VERSION ""

NS_ :

BS_:

BU_: FBD_HL IPB_App1 FBD_HM FBD_HR FBD_Miko FBD_MM FBD_Trunk FBD_VL FBD_VM FBD_VR Diagnosetool_CAN_FD_IPB_41

BO_ 435 StatusUWBRangingFBD_VR: 32 FBD_VR
 SG_ StatusUWBRangingFBD_VR_SessionID : 0|8@1+ (1.0,0) [0|252] "" FBD_HL,FBD_HM,FBD_HR,FBD_MM,FBD_Miko,FBD_Trunk,FBD_VL,FBD_VM,IPB_App1
 SG_ StatusUWBRangingFBD_VR_TimeOfFli : 8|16@1+ (15.65,0) [0|1000000] "ps" FBD_HL,FBD_HM,FBD_HR,FBD_MM,FBD_Miko,FBD_Trunk,FBD_VL,FBD_VM,IPB_App1
 SG_ StatusUWBRangingFBD_VR_RangingBl : 24|16@1+ (1.0,0) [0|65532] "" FBD_HL,FBD_HM,FBD_HR,FBD_MM,FBD_Miko,FBD_Trunk,FBD_VL,FBD_VM,IPB_App1
 SG_ StatusUWBRangingFBD_VR_RangingRo : 40|8@1+ (1.0,0) [0|252] "" FBD_HL,FBD_HM,FBD_HR,FBD_MM,FBD_Miko,FBD_Trunk,FBD_VL,FBD_VM,IPB_App1
 SG_ StatusUWBRangingFBD_VR_OverallRe : 48|8@1+ (0.5,-127) [-127|-1] "dB" FBD_HL,FBD_HM,FBD_HR,FBD_MM,FBD_Miko,FBD_Trunk,FBD_VL,FBD_VM,IPB_App1
 SG_ StatusUWBRangingFBD_VR_FirstPath : 56|8@1+ (0.5,-127) [-127|-1] "dB" FBD_HL,FBD_HM,FBD_HR,FBD_MM,FBD_Miko,FBD_Trunk,FBD_VL,FBD_VM,IPB_App1
 SG_ StatusUWBRangingFBD_VR_AngleOfAr : 64|8@1+ (1.0,-90) [-90|90] "°" FBD_HL,FBD_HM,FBD_HR,FBD_MM,FBD_Miko,FBD_Trunk,FBD_VL,FBD_VM,IPB_App1
 SG_ StatusUWBRangingFBD_VR_PhaseDiff : 72|8@1+ (1.0,-90) [-90|90] "°" FBD_HL,FBD_HM,FBD_HR,FBD_MM,FBD_Miko,FBD_Trunk,FBD_VL,FBD_VM,IPB_App1
 SG_ StatusUWBRangingFBD_VR_Strongest : 80|8@1+ (0.5,-127) [-127|-1] "dB" FBD_HL,FBD_HM,FBD_HR,FBD_MM,FBD_Miko,FBD_Trunk,FBD_VL,FBD_VM,IPB_App1
 SG_ StatusUWBRangingFBD_VR_BLE_RSSI : 88|8@1+ (0.5,-127) [-127|-1] "dB" FBD_HL,FBD_HM,FBD_HR,FBD_MM,FBD_Miko,FBD_Trunk,FBD_VL,FBD_VM,IPB_App1
 SG_ StatusUWBRangingFBD_VR_Stronge_2 : 96|8@1+ (0.5,0) [0|125] "ns" FBD_HL,FBD_HM,FBD_HR,FBD_MM,FBD_Miko,FBD_Trunk,FBD_VL,FBD_VM,IPB_App1
 SG_ StatusUWBRangingFBD_VR_PDoA_SNR : 104|8@1+ (0.5,0) [0|126] "dB" FBD_HL,FBD_HM,FBD_HR,FBD_MM,FBD_Miko,FBD_Trunk,FBD_VL,FBD_VM,IPB_App1
 SG_ StatusUWBRangingFBD_VR_DutyCycle : 112|8@1+ (1.0,0) [0|100] "%" FBD_HL,FBD_HM,FBD_HR,FBD_MM,FBD_Miko,FBD_Trunk,FBD_VL,FBD_VM,IPB_App1
 SG_ StatusUWBRangingFBD_VR_FinalData : 120|4@1+ (1.0,0) [0|12] "" FBD_HL,FBD_HM,FBD_HR,FBD_MM,FBD_Miko,FBD_Trunk,FBD_VL,FBD_VM,IPB_App1
 SG_ StatusUWBRangingFBD_VR_Antenna : 124|4@1+ (1,0) [0|0] "" FBD_HL,FBD_HM,FBD_HR,FBD_MM,FBD_Miko,FBD_Trunk,FBD_VL,FBD_VM,IPB_App1
 SG_ StatusUWBRangingFBD_VR_Status1 : 128|8@1+ (1,0) [0|0] "" FBD_HL,FBD_HM,FBD_HR,FBD_MM,FBD_Miko,FBD_Trunk,FBD_VL,FBD_VM,IPB_App1
 SG_ StatusUWBRangingFBD_VR_Status2 : 136|8@1+ (1.0,0) [0|252] "" FBD_HL,FBD_HM,FBD_HR,FBD_MM,FBD_Miko,FBD_Trunk,FBD_VL,FBD_VM,IPB_App1
 SG_ StatusUWBRangingFBD_VR_Status3 : 144|8@1+ (1.0,0) [0|252] "" FBD_HL,FBD_HM,FBD_HR,FBD_MM,FBD_Miko,FBD_Trunk,FBD_VL,FBD_VM,IPB_App1
 SG_ StatusUWBRangingFBD_VR_Status4 : 152|8@1+ (1.0,0) [0|252] "" FBD_HL,FBD_HM,FBD_HR,FBD_MM,FBD_Miko,FBD_Trunk,FBD_VL,FBD_VM,IPB_App1
 SG_ StatusUWBRangingFBD_VR_IV00 : 160|8@1+ (1.0,0) [0|255] "" FBD_HL,FBD_HM,FBD_HR,FBD_MM,FBD_Miko,FBD_Trunk,FBD_VL,FBD_VM,IPB_App1
 SG_ StatusUWBRangingFBD_VR_IV01 : 168|8@1+ (1.0,0) [0|255] "" FBD_HL,FBD_HM,FBD_HR,FBD_MM,FBD_Miko,FBD_Trunk,FBD_VL,FBD_VM,IPB_App1
 SG_ StatusUWBRangingFBD_VR_IV02 : 176|8@1+ (1.0,0) [0|255] "" FBD_HL,FBD_HM,FBD_HR,FBD_MM,FBD_Miko,FBD_Trunk,FBD_VL,FBD_VM,IPB_App1
 SG_ StatusUWBRangingFBD_VR_IV03 : 184|8@1+ (1.0,0) [0|255] "" FBD_HL,FBD_HM,FBD_HR,FBD_MM,FBD_Miko,FBD_Trunk,FBD_VL,FBD_VM,IPB_App1
 SG_ StatusUWBRangingFBD_VR_Sign00 : 192|8@1+ (1.0,0) [0|255] "" FBD_HL,FBD_HM,FBD_HR,FBD_MM,FBD_Miko,FBD_Trunk,FBD_VL,FBD_VM,IPB_App1
 SG_ StatusUWBRangingFBD_VR_Sign01 : 200|8@1+ (1.0,0) [0|255] "" FBD_HL,FBD_HM,FBD_HR,FBD_MM,FBD_Miko,FBD_Trunk,FBD_VL,FBD_VM,IPB_App1
 SG_ StatusUWBRangingFBD_VR_Sign02 : 208|8@1+ (1.0,0) [0|255] "" FBD_HL,FBD_HM,FBD_HR,FBD_MM,FBD_Miko,FBD_Trunk,FBD_VL,FBD_VM,IPB_App1
 SG_ StatusUWBRangingFBD_VR_Sign03 : 216|8@1+ (1.0,0) [0|255] "" FBD_HL,FBD_HM,FBD_HR,FBD_MM,FBD_Miko,FBD_Trunk,FBD_VL,FBD_VM,IPB_App1
 SG_ StatusUWBRangingFBD_VR_Sign04 : 224|8@1+ (1.0,0) [0|255] "" FBD_HL,FBD_HM,FBD_HR,FBD_MM,FBD_Miko,FBD_Trunk,FBD_VL,FBD_VM,IPB_App1
 SG_ StatusUWBRangingFBD_VR_Sign05 : 232|8@1+ (1.0,0) [0|255] "" FBD_HL,FBD_HM,FBD_HR,FBD_MM,FBD_Miko,FBD_Trunk,FBD_VL,FBD_VM,IPB_App1
 SG_ StatusUWBRangingFBD_VR_Sign06 : 240|8@1+ (1.0,0) [0|255] "" FBD_HL,FBD_HM,FBD_HR,FBD_MM,FBD_Miko,FBD_Trunk,FBD_VL,FBD_VM,IPB_App1
 SG_ StatusUWBRangingFBD_VR_Sign07 : 248|8@1+ (1.0,0) [0|255] "" FBD_HL,FBD_HM,FBD_HR,FBD_MM,FBD_Miko,FBD_Trunk,FBD_VL,FBD_VM,IPB_App1

BO_ 456 StatusUWBRangingFDD1FBD_HL: 64 FBD_HL
 SG_ StatusUWBRangingFDD1FBD_HL_Sessi : 0|8@1+ (1.0,0) [0|252] "" FBD_HM,FBD_HR,FBD_MM,FBD_Miko,FBD_Trunk,FBD_VL,FBD_VM,FBD_VR,IPB_App1
 SG_ StatusUWBRangingFDD1FBD_HL_UWBSe : 8|32@1+ (1.0,0) [0|4294967292] "" FBD_HM,FBD_HR,FBD_MM,FBD_Miko,FBD_Trunk,FBD_VL,FBD_VM,FBD_VR,IPB_App1
 SG_ StatusUWBRangingFDD1FBD_HL_Rangi : 40|16@1+ (1.0,0) [0|65532] "" FBD_HM,FBD_HR,FBD_MM,FBD_Miko,FBD_Trunk,FBD_VL,FBD_VM,FBD_VR,IPB_App1
 SG_ StatusUWBRangingFDD1FBD_HL_Hoppi : 56|8@1+ (1.0,0) [0|252] "" FBD_HM,FBD_HR,FBD_MM,FBD_Miko,FBD_Trunk,FBD_VL,FBD_VM,FBD_VR,IPB_App1
 SG_ StatusUWBRangingFDD1FBD_HL_Round : 64|16@1+ (1.0,0) [0|65532] "" FBD_HM,FBD_HR,FBD_MM,FBD_Miko,FBD_Trunk,FBD_VL,FBD_VM,FBD_VR,IPB_App1
 SG_ StatusUWBRangingFDD1FBD_HL_Final : 80|32@1+ (1.0,0) [0|4294967292] "" FBD_HM,FBD_HR,FBD_MM,FBD_Miko,FBD_Trunk,FBD_VL,FBD_VM,FBD_VR,IPB_App1
 SG_ StatusUWBRangingFDD1FBD_HL_Fin_2 : 112|32@1+ (1.0,0) [0|4294967292] "" FBD_HM,FBD_HR,FBD_MM,FBD_Miko,FBD_Trunk,FBD_VL,FBD_VM,FBD_VR,IPB_App1
 SG_ StatusUWBRangingFDD1FBD_HL_Numbe : 144|8@1+ (1.0,0) [0|252] "" FBD_HM,FBD_HR,FBD_MM,FBD_Miko,FBD_Trunk,FBD_VL,FBD_VM,FBD_VR,IPB_App1
 SG_ StatusUWBRangingFDD1FBD_HL_Index : 152|8@1+ (1.0,0) [0|252] "" FBD_HM,FBD_HR,FBD_MM,FBD_Miko,FBD_Trunk,FBD_VL,FBD_VM,FBD_VR,IPB_App1
 SG_ StatusUWBRangingFDD1FBD_HL_TimeS : 160|32@1+ (1.0,0) [0|4294967292] "" FBD_HM,FBD_HR,FBD_MM,FBD_Miko,FBD_Trunk,FBD_VL,FBD_VM,FBD_VR,IPB_App1
 SG_ StatusUWBRangingFDD1FBD_HL_Tim_2 : 192|8@1+ (1.0,0) [0|252] "" FBD_HM,FBD_HR,FBD_MM,FBD_Miko,FBD_Trunk,FBD_VL,FBD_VM,FBD_VR,IPB_App1
 SG_ StatusUWBRangingFDD1FBD_HL_Statu : 200|8@1+ (1.0,0) [0|252] "" FBD_HM,FBD_HR,FBD_MM,FBD_Miko,FBD_Trunk,FBD_VL,FBD_VM,FBD_VR,IPB_App1
 SG_ StatusUWBRangingFDD1FBD_HL_Ind_2 : 208|8@1+ (1.0,0) [0|252] "" FBD_HM,FBD_HR,FBD_MM,FBD_Miko,FBD_Trunk,FBD_VL,FBD_VM,FBD_VR,IPB_App1
 SG_ StatusUWBRangingFDD1FBD_HL_Tim_3 : 216|32@1+ (1.0,0) [0|4294967292] "" FBD_HM,FBD_HR,FBD_MM,FBD_Miko,FBD_Trunk,FBD_VL,FBD_VM,FBD_VR,IPB_App1
 SG_ StatusUWBRangingFDD1FBD_HL_Tim_4 : 248|8@1+ (1.0,0) [0|252] "" FBD_HM,FBD_HR,FBD_MM,FBD_Miko,FBD_Trunk,FBD_VL,FBD_VM,FBD_VR,IPB_App1
 SG_ StatusUWBRangingFDD1FBD_HL_Sta_2 : 256|8@1+ (1.0,0) [0|252] "" FBD_HM,FBD_HR,FBD_MM,FBD_Miko,FBD_Trunk,FBD_VL,FBD_VM,FBD_VR,IPB_App1
 SG_ StatusUWBRangingFDD1FBD_HL_Ind_3 : 264|8@1+ (1.0,0) [0|252] "" FBD_HM,FBD_HR,FBD_MM,FBD_Miko,FBD_Trunk,FBD_VL,FBD_VM,FBD_VR,IPB_App1
 SG_ StatusUWBRangingFDD1FBD_HL_Tim_5 : 272|32@1+ (1.0,0) [0|4294967292] "" FBD_HM,FBD_HR,FBD_MM,FBD_Miko,FBD_Trunk,FBD_VL,FBD_VM,FBD_VR,IPB_App1
 SG_ StatusUWBRangingFDD1FBD_HL_Tim_6 : 304|8@1+ (1.0,0) [0|252] "" FBD_HM,FBD_HR,FBD_MM,FBD_Miko,FBD_Trunk,FBD_VL,FBD_VM,FBD_VR,IPB_App1
 SG_ StatusUWBRangingFDD1FBD_HL_Sta_3 : 312|8@1+ (1.0,0) [0|252] "" FBD_HM,FBD_HR,FBD_MM,FBD_Miko,FBD_Trunk,FBD_VL,FBD_VM,FBD_VR,IPB_App1
 SG_ StatusUWBRangingFDD1FBD_HL_Ind_4 : 320|8@1+ (1.0,0) [0|252] "" FBD_HM,FBD_HR,FBD_MM,FBD_Miko,FBD_Trunk,FBD_VL,FBD_VM,FBD_VR,IPB_App1
 SG_ StatusUWBRangingFDD1FBD_HL_Tim_7 : 328|32@1+ (1.0,0) [0|4294967292] "" FBD_HM,FBD_HR,FBD_MM,FBD_Miko,FBD_Trunk,FBD_VL,FBD_VM,FBD_VR,IPB_App1
 SG_ StatusUWBRangingFDD1FBD_HL_Tim_8 : 360|8@1+ (1.0,0) [0|252] "" FBD_HM,FBD_HR,FBD_MM,FBD_Miko,FBD_Trunk,FBD_VL,FBD_VM,FBD_VR,IPB_App1
 SG_ StatusUWBRangingFDD1FBD_HL_Sta_4 : 368|8@1+ (1.0,0) [0|252] "" FBD_HM,FBD_HR,FBD_MM,FBD_Miko,FBD_Trunk,FBD_VL,FBD_VM,FBD_VR,IPB_App1
 SG_ StatusUWBRangingFDD1FBD_HL_Ind_5 : 376|8@1+ (1.0,0) [0|252] "" FBD_HM,FBD_HR,FBD_MM,FBD_Miko,FBD_Trunk,FBD_VL,FBD_VM,FBD_VR,IPB_App1
 SG_ StatusUWBRangingFDD1FBD_HL_Tim_9 : 384|32@1+ (1.0,0) [0|4294967292] "" FBD_HM,FBD_HR,FBD_MM,FBD_Miko,FBD_Trunk,FBD_VL,FBD_VM,FBD_VR,IPB_App1
 SG_ StatusUWBRangingFDD1FBD_HL_Ti_10 : 416|8@1+ (1.0,0) [0|252] "" FBD_HM,FBD_HR,FBD_MM,FBD_Miko,FBD_Trunk,FBD_VL,FBD_VM,FBD_VR,IPB_App1
 SG_ StatusUWBRangingFDD1FBD_HL_Sta_5 : 424|8@1+ (1.0,0) [0|252] "" FBD_HM,FBD_HR,FBD_MM,FBD_Miko,FBD_Trunk,FBD_VL,FBD_VM,FBD_VR,IPB_App1
 SG_ StatusUWBRangingFDD1FBD_HL_Ind_6 : 432|8@1+ (1.0,0) [0|252] "" FBD_HM,FBD_HR,FBD_MM,FBD_Miko,FBD_Trunk,FBD_VL,FBD_VM,FBD_VR,IPB_App1
 SG_ StatusUWBRangingFDD1FBD_HL_Ti_11 : 440|32@1+ (1.0,0) [0|4294967292] "" FBD_HM,FBD_HR,FBD_MM,FBD_Miko,FBD_Trunk,FBD_VL,FBD_VM,FBD_VR,IPB_App1
 SG_ StatusUWBRangingFDD1FBD_HL_Ti_12 : 472|8@1+ (1.0,0) [0|252] "" FBD_HM,FBD_HR,FBD_MM,FBD_Miko,FBD_Trunk,FBD_VL,FBD_VM,FBD_VR,IPB_App1
 SG_ StatusUWBRangingFDD1FBD_HL_Sta_6 : 480|8@1+ (1.0,0) [0|252] "" FBD_HM,FBD_HR,FBD_MM,FBD_Miko,FBD_Trunk,FBD_VL,FBD_VM,FBD_VR,IPB_App1
 SG_ StatusUWBRangingFDD1FBD_HL_IV0 : 488|8@1+ (1.0,0) [0|255] "" FBD_HM,FBD_HR,FBD_MM,FBD_Miko,FBD_Trunk,FBD_VL,FBD_VM,FBD_VR,IPB_App1
 SG_ StatusUWBRangingFDD1FBD_HL_IV1 : 496|8@1+ (1.0,0) [0|255] "" FBD_HM,FBD_HR,FBD_MM,FBD_Miko,FBD_Trunk,FBD_VL,FBD_VM,FBD_VR,IPB_App1

BO_ 451 StatusUWBRangingFDD1FBD_HM: 64 FBD_HM
 SG_ StatusUWBRangingFDD1FBD_HM_Sessi : 0|8@1+ (1.0,0) [0|252] "" FBD_HL,FBD_HR,FBD_MM,FBD_Miko,FBD_Trunk,FBD_VL,FBD_VM,FBD_VR,IPB_App1
 SG_ StatusUWBRangingFDD1FBD_HM_UWBSe : 8|32@1+ (1.0,0) [0|4294967292] "" FBD_HL,FBD_HR,FBD_MM,FBD_Miko,FBD_Trunk,FBD_VL,FBD_VM,FBD_VR,IPB_App1
 SG_ StatusUWBRangingFDD1FBD_HM_Rangi : 40|16@1+ (1.0,0) [0|65532] "" FBD_HL,FBD_HR,FBD_MM,FBD_Miko,FBD_Trunk,FBD_VL,FBD_VM,FBD_VR,IPB_App1
 SG_ StatusUWBRangingFDD1FBD_HM_Hoppi : 56|8@1+ (1.0,0) [0|252] "" FBD_HL,FBD_HR,FBD_MM,FBD_Miko,FBD_Trunk,FBD_VL,FBD_VM,FBD_VR,IPB_App1
 SG_ StatusUWBRangingFDD1FBD_HM_Round : 64|16@1+ (1.0,0) [0|65532] "" FBD_HL,FBD_HR,FBD_MM,FBD_Miko,FBD_Trunk,FBD_VL,FBD_VM,FBD_VR,IPB_App1
 SG_ StatusUWBRangingFDD1FBD_HM_Final : 80|32@1+ (1.0,0) [0|4294967292] "" FBD_HL,FBD_HR,FBD_MM,FBD_Miko,FBD_Trunk,FBD_VL,FBD_VM,FBD_VR,IPB_App1
 SG_ StatusUWBRangingFDD1FBD_HM_Fin_2 : 112|32@1+ (1.0,0) [0|4294967292] "" FBD_HL,FBD_HR,FBD_MM,FBD_Miko,FBD_Trunk,FBD_VL,FBD_VM,FBD_VR,IPB_App1
 SG_ StatusUWBRangingFDD1FBD_HM_Numbe : 144|8@1+ (1.0,0) [0|252] "" FBD_HL,FBD_HR,FBD_MM,FBD_Miko,FBD_Trunk,FBD_VL,FBD_VM,FBD_VR,IPB_App1
 SG_ StatusUWBRangingFDD1FBD_HM_Index : 152|8@1+ (1.0,0) [0|252] "" FBD_HL,FBD_HR,FBD_MM,FBD_Miko,FBD_Trunk,FBD_VL,FBD_VM,FBD_VR,IPB_App1
 SG_ StatusUWBRangingFDD1FBD_HM_TimeS : 160|32@1+ (1.0,0) [0|4294967292] "" FBD_HL,FBD_HR,FBD_MM,FBD_Miko,FBD_Trunk,FBD_VL,FBD_VM,FBD_VR,IPB_App1
 SG_ StatusUWBRangingFDD1FBD_HM_Tim_2 : 192|8@1+ (1.0,0) [0|252] "" FBD_HL,FBD_HR,FBD_MM,FBD_Miko,FBD_Trunk,FBD_VL,FBD_VM,FBD_VR,IPB_App1
 SG_ StatusUWBRangingFDD1FBD_HM_Statu : 200|8@1+ (1.0,0) [0|252] "" FBD_HL,FBD_HR,FBD_MM,FBD_Miko,FBD_Trunk,FBD_VL,FBD_VM,FBD_VR,IPB_App1
 SG_ StatusUWBRangingFDD1FBD_HM_Ind_2 : 208|8@1+ (1.0,0) [0|252] "" FBD_HL,FBD_HR,FBD_MM,FBD_Miko,FBD_Trunk,FBD_VL,FBD_VM,FBD_VR,IPB_App1
 SG_ StatusUWBRangingFDD1FBD_HM_Tim_3 : 216|32@1+ (1.0,0) [0|4294967292] "" FBD_HL,FBD_HR,FBD_MM,FBD_Miko,FBD_Trunk,FBD_VL,FBD_VM,FBD_VR,IPB_App1
 SG_ StatusUWBRangingFDD1FBD_HM_Tim_4 : 248|8@1+ (1.0,0) [0|252] "" FBD_HL,FBD_HR,FBD_MM,FBD_Miko,FBD_Trunk,FBD_VL,FBD_VM,FBD_VR,IPB_App1
 SG_ StatusUWBRangingFDD1FBD_HM_Sta_2 : 256|8@1+ (1.0,0) [0|252] "" FBD_HL,FBD_HR,FBD_MM,FBD_Miko,FBD_Trunk,FBD_VL,FBD_VM,FBD_VR,IPB_App1
 SG_ StatusUWBRangingFDD1FBD_HM_Ind_3 : 264|8@1+ (1.0,0) [0|252] "" FBD_HL,FBD_HR,FBD_MM,FBD_Miko,FBD_Trunk,FBD_VL,FBD_VM,FBD_VR,IPB_App1
 SG_ StatusUWBRangingFDD1FBD_HM_Tim_5 : 272|32@1+ (1.0,0) [0|4294967292] "" FBD_HL,FBD_HR,FBD_MM,FBD_Miko,FBD_Trunk,FBD_VL,FBD_VM,FBD_VR,IPB_App1
 SG_ StatusUWBRangingFDD1FBD_HM_Tim_6 : 304|8@1+ (1.0,0) [0|252] "" FBD_HL,FBD_HR,FBD_MM,FBD_Miko,FBD_Trunk,FBD_VL,FBD_VM,FBD_VR,IPB_App1
 SG_ StatusUWBRangingFDD1FBD_HM_Sta_3 : 312|8@1+ (1.0,0) [0|252] "" FBD_HL,FBD_HR,FBD_MM,FBD_Miko,FBD_Trunk,FBD_VL,FBD_VM,FBD_VR,IPB_App1
 SG_ StatusUWBRangingFDD1FBD_HM_Ind_4 : 320|8@1+ (1.0,0) [0|252] "" FBD_HL,FBD_HR,FBD_MM,FBD_Miko,FBD_Trunk,FBD_VL,FBD_VM,FBD_VR,IPB_App1
 SG_ StatusUWBRangingFDD1FBD_HM_Tim_7 : 328|32@1+ (1.0,0) [0|4294967292] "" FBD_HL,FBD_HR,FBD_MM,FBD_Miko,FBD_Trunk,FBD_VL,FBD_VM,FBD_VR,IPB_App1
 SG_ StatusUWBRangingFDD1FBD_HM_Tim_8 : 360|8@1+ (1.0,0) [0|252] "" FBD_HL,FBD_HR,FBD_MM,FBD_Miko,FBD_Trunk,FBD_VL,FBD_VM,FBD_VR,IPB_App1
 SG_ StatusUWBRangingFDD1FBD_HM_Sta_4 : 368|8@1+ (1.0,0) [0|252] "" FBD_HL,FBD_HR,FBD_MM,FBD_Miko,FBD_Trunk,FBD_VL,FBD_VM,FBD_VR,IPB_App1
 SG_ StatusUWBRangingFDD1FBD_HM_Ind_5 : 376|8@1+ (1.0,0) [0|252] "" FBD_HL,FBD_HR,FBD_MM,FBD_Miko,FBD_Trunk,FBD_VL,FBD_VM,FBD_VR,IPB_App1
 SG_ StatusUWBRangingFDD1FBD_HM_Tim_9 : 384|32@1+ (1.0,0) [0|4294967292] "" FBD_HL,FBD_HR,FBD_MM,FBD_Miko,FBD_Trunk,FBD_VL,FBD_VM,FBD_VR,IPB_App1
 SG_ StatusUWBRangingFDD1FBD_HM_Ti_10 : 416|8@1+ (1.0,0) [0|252] "" FBD_HL,FBD_HR,FBD_MM,FBD_Miko,FBD_Trunk,FBD_VL,FBD_VM,FBD_VR,IPB_App1
 SG_ StatusUWBRangingFDD1FBD_HM_Sta_5 : 424|8@1+ (1.0,0) [0|252] "" FBD_HL,FBD_HR,FBD_MM,FBD_Miko,FBD_Trunk,FBD_VL,FBD_VM,FBD_VR,IPB_App1
 SG_ StatusUWBRangingFDD1FBD_HM_Ind_6 : 432|8@1+ (1.0,0) [0|252] "" FBD_HL,FBD_HR,FBD_MM,FBD_Miko,FBD_Trunk,FBD_VL,FBD_VM,FBD_VR,IPB_App1
 SG_ StatusUWBRangingFDD1FBD_HM_Ti_11 : 440|32@1+ (1.0,0) [0|4294967292] "" FBD_HL,FBD_HR,FBD_MM,FBD_Miko,FBD_Trunk,FBD_VL,FBD_VM,FBD_VR,IPB_App1
 SG_ StatusUWBRangingFDD1FBD_HM_Ti_12 : 472|8@1+ (1.0,0) [0|252] "" FBD_HL,FBD_HR,FBD_MM,FBD_Miko,FBD_Trunk,FBD_VL,FBD_VM,FBD_VR,IPB_App1
 SG_ StatusUWBRangingFDD1FBD_HM_Sta_6 : 480|8@1+ (1.0,0) [0|252] "" FBD_HL,FBD_HR,FBD_MM,FBD_Miko,FBD_Trunk,FBD_VL,FBD_VM,FBD_VR,IPB_App1
 SG_ StatusUWBRangingFDD1FBD_HM_IV0 : 488|8@1+ (1.0,0) [0|255] "" FBD_HL,FBD_HR,FBD_MM,FBD_Miko,FBD_Trunk,FBD_VL,FBD_VM,FBD_VR,IPB_App1
 SG_ StatusUWBRangingFDD1FBD_HM_IV1 : 496|8@1+ (1.0,0) [0|255] "" FBD_HL,FBD_HR,FBD_MM,FBD_Miko,FBD_Trunk,FBD_VL,FBD_VM,FBD_VR,IPB_App1

BO_ 457 StatusUWBRangingFDD1FBD_HR: 64 FBD_HR
 SG_ StatusUWBRangingFDD1FBD_HR_Sessi : 0|8@1+ (1.0,0) [0|252] "" FBD_HL,FBD_HM,FBD_MM,FBD_Miko,FBD_Trunk,FBD_VL,FBD_VM,FBD_VR,IPB_App1
 SG_ StatusUWBRangingFDD1FBD_HR_UWBSe : 8|32@1+ (1.0,0) [0|4294967292] "" FBD_HL,FBD_HM,FBD_MM,FBD_Miko,FBD_Trunk,FBD_VL,FBD_VM,FBD_VR,IPB_App1
 SG_ StatusUWBRangingFDD1FBD_HR_Rangi : 40|16@1+ (1.0,0) [0|65532] "" FBD_HL,FBD_HM,FBD_MM,FBD_Miko,FBD_Trunk,FBD_VL,FBD_VM,FBD_VR,IPB_App1
 SG_ StatusUWBRangingFDD1FBD_HR_Hoppi : 56|8@1+ (1.0,0) [0|252] "" FBD_HL,FBD_HM,FBD_MM,FBD_Miko,FBD_Trunk,FBD_VL,FBD_VM,FBD_VR,IPB_App1
 SG_ StatusUWBRangingFDD1FBD_HR_Round : 64|16@1+ (1.0,0) [0|65532] "" FBD_HL,FBD_HM,FBD_MM,FBD_Miko,FBD_Trunk,FBD_VL,FBD_VM,FBD_VR,IPB_App1
 SG_ StatusUWBRangingFDD1FBD_HR_Final : 80|32@1+ (1.0,0) [0|4294967292] "" FBD_HL,FBD_HM,FBD_MM,FBD_Miko,FBD_Trunk,FBD_VL,FBD_VM,FBD_VR,IPB_App1
 SG_ StatusUWBRangingFDD1FBD_HR_Fin_2 : 112|32@1+ (1.0,0) [0|4294967292] "" FBD_HL,FBD_HM,FBD_MM,FBD_Miko,FBD_Trunk,FBD_VL,FBD_VM,FBD_VR,IPB_App1
 SG_ StatusUWBRangingFDD1FBD_HR_Numbe : 144|8@1+ (1.0,0) [0|252] "" FBD_HL,FBD_HM,FBD_MM,FBD_Miko,FBD_Trunk,FBD_VL,FBD_VM,FBD_VR,IPB_App1
 SG_ StatusUWBRangingFDD1FBD_HR_Index : 152|8@1+ (1.0,0) [0|252] "" FBD_HL,FBD_HM,FBD_MM,FBD_Miko,FBD_Trunk,FBD_VL,FBD_VM,FBD_VR,IPB_App1
 SG_ StatusUWBRangingFDD1FBD_HR_TimeS : 160|32@1+ (1.0,0) [0|4294967292] "" FBD_HL,FBD_HM,FBD_MM,FBD_Miko,FBD_Trunk,FBD_VL,FBD_VM,FBD_VR,IPB_App1
 SG_ StatusUWBRangingFDD1FBD_HR_Tim_2 : 192|8@1+ (1.0,0) [0|252] "" FBD_HL,FBD_HM,FBD_MM,FBD_Miko,FBD_Trunk,FBD_VL,FBD_VM,FBD_VR,IPB_App1
 SG_ StatusUWBRangingFDD1FBD_HR_Statu : 200|8@1+ (1.0,0) [0|252] "" FBD_HL,FBD_HM,FBD_MM,FBD_Miko,FBD_Trunk,FBD_VL,FBD_VM,FBD_VR,IPB_App1
 SG_ StatusUWBRangingFDD1FBD_HR_Ind_2 : 208|8@1+ (1.0,0) [0|252] "" FBD_HL,FBD_HM,FBD_MM,FBD_Miko,FBD_Trunk,FBD_VL,FBD_VM,FBD_VR,IPB_App1
 SG_ StatusUWBRangingFDD1FBD_HR_Tim_3 : 216|32@1+ (1.0,0) [0|4294967292] "" FBD_HL,FBD_HM,FBD_MM,FBD_Miko,FBD_Trunk,FBD_VL,FBD_VM,FBD_VR,IPB_App1
 SG_ StatusUWBRangingFDD1FBD_HR_Tim_4 : 248|8@1+ (1.0,0) [0|252] "" FBD_HL,FBD_HM,FBD_MM,FBD_Miko,FBD_Trunk,FBD_VL,FBD_VM,FBD_VR,IPB_App1
 SG_ StatusUWBRangingFDD1FBD_HR_Sta_2 : 256|8@1+ (1.0,0) [0|252] "" FBD_HL,FBD_HM,FBD_MM,FBD_Miko,FBD_Trunk,FBD_VL,FBD_VM,FBD_VR,IPB_App1
 SG_ StatusUWBRangingFDD1FBD_HR_Ind_3 : 264|8@1+ (1.0,0) [0|252] "" FBD_HL,FBD_HM,FBD_MM,FBD_Miko,FBD_Trunk,FBD_VL,FBD_VM,FBD_VR,IPB_App1
 SG_ StatusUWBRangingFDD1FBD_HR_Tim_5 : 272|32@1+ (1.0,0) [0|4294967292] "" FBD_HL,FBD_HM,FBD_MM,FBD_Miko,FBD_Trunk,FBD_VL,FBD_VM,FBD_VR,IPB_App1
 SG_ StatusUWBRangingFDD1FBD_HR_Tim_6 : 304|8@1+ (1.0,0) [0|252] "" FBD_HL,FBD_HM,FBD_MM,FBD_Miko,FBD_Trunk,FBD_VL,FBD_VM,FBD_VR,IPB_App1
 SG_ StatusUWBRangingFDD1FBD_HR_Sta_3 : 312|8@1+ (1.0,0) [0|252] "" FBD_HL,FBD_HM,FBD_MM,FBD_Miko,FBD_Trunk,FBD_VL,FBD_VM,FBD_VR,IPB_App1
 SG_ StatusUWBRangingFDD1FBD_HR_Ind_4 : 320|8@1+ (1.0,0) [0|252] "" FBD_HL,FBD_HM,FBD_MM,FBD_Miko,FBD_Trunk,FBD_VL,FBD_VM,FBD_VR,IPB_App1
 SG_ StatusUWBRangingFDD1FBD_HR_Tim_7 : 328|32@1+ (1.0,0) [0|4294967292] "" FBD_HL,FBD_HM,FBD_MM,FBD_Miko,FBD_Trunk,FBD_VL,FBD_VM,FBD_VR,IPB_App1
 SG_ StatusUWBRangingFDD1FBD_HR_Tim_8 : 360|8@1+ (1.0,0) [0|252] "" FBD_HL,FBD_HM,FBD_MM,FBD_Miko,FBD_Trunk,FBD_VL,FBD_VM,FBD_VR,IPB_App1
 SG_ StatusUWBRangingFDD1FBD_HR_Sta_4 : 368|8@1+ (1.0,0) [0|252] "" FBD_HL,FBD_HM,FBD_MM,FBD_Miko,FBD_Trunk,FBD_VL,FBD_VM,FBD_VR,IPB_App1
 SG_ StatusUWBRangingFDD1FBD_HR_Ind_5 : 376|8@1+ (1.0,0) [0|252] "" FBD_HL,FBD_HM,FBD_MM,FBD_Miko,FBD_Trunk,FBD_VL,FBD_VM,FBD_VR,IPB_App1
 SG_ StatusUWBRangingFDD1FBD_HR_Tim_9 : 384|32@1+ (1.0,0) [0|4294967292] "" FBD_HL,FBD_HM,FBD_MM,FBD_Miko,FBD_Trunk,FBD_VL,FBD_VM,FBD_VR,IPB_App1
 SG_ StatusUWBRangingFDD1FBD_HR_Ti_10 : 416|8@1+ (1.0,0) [0|252] "" FBD_HL,FBD_HM,FBD_MM,FBD_Miko,FBD_Trunk,FBD_VL,FBD_VM,FBD_VR,IPB_App1
 SG_ StatusUWBRangingFDD1FBD_HR_Sta_5 : 424|8@1+ (1.0,0) [0|252] "" FBD_HL,FBD_HM,FBD_MM,FBD_Miko,FBD_Trunk,FBD_VL,FBD_VM,FBD_VR,IPB_App1
 SG_ StatusUWBRangingFDD1FBD_HR_Ind_6 : 432|8@1+ (1.0,0) [0|252] "" FBD_HL,FBD_HM,FBD_MM,FBD_Miko,FBD_Trunk,FBD_VL,FBD_VM,FBD_VR,IPB_App1
 SG_ StatusUWBRangingFDD1FBD_HR_Ti_11 : 440|32@1+ (1.0,0) [0|4294967292] "" FBD_HL,FBD_HM,FBD_MM,FBD_Miko,FBD_Trunk,FBD_VL,FBD_VM,FBD_VR,IPB_App1
 SG_ StatusUWBRangingFDD1FBD_HR_Ti_12 : 472|8@1+ (1.0,0) [0|252] "" FBD_HL,FBD_HM,FBD_MM,FBD_Miko,FBD_Trunk,FBD_VL,FBD_VM,FBD_VR,IPB_App1
 SG_ StatusUWBRangingFDD1FBD_HR_Sta_6 : 480|8@1+ (1.0,0) [0|252] "" FBD_HL,FBD_HM,FBD_MM,FBD_Miko,FBD_Trunk,FBD_VL,FBD_VM,FBD_VR,IPB_App1
 SG_ StatusUWBRangingFDD1FBD_HR_IV0 : 488|8@1+ (1.0,0) [0|255] "" FBD_HL,FBD_HM,FBD_MM,FBD_Miko,FBD_Trunk,FBD_VL,FBD_VM,FBD_VR,IPB_App1
 SG_ StatusUWBRangingFDD1FBD_HR_IV1 : 496|8@1+ (1.0,0) [0|255] "" FBD_HL,FBD_HM,FBD_MM,FBD_Miko,FBD_Trunk,FBD_VL,FBD_VM,FBD_VR,IPB_App1

BO_ 452 StatusUWBRangingFDD1FBD_Miko: 64 FBD_Miko
 SG_ StatusUWBRangingFDD1FBD_Miko_Ses : 0|8@1+ (1.0,0) [0|252] "" FBD_HL,FBD_HM,FBD_HR,FBD_MM,FBD_Trunk,FBD_VL,FBD_VM,FBD_VR,IPB_App1
 SG_ StatusUWBRangingFDD1FBD_Miko_UWB : 8|32@1+ (1.0,0) [0|4294967292] "" FBD_HL,FBD_HM,FBD_HR,FBD_MM,FBD_Trunk,FBD_VL,FBD_VM,FBD_VR,IPB_App1
 SG_ StatusUWBRangingFDD1FBD_Miko_Ran : 40|16@1+ (1.0,0) [0|65532] "" FBD_HL,FBD_HM,FBD_HR,FBD_MM,FBD_Trunk,FBD_VL,FBD_VM,FBD_VR,IPB_App1
 SG_ StatusUWBRangingFDD1FBD_Miko_Hop : 56|8@1+ (1.0,0) [0|252] "" FBD_HL,FBD_HM,FBD_HR,FBD_MM,FBD_Trunk,FBD_VL,FBD_VM,FBD_VR,IPB_App1
 SG_ StatusUWBRangingFDD1FBD_Miko_Rou : 64|16@1+ (1.0,0) [0|65532] "" FBD_HL,FBD_HM,FBD_HR,FBD_MM,FBD_Trunk,FBD_VL,FBD_VM,FBD_VR,IPB_App1
 SG_ StatusUWBRangingFDD1FBD_Miko_Fin : 80|32@1+ (1.0,0) [0|4294967292] "" FBD_HL,FBD_HM,FBD_HR,FBD_MM,FBD_Trunk,FBD_VL,FBD_VM,FBD_VR,IPB_App1
 SG_ StatusUWBRangingFDD1FBD_Miko_F_2 : 112|32@1+ (1.0,0) [0|4294967292] "" FBD_HL,FBD_HM,FBD_HR,FBD_MM,FBD_Trunk,FBD_VL,FBD_VM,FBD_VR,IPB_App1
 SG_ StatusUWBRangingFDD1FBD_Miko_Num : 144|8@1+ (1.0,0) [0|252] "" FBD_HL,FBD_HM,FBD_HR,FBD_MM,FBD_Trunk,FBD_VL,FBD_VM,FBD_VR,IPB_App1
 SG_ StatusUWBRangingFDD1FBD_Miko_Ind : 152|8@1+ (1.0,0) [0|252] "" FBD_HL,FBD_HM,FBD_HR,FBD_MM,FBD_Trunk,FBD_VL,FBD_VM,FBD_VR,IPB_App1
 SG_ StatusUWBRangingFDD1FBD_Miko_Tim : 160|32@1+ (1.0,0) [0|4294967292] "" FBD_HL,FBD_HM,FBD_HR,FBD_MM,FBD_Trunk,FBD_VL,FBD_VM,FBD_VR,IPB_App1
 SG_ StatusUWBRangingFDD1FBD_Miko_T_2 : 192|8@1+ (1.0,0) [0|252] "" FBD_HL,FBD_HM,FBD_HR,FBD_MM,FBD_Trunk,FBD_VL,FBD_VM,FBD_VR,IPB_App1
 SG_ StatusUWBRangingFDD1FBD_Miko_Sta : 200|8@1+ (1.0,0) [0|252] "" FBD_HL,FBD_HM,FBD_HR,FBD_MM,FBD_Trunk,FBD_VL,FBD_VM,FBD_VR,IPB_App1
 SG_ StatusUWBRangingFDD1FBD_Miko_I_2 : 208|8@1+ (1.0,0) [0|252] "" FBD_HL,FBD_HM,FBD_HR,FBD_MM,FBD_Trunk,FBD_VL,FBD_VM,FBD_VR,IPB_App1
 SG_ StatusUWBRangingFDD1FBD_Miko_T_3 : 216|32@1+ (1.0,0) [0|4294967292] "" FBD_HL,FBD_HM,FBD_HR,FBD_MM,FBD_Trunk,FBD_VL,FBD_VM,FBD_VR,IPB_App1
 SG_ StatusUWBRangingFDD1FBD_Miko_T_4 : 248|8@1+ (1.0,0) [0|252] "" FBD_HL,FBD_HM,FBD_HR,FBD_MM,FBD_Trunk,FBD_VL,FBD_VM,FBD_VR,IPB_App1
 SG_ StatusUWBRangingFDD1FBD_Miko_S_2 : 256|8@1+ (1.0,0) [0|252] "" FBD_HL,FBD_HM,FBD_HR,FBD_MM,FBD_Trunk,FBD_VL,FBD_VM,FBD_VR,IPB_App1
 SG_ StatusUWBRangingFDD1FBD_Miko_I_3 : 264|8@1+ (1.0,0) [0|252] "" FBD_HL,FBD_HM,FBD_HR,FBD_MM,FBD_Trunk,FBD_VL,FBD_VM,FBD_VR,IPB_App1
 SG_ StatusUWBRangingFDD1FBD_Miko_T_5 : 272|32@1+ (1.0,0) [0|4294967292] "" FBD_HL,FBD_HM,FBD_HR,FBD_MM,FBD_Trunk,FBD_VL,FBD_VM,FBD_VR,IPB_App1
 SG_ StatusUWBRangingFDD1FBD_Miko_T_6 : 304|8@1+ (1.0,0) [0|252] "" FBD_HL,FBD_HM,FBD_HR,FBD_MM,FBD_Trunk,FBD_VL,FBD_VM,FBD_VR,IPB_App1
 SG_ StatusUWBRangingFDD1FBD_Miko_S_3 : 312|8@1+ (1.0,0) [0|252] "" FBD_HL,FBD_HM,FBD_HR,FBD_MM,FBD_Trunk,FBD_VL,FBD_VM,FBD_VR,IPB_App1
 SG_ StatusUWBRangingFDD1FBD_Miko_I_4 : 320|8@1+ (1.0,0) [0|252] "" FBD_HL,FBD_HM,FBD_HR,FBD_MM,FBD_Trunk,FBD_VL,FBD_VM,FBD_VR,IPB_App1
 SG_ StatusUWBRangingFDD1FBD_Miko_T_7 : 328|32@1+ (1.0,0) [0|4294967292] "" FBD_HL,FBD_HM,FBD_HR,FBD_MM,FBD_Trunk,FBD_VL,FBD_VM,FBD_VR,IPB_App1
 SG_ StatusUWBRangingFDD1FBD_Miko_T_8 : 360|8@1+ (1.0,0) [0|252] "" FBD_HL,FBD_HM,FBD_HR,FBD_MM,FBD_Trunk,FBD_VL,FBD_VM,FBD_VR,IPB_App1
 SG_ StatusUWBRangingFDD1FBD_Miko_S_4 : 368|8@1+ (1.0,0) [0|252] "" FBD_HL,FBD_HM,FBD_HR,FBD_MM,FBD_Trunk,FBD_VL,FBD_VM,FBD_VR,IPB_App1
 SG_ StatusUWBRangingFDD1FBD_Miko_I_5 : 376|8@1+ (1.0,0) [0|252] "" FBD_HL,FBD_HM,FBD_HR,FBD_MM,FBD_Trunk,FBD_VL,FBD_VM,FBD_VR,IPB_App1
 SG_ StatusUWBRangingFDD1FBD_Miko_T_9 : 384|32@1+ (1.0,0) [0|4294967292] "" FBD_HL,FBD_HM,FBD_HR,FBD_MM,FBD_Trunk,FBD_VL,FBD_VM,FBD_VR,IPB_App1
 SG_ StatusUWBRangingFDD1FBD_Miko__10 : 416|8@1+ (1.0,0) [0|252] "" FBD_HL,FBD_HM,FBD_HR,FBD_MM,FBD_Trunk,FBD_VL,FBD_VM,FBD_VR,IPB_App1
 SG_ StatusUWBRangingFDD1FBD_Miko_S_5 : 424|8@1+ (1.0,0) [0|252] "" FBD_HL,FBD_HM,FBD_HR,FBD_MM,FBD_Trunk,FBD_VL,FBD_VM,FBD_VR,IPB_App1
 SG_ StatusUWBRangingFDD1FBD_Miko_I_6 : 432|8@1+ (1.0,0) [0|252] "" FBD_HL,FBD_HM,FBD_HR,FBD_MM,FBD_Trunk,FBD_VL,FBD_VM,FBD_VR,IPB_App1
 SG_ StatusUWBRangingFDD1FBD_Miko__11 : 440|32@1+ (1.0,0) [0|4294967292] "" FBD_HL,FBD_HM,FBD_HR,FBD_MM,FBD_Trunk,FBD_VL,FBD_VM,FBD_VR,IPB_App1
 SG_ StatusUWBRangingFDD1FBD_Miko__12 : 472|8@1+ (1.0,0) [0|252] "" FBD_HL,FBD_HM,FBD_HR,FBD_MM,FBD_Trunk,FBD_VL,FBD_VM,FBD_VR,IPB_App1
 SG_ StatusUWBRangingFDD1FBD_Miko_S_6 : 480|8@1+ (1.0,0) [0|252] "" FBD_HL,FBD_HM,FBD_HR,FBD_MM,FBD_Trunk,FBD_VL,FBD_VM,FBD_VR,IPB_App1
 SG_ StatusUWBRangingFDD1FBD_Miko_IV0 : 488|8@1+ (1.0,0) [0|255] "" FBD_HL,FBD_HM,FBD_HR,FBD_MM,FBD_Trunk,FBD_VL,FBD_VM,FBD_VR,IPB_App1
 SG_ StatusUWBRangingFDD1FBD_Miko_IV1 : 496|8@1+ (1.0,0) [0|255] "" FBD_HL,FBD_HM,FBD_HR,FBD_MM,FBD_Trunk,FBD_VL,FBD_VM,FBD_VR,IPB_App1

BO_ 444 StatusUWBRangingFDD1FBD_MM: 64 FBD_MM
 SG_ StatusUWBRangingFDD1FBD_MM_Sessi : 0|8@1+ (1.0,0) [0|252] "" FBD_HL,FBD_HM,FBD_HR,FBD_Miko,FBD_Trunk,FBD_VL,FBD_VM,FBD_VR,IPB_App1
 SG_ StatusUWBRangingFDD1FBD_MM_UWBSe : 8|32@1+ (1.0,0) [0|4294967292] "" FBD_HL,FBD_HM,FBD_HR,FBD_Miko,FBD_Trunk,FBD_VL,FBD_VM,FBD_VR,IPB_App1
 SG_ StatusUWBRangingFDD1FBD_MM_Rangi : 40|16@1+ (1.0,0) [0|65532] "" FBD_HL,FBD_HM,FBD_HR,FBD_Miko,FBD_Trunk,FBD_VL,FBD_VM,FBD_VR,IPB_App1
 SG_ StatusUWBRangingFDD1FBD_MM_Hoppi : 56|8@1+ (1.0,0) [0|252] "" FBD_HL,FBD_HM,FBD_HR,FBD_Miko,FBD_Trunk,FBD_VL,FBD_VM,FBD_VR,IPB_App1
 SG_ StatusUWBRangingFDD1FBD_MM_Round : 64|16@1+ (1.0,0) [0|65532] "" FBD_HL,FBD_HM,FBD_HR,FBD_Miko,FBD_Trunk,FBD_VL,FBD_VM,FBD_VR,IPB_App1
 SG_ StatusUWBRangingFDD1FBD_MM_Final : 80|32@1+ (1.0,0) [0|4294967292] "" FBD_HL,FBD_HM,FBD_HR,FBD_Miko,FBD_Trunk,FBD_VL,FBD_VM,FBD_VR,IPB_App1
 SG_ StatusUWBRangingFDD1FBD_MM_Fin_2 : 112|32@1+ (1.0,0) [0|4294967292] "" FBD_HL,FBD_HM,FBD_HR,FBD_Miko,FBD_Trunk,FBD_VL,FBD_VM,FBD_VR,IPB_App1
 SG_ StatusUWBRangingFDD1FBD_MM_Numbe : 144|8@1+ (1.0,0) [0|252] "" FBD_HL,FBD_HM,FBD_HR,FBD_Miko,FBD_Trunk,FBD_VL,FBD_VM,FBD_VR,IPB_App1
 SG_ StatusUWBRangingFDD1FBD_MM_Index : 152|8@1+ (1.0,0) [0|252] "" FBD_HL,FBD_HM,FBD_HR,FBD_Miko,FBD_Trunk,FBD_VL,FBD_VM,FBD_VR,IPB_App1
 SG_ StatusUWBRangingFDD1FBD_MM_TimeS : 160|32@1+ (1.0,0) [0|4294967292] "" FBD_HL,FBD_HM,FBD_HR,FBD_Miko,FBD_Trunk,FBD_VL,FBD_VM,FBD_VR,IPB_App1
 SG_ StatusUWBRangingFDD1FBD_MM_Tim_2 : 192|8@1+ (1.0,0) [0|252] "" FBD_HL,FBD_HM,FBD_HR,FBD_Miko,FBD_Trunk,FBD_VL,FBD_VM,FBD_VR,IPB_App1
 SG_ StatusUWBRangingFDD1FBD_MM_Statu : 200|8@1+ (1.0,0) [0|252] "" FBD_HL,FBD_HM,FBD_HR,FBD_Miko,FBD_Trunk,FBD_VL,FBD_VM,FBD_VR,IPB_App1
 SG_ StatusUWBRangingFDD1FBD_MM_Ind_2 : 208|8@1+ (1.0,0) [0|252] "" FBD_HL,FBD_HM,FBD_HR,FBD_Miko,FBD_Trunk,FBD_VL,FBD_VM,FBD_VR,IPB_App1
 SG_ StatusUWBRangingFDD1FBD_MM_Tim_3 : 216|32@1+ (1.0,0) [0|4294967292] "" FBD_HL,FBD_HM,FBD_HR,FBD_Miko,FBD_Trunk,FBD_VL,FBD_VM,FBD_VR,IPB_App1
 SG_ StatusUWBRangingFDD1FBD_MM_Tim_4 : 248|8@1+ (1.0,0) [0|252] "" FBD_HL,FBD_HM,FBD_HR,FBD_Miko,FBD_Trunk,FBD_VL,FBD_VM,FBD_VR,IPB_App1
 SG_ StatusUWBRangingFDD1FBD_MM_Sta_2 : 256|8@1+ (1.0,0) [0|252] "" FBD_HL,FBD_HM,FBD_HR,FBD_Miko,FBD_Trunk,FBD_VL,FBD_VM,FBD_VR,IPB_App1
 SG_ StatusUWBRangingFDD1FBD_MM_Ind_3 : 264|8@1+ (1.0,0) [0|252] "" FBD_HL,FBD_HM,FBD_HR,FBD_Miko,FBD_Trunk,FBD_VL,FBD_VM,FBD_VR,IPB_App1
 SG_ StatusUWBRangingFDD1FBD_MM_Tim_5 : 272|32@1+ (1.0,0) [0|4294967292] "" FBD_HL,FBD_HM,FBD_HR,FBD_Miko,FBD_Trunk,FBD_VL,FBD_VM,FBD_VR,IPB_App1
 SG_ StatusUWBRangingFDD1FBD_MM_Tim_6 : 304|8@1+ (1.0,0) [0|252] "" FBD_HL,FBD_HM,FBD_HR,FBD_Miko,FBD_Trunk,FBD_VL,FBD_VM,FBD_VR,IPB_App1
 SG_ StatusUWBRangingFDD1FBD_MM_Sta_3 : 312|8@1+ (1.0,0) [0|252] "" FBD_HL,FBD_HM,FBD_HR,FBD_Miko,FBD_Trunk,FBD_VL,FBD_VM,FBD_VR,IPB_App1
 SG_ StatusUWBRangingFDD1FBD_MM_Ind_4 : 320|8@1+ (1.0,0) [0|252] "" FBD_HL,FBD_HM,FBD_HR,FBD_Miko,FBD_Trunk,FBD_VL,FBD_VM,FBD_VR,IPB_App1
 SG_ StatusUWBRangingFDD1FBD_MM_Tim_7 : 328|32@1+ (1.0,0) [0|4294967292] "" FBD_HL,FBD_HM,FBD_HR,FBD_Miko,FBD_Trunk,FBD_VL,FBD_VM,FBD_VR,IPB_App1
 SG_ StatusUWBRangingFDD1FBD_MM_Tim_8 : 360|8@1+ (1.0,0) [0|252] "" FBD_HL,FBD_HM,FBD_HR,FBD_Miko,FBD_Trunk,FBD_VL,FBD_VM,FBD_VR,IPB_App1
 SG_ StatusUWBRangingFDD1FBD_MM_Sta_4 : 368|8@1+ (1.0,0) [0|252] "" FBD_HL,FBD_HM,FBD_HR,FBD_Miko,FBD_Trunk,FBD_VL,FBD_VM,FBD_VR,IPB_App1
 SG_ StatusUWBRangingFDD1FBD_MM_Ind_5 : 376|8@1+ (1.0,0) [0|252] "" FBD_HL,FBD_HM,FBD_HR,FBD_Miko,FBD_Trunk,FBD_VL,FBD_VM,FBD_VR,IPB_App1
 SG_ StatusUWBRangingFDD1FBD_MM_Tim_9 : 384|32@1+ (1.0,0) [0|4294967292] "" FBD_HL,FBD_HM,FBD_HR,FBD_Miko,FBD_Trunk,FBD_VL,FBD_VM,FBD_VR,IPB_App1
 SG_ StatusUWBRangingFDD1FBD_MM_Ti_10 : 416|8@1+ (1.0,0) [0|252] "" FBD_HL,FBD_HM,FBD_HR,FBD_Miko,FBD_Trunk,FBD_VL,FBD_VM,FBD_VR,IPB_App1
 SG_ StatusUWBRangingFDD1FBD_MM_Sta_5 : 424|8@1+ (1.0,0) [0|252] "" FBD_HL,FBD_HM,FBD_HR,FBD_Miko,FBD_Trunk,FBD_VL,FBD_VM,FBD_VR,IPB_App1
 SG_ StatusUWBRangingFDD1FBD_MM_Ind_6 : 432|8@1+ (1.0,0) [0|252] "" FBD_HL,FBD_HM,FBD_HR,FBD_Miko,FBD_Trunk,FBD_VL,FBD_VM,FBD_VR,IPB_App1
 SG_ StatusUWBRangingFDD1FBD_MM_Ti_11 : 440|32@1+ (1.0,0) [0|4294967292] "" FBD_HL,FBD_HM,FBD_HR,FBD_Miko,FBD_Trunk,FBD_VL,FBD_VM,FBD_VR,IPB_App1
 SG_ StatusUWBRangingFDD1FBD_MM_Ti_12 : 472|8@1+ (1.0,0) [0|252] "" FBD_HL,FBD_HM,FBD_HR,FBD_Miko,FBD_Trunk,FBD_VL,FBD_VM,FBD_VR,IPB_App1
 SG_ StatusUWBRangingFDD1FBD_MM_Sta_6 : 480|8@1+ (1.0,0) [0|252] "" FBD_HL,FBD_HM,FBD_HR,FBD_Miko,FBD_Trunk,FBD_VL,FBD_VM,FBD_VR,IPB_App1
 SG_ StatusUWBRangingFDD1FBD_MM_IV0 : 488|8@1+ (1.0,0) [0|255] "" FBD_HL,FBD_HM,FBD_HR,FBD_Miko,FBD_Trunk,FBD_VL,FBD_VM,FBD_VR,IPB_App1
 SG_ StatusUWBRangingFDD1FBD_MM_IV1 : 496|8@1+ (1.0,0) [0|255] "" FBD_HL,FBD_HM,FBD_HR,FBD_Miko,FBD_Trunk,FBD_VL,FBD_VM,FBD_VR,IPB_App1

BO_ 458 StatusUWBRangingFDD1FBD_SML: 64 IPB_App1
 SG_ StatusUWBRangingFDD1FBD_SML_Sess : 0|8@1+ (1.0,0) [0|252] "" FBD_HL,FBD_HM,FBD_HR,FBD_MM,FBD_Miko,FBD_Trunk,FBD_VL,FBD_VM,FBD_VR
 SG_ StatusUWBRangingFDD1FBD_SML_UWBS : 8|32@1+ (1.0,0) [0|4294967292] "" FBD_HL,FBD_HM,FBD_HR,FBD_MM,FBD_Miko,FBD_Trunk,FBD_VL,FBD_VM,FBD_VR
 SG_ StatusUWBRangingFDD1FBD_SML_Rang : 40|16@1+ (1.0,0) [0|65532] "" FBD_HL,FBD_HM,FBD_HR,FBD_MM,FBD_Miko,FBD_Trunk,FBD_VL,FBD_VM,FBD_VR
 SG_ StatusUWBRangingFDD1FBD_SML_Hopp : 56|8@1+ (1.0,0) [0|252] "" FBD_HL,FBD_HM,FBD_HR,FBD_MM,FBD_Miko,FBD_Trunk,FBD_VL,FBD_VM,FBD_VR
 SG_ StatusUWBRangingFDD1FBD_SML_Roun : 64|16@1+ (1.0,0) [0|65532] "" FBD_HL,FBD_HM,FBD_HR,FBD_MM,FBD_Miko,FBD_Trunk,FBD_VL,FBD_VM,FBD_VR
 SG_ StatusUWBRangingFDD1FBD_SML_Fina : 80|32@1+ (1.0,0) [0|4294967292] "" FBD_HL,FBD_HM,FBD_HR,FBD_MM,FBD_Miko,FBD_Trunk,FBD_VL,FBD_VM,FBD_VR
 SG_ StatusUWBRangingFDD1FBD_SML_Fi_2 : 112|32@1+ (1.0,0) [0|4294967292] "" FBD_HL,FBD_HM,FBD_HR,FBD_MM,FBD_Miko,FBD_Trunk,FBD_VL,FBD_VM,FBD_VR
 SG_ StatusUWBRangingFDD1FBD_SML_Numb : 144|8@1+ (1.0,0) [0|252] "" FBD_HL,FBD_HM,FBD_HR,FBD_MM,FBD_Miko,FBD_Trunk,FBD_VL,FBD_VM,FBD_VR
 SG_ StatusUWBRangingFDD1FBD_SML_Inde : 152|8@1+ (1.0,0) [0|252] "" FBD_HL,FBD_HM,FBD_HR,FBD_MM,FBD_Miko,FBD_Trunk,FBD_VL,FBD_VM,FBD_VR
 SG_ StatusUWBRangingFDD1FBD_SML_Time : 160|32@1+ (1.0,0) [0|4294967292] "" FBD_HL,FBD_HM,FBD_HR,FBD_MM,FBD_Miko,FBD_Trunk,FBD_VL,FBD_VM,FBD_VR
 SG_ StatusUWBRangingFDD1FBD_SML_Ti_2 : 192|8@1+ (1.0,0) [0|252] "" FBD_HL,FBD_HM,FBD_HR,FBD_MM,FBD_Miko,FBD_Trunk,FBD_VL,FBD_VM,FBD_VR
 SG_ StatusUWBRangingFDD1FBD_SML_Stat : 200|8@1+ (1.0,0) [0|252] "" FBD_HL,FBD_HM,FBD_HR,FBD_MM,FBD_Miko,FBD_Trunk,FBD_VL,FBD_VM,FBD_VR
 SG_ StatusUWBRangingFDD1FBD_SML_In_2 : 208|8@1+ (1.0,0) [0|252] "" FBD_HL,FBD_HM,FBD_HR,FBD_MM,FBD_Miko,FBD_Trunk,FBD_VL,FBD_VM,FBD_VR
 SG_ StatusUWBRangingFDD1FBD_SML_Ti_3 : 216|32@1+ (1.0,0) [0|4294967292] "" FBD_HL,FBD_HM,FBD_HR,FBD_MM,FBD_Miko,FBD_Trunk,FBD_VL,FBD_VM,FBD_VR
 SG_ StatusUWBRangingFDD1FBD_SML_Ti_4 : 248|8@1+ (1.0,0) [0|252] "" FBD_HL,FBD_HM,FBD_HR,FBD_MM,FBD_Miko,FBD_Trunk,FBD_VL,FBD_VM,FBD_VR
 SG_ StatusUWBRangingFDD1FBD_SML_St_2 : 256|8@1+ (1.0,0) [0|252] "" FBD_HL,FBD_HM,FBD_HR,FBD_MM,FBD_Miko,FBD_Trunk,FBD_VL,FBD_VM,FBD_VR
 SG_ StatusUWBRangingFDD1FBD_SML_In_3 : 264|8@1+ (1.0,0) [0|252] "" FBD_HL,FBD_HM,FBD_HR,FBD_MM,FBD_Miko,FBD_Trunk,FBD_VL,FBD_VM,FBD_VR
 SG_ StatusUWBRangingFDD1FBD_SML_Ti_5 : 272|32@1+ (1.0,0) [0|4294967292] "" FBD_HL,FBD_HM,FBD_HR,FBD_MM,FBD_Miko,FBD_Trunk,FBD_VL,FBD_VM,FBD_VR
 SG_ StatusUWBRangingFDD1FBD_SML_Ti_6 : 304|8@1+ (1.0,0) [0|252] "" FBD_HL,FBD_HM,FBD_HR,FBD_MM,FBD_Miko,FBD_Trunk,FBD_VL,FBD_VM,FBD_VR
 SG_ StatusUWBRangingFDD1FBD_SML_St_3 : 312|8@1+ (1.0,0) [0|252] "" FBD_HL,FBD_HM,FBD_HR,FBD_MM,FBD_Miko,FBD_Trunk,FBD_VL,FBD_VM,FBD_VR
 SG_ StatusUWBRangingFDD1FBD_SML_In_4 : 320|8@1+ (1.0,0) [0|252] "" FBD_HL,FBD_HM,FBD_HR,FBD_MM,FBD_Miko,FBD_Trunk,FBD_VL,FBD_VM,FBD_VR
 SG_ StatusUWBRangingFDD1FBD_SML_Ti_7 : 328|32@1+ (1.0,0) [0|4294967292] "" FBD_HL,FBD_HM,FBD_HR,FBD_MM,FBD_Miko,FBD_Trunk,FBD_VL,FBD_VM,FBD_VR
 SG_ StatusUWBRangingFDD1FBD_SML_Ti_8 : 360|8@1+ (1.0,0) [0|252] "" FBD_HL,FBD_HM,FBD_HR,FBD_MM,FBD_Miko,FBD_Trunk,FBD_VL,FBD_VM,FBD_VR
 SG_ StatusUWBRangingFDD1FBD_SML_St_4 : 368|8@1+ (1.0,0) [0|252] "" FBD_HL,FBD_HM,FBD_HR,FBD_MM,FBD_Miko,FBD_Trunk,FBD_VL,FBD_VM,FBD_VR
 SG_ StatusUWBRangingFDD1FBD_SML_In_5 : 376|8@1+ (1.0,0) [0|252] "" FBD_HL,FBD_HM,FBD_HR,FBD_MM,FBD_Miko,FBD_Trunk,FBD_VL,FBD_VM,FBD_VR
 SG_ StatusUWBRangingFDD1FBD_SML_Ti_9 : 384|32@1+ (1.0,0) [0|4294967292] "" FBD_HL,FBD_HM,FBD_HR,FBD_MM,FBD_Miko,FBD_Trunk,FBD_VL,FBD_VM,FBD_VR
 SG_ StatusUWBRangingFDD1FBD_SML_T_10 : 416|8@1+ (1.0,0) [0|252] "" FBD_HL,FBD_HM,FBD_HR,FBD_MM,FBD_Miko,FBD_Trunk,FBD_VL,FBD_VM,FBD_VR
 SG_ StatusUWBRangingFDD1FBD_SML_St_5 : 424|8@1+ (1.0,0) [0|252] "" FBD_HL,FBD_HM,FBD_HR,FBD_MM,FBD_Miko,FBD_Trunk,FBD_VL,FBD_VM,FBD_VR
 SG_ StatusUWBRangingFDD1FBD_SML_In_6 : 432|8@1+ (1.0,0) [0|252] "" FBD_HL,FBD_HM,FBD_HR,FBD_MM,FBD_Miko,FBD_Trunk,FBD_VL,FBD_VM,FBD_VR
 SG_ StatusUWBRangingFDD1FBD_SML_T_11 : 440|32@1+ (1.0,0) [0|4294967292] "" FBD_HL,FBD_HM,FBD_HR,FBD_MM,FBD_Miko,FBD_Trunk,FBD_VL,FBD_VM,FBD_VR
 SG_ StatusUWBRangingFDD1FBD_SML_T_12 : 472|8@1+ (1.0,0) [0|252] "" FBD_HL,FBD_HM,FBD_HR,FBD_MM,FBD_Miko,FBD_Trunk,FBD_VL,FBD_VM,FBD_VR
 SG_ StatusUWBRangingFDD1FBD_SML_St_6 : 480|8@1+ (1.0,0) [0|252] "" FBD_HL,FBD_HM,FBD_HR,FBD_MM,FBD_Miko,FBD_Trunk,FBD_VL,FBD_VM,FBD_VR
 SG_ StatusUWBRangingFDD1FBD_SML_IV0 : 488|8@1+ (1.0,0) [0|255] "" FBD_HL,FBD_HM,FBD_HR,FBD_MM,FBD_Miko,FBD_Trunk,FBD_VL,FBD_VM,FBD_VR
 SG_ StatusUWBRangingFDD1FBD_SML_IV1 : 496|8@1+ (1.0,0) [0|255] "" FBD_HL,FBD_HM,FBD_HR,FBD_MM,FBD_Miko,FBD_Trunk,FBD_VL,FBD_VM,FBD_VR

BO_ 459 StatusUWBRangingFDD1FBD_SMR: 64 IPB_App1
 SG_ StatusUWBRangingFDD1FBD_SMR_Sess : 0|8@1+ (1.0,0) [0|252] "" FBD_HL,FBD_HM,FBD_HR,FBD_MM,FBD_Miko,FBD_Trunk,FBD_VL,FBD_VM,FBD_VR
 SG_ StatusUWBRangingFDD1FBD_SMR_UWBS : 8|32@1+ (1.0,0) [0|4294967292] "" FBD_HL,FBD_HM,FBD_HR,FBD_MM,FBD_Miko,FBD_Trunk,FBD_VL,FBD_VM,FBD_VR
 SG_ StatusUWBRangingFDD1FBD_SMR_Rang : 40|16@1+ (1.0,0) [0|65532] "" FBD_HL,FBD_HM,FBD_HR,FBD_MM,FBD_Miko,FBD_Trunk,FBD_VL,FBD_VM,FBD_VR
 SG_ StatusUWBRangingFDD1FBD_SMR_Hopp : 56|8@1+ (1.0,0) [0|252] "" FBD_HL,FBD_HM,FBD_HR,FBD_MM,FBD_Miko,FBD_Trunk,FBD_VL,FBD_VM,FBD_VR
 SG_ StatusUWBRangingFDD1FBD_SMR_Roun : 64|16@1+ (1.0,0) [0|65532] "" FBD_HL,FBD_HM,FBD_HR,FBD_MM,FBD_Miko,FBD_Trunk,FBD_VL,FBD_VM,FBD_VR
 SG_ StatusUWBRangingFDD1FBD_SMR_Fina : 80|32@1+ (1.0,0) [0|4294967292] "" FBD_HL,FBD_HM,FBD_HR,FBD_MM,FBD_Miko,FBD_Trunk,FBD_VL,FBD_VM,FBD_VR
 SG_ StatusUWBRangingFDD1FBD_SMR_Fi_2 : 112|32@1+ (1.0,0) [0|4294967292] "" FBD_HL,FBD_HM,FBD_HR,FBD_MM,FBD_Miko,FBD_Trunk,FBD_VL,FBD_VM,FBD_VR
 SG_ StatusUWBRangingFDD1FBD_SMR_Numb : 144|8@1+ (1.0,0) [0|252] "" FBD_HL,FBD_HM,FBD_HR,FBD_MM,FBD_Miko,FBD_Trunk,FBD_VL,FBD_VM,FBD_VR
 SG_ StatusUWBRangingFDD1FBD_SMR_Inde : 152|8@1+ (1.0,0) [0|252] "" FBD_HL,FBD_HM,FBD_HR,FBD_MM,FBD_Miko,FBD_Trunk,FBD_VL,FBD_VM,FBD_VR
 SG_ StatusUWBRangingFDD1FBD_SMR_Time : 160|32@1+ (1.0,0) [0|4294967292] "" FBD_HL,FBD_HM,FBD_HR,FBD_MM,FBD_Miko,FBD_Trunk,FBD_VL,FBD_VM,FBD_VR
 SG_ StatusUWBRangingFDD1FBD_SMR_Ti_2 : 192|8@1+ (1.0,0) [0|252] "" FBD_HL,FBD_HM,FBD_HR,FBD_MM,FBD_Miko,FBD_Trunk,FBD_VL,FBD_VM,FBD_VR
 SG_ StatusUWBRangingFDD1FBD_SMR_Stat : 200|8@1+ (1.0,0) [0|252] "" FBD_HL,FBD_HM,FBD_HR,FBD_MM,FBD_Miko,FBD_Trunk,FBD_VL,FBD_VM,FBD_VR
 SG_ StatusUWBRangingFDD1FBD_SMR_In_2 : 208|8@1+ (1.0,0) [0|252] "" FBD_HL,FBD_HM,FBD_HR,FBD_MM,FBD_Miko,FBD_Trunk,FBD_VL,FBD_VM,FBD_VR
 SG_ StatusUWBRangingFDD1FBD_SMR_Ti_3 : 216|32@1+ (1.0,0) [0|4294967292] "" FBD_HL,FBD_HM,FBD_HR,FBD_MM,FBD_Miko,FBD_Trunk,FBD_VL,FBD_VM,FBD_VR
 SG_ StatusUWBRangingFDD1FBD_SMR_Ti_4 : 248|8@1+ (1.0,0) [0|252] "" FBD_HL,FBD_HM,FBD_HR,FBD_MM,FBD_Miko,FBD_Trunk,FBD_VL,FBD_VM,FBD_VR
 SG_ StatusUWBRangingFDD1FBD_SMR_St_2 : 256|8@1+ (1.0,0) [0|252] "" FBD_HL,FBD_HM,FBD_HR,FBD_MM,FBD_Miko,FBD_Trunk,FBD_VL,FBD_VM,FBD_VR
 SG_ StatusUWBRangingFDD1FBD_SMR_In_3 : 264|8@1+ (1.0,0) [0|252] "" FBD_HL,FBD_HM,FBD_HR,FBD_MM,FBD_Miko,FBD_Trunk,FBD_VL,FBD_VM,FBD_VR
 SG_ StatusUWBRangingFDD1FBD_SMR_Ti_5 : 272|32@1+ (1.0,0) [0|4294967292] "" FBD_HL,FBD_HM,FBD_HR,FBD_MM,FBD_Miko,FBD_Trunk,FBD_VL,FBD_VM,FBD_VR
 SG_ StatusUWBRangingFDD1FBD_SMR_Ti_6 : 304|8@1+ (1.0,0) [0|252] "" FBD_HL,FBD_HM,FBD_HR,FBD_MM,FBD_Miko,FBD_Trunk,FBD_VL,FBD_VM,FBD_VR
 SG_ StatusUWBRangingFDD1FBD_SMR_St_3 : 312|8@1+ (1.0,0) [0|252] "" FBD_HL,FBD_HM,FBD_HR,FBD_MM,FBD_Miko,FBD_Trunk,FBD_VL,FBD_VM,FBD_VR
 SG_ StatusUWBRangingFDD1FBD_SMR_In_4 : 320|8@1+ (1.0,0) [0|252] "" FBD_HL,FBD_HM,FBD_HR,FBD_MM,FBD_Miko,FBD_Trunk,FBD_VL,FBD_VM,FBD_VR
 SG_ StatusUWBRangingFDD1FBD_SMR_Ti_7 : 328|32@1+ (1.0,0) [0|4294967292] "" FBD_HL,FBD_HM,FBD_HR,FBD_MM,FBD_Miko,FBD_Trunk,FBD_VL,FBD_VM,FBD_VR
 SG_ StatusUWBRangingFDD1FBD_SMR_Ti_8 : 360|8@1+ (1.0,0) [0|252] "" FBD_HL,FBD_HM,FBD_HR,FBD_MM,FBD_Miko,FBD_Trunk,FBD_VL,FBD_VM,FBD_VR
 SG_ StatusUWBRangingFDD1FBD_SMR_St_4 : 368|8@1+ (1.0,0) [0|252] "" FBD_HL,FBD_HM,FBD_HR,FBD_MM,FBD_Miko,FBD_Trunk,FBD_VL,FBD_VM,FBD_VR
 SG_ StatusUWBRangingFDD1FBD_SMR_In_5 : 376|8@1+ (1.0,0) [0|252] "" FBD_HL,FBD_HM,FBD_HR,FBD_MM,FBD_Miko,FBD_Trunk,FBD_VL,FBD_VM,FBD_VR
 SG_ StatusUWBRangingFDD1FBD_SMR_Ti_9 : 384|32@1+ (1.0,0) [0|4294967292] "" FBD_HL,FBD_HM,FBD_HR,FBD_MM,FBD_Miko,FBD_Trunk,FBD_VL,FBD_VM,FBD_VR
 SG_ StatusUWBRangingFDD1FBD_SMR_T_10 : 416|8@1+ (1.0,0) [0|252] "" FBD_HL,FBD_HM,FBD_HR,FBD_MM,FBD_Miko,FBD_Trunk,FBD_VL,FBD_VM,FBD_VR
 SG_ StatusUWBRangingFDD1FBD_SMR_St_5 : 424|8@1+ (1.0,0) [0|252] "" FBD_HL,FBD_HM,FBD_HR,FBD_MM,FBD_Miko,FBD_Trunk,FBD_VL,FBD_VM,FBD_VR
 SG_ StatusUWBRangingFDD1FBD_SMR_In_6 : 432|8@1+ (1.0,0) [0|252] "" FBD_HL,FBD_HM,FBD_HR,FBD_MM,FBD_Miko,FBD_Trunk,FBD_VL,FBD_VM,FBD_VR
 SG_ StatusUWBRangingFDD1FBD_SMR_T_11 : 440|32@1+ (1.0,0) [0|4294967292] "" FBD_HL,FBD_HM,FBD_HR,FBD_MM,FBD_Miko,FBD_Trunk,FBD_VL,FBD_VM,FBD_VR
 SG_ StatusUWBRangingFDD1FBD_SMR_T_12 : 472|8@1+ (1.0,0) [0|252] "" FBD_HL,FBD_HM,FBD_HR,FBD_MM,FBD_Miko,FBD_Trunk,FBD_VL,FBD_VM,FBD_VR
 SG_ StatusUWBRangingFDD1FBD_SMR_St_6 : 480|8@1+ (1.0,0) [0|252] "" FBD_HL,FBD_HM,FBD_HR,FBD_MM,FBD_Miko,FBD_Trunk,FBD_VL,FBD_VM,FBD_VR
 SG_ StatusUWBRangingFDD1FBD_SMR_IV0 : 488|8@1+ (1.0,0) [0|255] "" FBD_HL,FBD_HM,FBD_HR,FBD_MM,FBD_Miko,FBD_Trunk,FBD_VL,FBD_VM,FBD_VR
 SG_ StatusUWBRangingFDD1FBD_SMR_IV1 : 496|8@1+ (1.0,0) [0|255] "" FBD_HL,FBD_HM,FBD_HR,FBD_MM,FBD_Miko,FBD_Trunk,FBD_VL,FBD_VM,FBD_VR

BO_ 453 StatusUWBRangingFDD1FBD_Trunk: 64 FBD_Trunk
 SG_ StatusUWBRangingFDD1FBD_Trunk_Se : 0|8@1+ (1.0,0) [0|252] "" FBD_HL,FBD_HM,FBD_HR,FBD_MM,FBD_Miko,FBD_VL,FBD_VM,FBD_VR,IPB_App1
 SG_ StatusUWBRangingFDD1FBD_Trunk_UW : 8|32@1+ (1.0,0) [0|4294967292] "" FBD_HL,FBD_HM,FBD_HR,FBD_MM,FBD_Miko,FBD_VL,FBD_VM,FBD_VR,IPB_App1
 SG_ StatusUWBRangingFDD1FBD_Trunk_Ra : 40|16@1+ (1.0,0) [0|65532] "" FBD_HL,FBD_HM,FBD_HR,FBD_MM,FBD_Miko,FBD_VL,FBD_VM,FBD_VR,IPB_App1
 SG_ StatusUWBRangingFDD1FBD_Trunk_Ho : 56|8@1+ (1.0,0) [0|252] "" FBD_HL,FBD_HM,FBD_HR,FBD_MM,FBD_Miko,FBD_VL,FBD_VM,FBD_VR,IPB_App1
 SG_ StatusUWBRangingFDD1FBD_Trunk_Ro : 64|16@1+ (1.0,0) [0|65532] "" FBD_HL,FBD_HM,FBD_HR,FBD_MM,FBD_Miko,FBD_VL,FBD_VM,FBD_VR,IPB_App1
 SG_ StatusUWBRangingFDD1FBD_Trunk_Fi : 80|32@1+ (1.0,0) [0|4294967292] "" FBD_HL,FBD_HM,FBD_HR,FBD_MM,FBD_Miko,FBD_VL,FBD_VM,FBD_VR,IPB_App1
 SG_ StatusUWBRangingFDD1FBD_Trunk__2 : 112|32@1+ (1.0,0) [0|4294967292] "" FBD_HL,FBD_HM,FBD_HR,FBD_MM,FBD_Miko,FBD_VL,FBD_VM,FBD_VR,IPB_App1
 SG_ StatusUWBRangingFDD1FBD_Trunk_Nu : 144|8@1+ (1.0,0) [0|252] "" FBD_HL,FBD_HM,FBD_HR,FBD_MM,FBD_Miko,FBD_VL,FBD_VM,FBD_VR,IPB_App1
 SG_ StatusUWBRangingFDD1FBD_Trunk_In : 152|8@1+ (1.0,0) [0|252] "" FBD_HL,FBD_HM,FBD_HR,FBD_MM,FBD_Miko,FBD_VL,FBD_VM,FBD_VR,IPB_App1
 SG_ StatusUWBRangingFDD1FBD_Trunk_Ti : 160|32@1+ (1.0,0) [0|4294967292] "" FBD_HL,FBD_HM,FBD_HR,FBD_MM,FBD_Miko,FBD_VL,FBD_VM,FBD_VR,IPB_App1
 SG_ StatusUWBRangingFDD1FBD_Trunk__3 : 192|8@1+ (1.0,0) [0|252] "" FBD_HL,FBD_HM,FBD_HR,FBD_MM,FBD_Miko,FBD_VL,FBD_VM,FBD_VR,IPB_App1
 SG_ StatusUWBRangingFDD1FBD_Trunk_St : 200|8@1+ (1.0,0) [0|252] "" FBD_HL,FBD_HM,FBD_HR,FBD_MM,FBD_Miko,FBD_VL,FBD_VM,FBD_VR,IPB_App1
 SG_ StatusUWBRangingFDD1FBD_Trunk__4 : 208|8@1+ (1.0,0) [0|252] "" FBD_HL,FBD_HM,FBD_HR,FBD_MM,FBD_Miko,FBD_VL,FBD_VM,FBD_VR,IPB_App1
 SG_ StatusUWBRangingFDD1FBD_Trunk__5 : 216|32@1+ (1.0,0) [0|4294967292] "" FBD_HL,FBD_HM,FBD_HR,FBD_MM,FBD_Miko,FBD_VL,FBD_VM,FBD_VR,IPB_App1
 SG_ StatusUWBRangingFDD1FBD_Trunk__6 : 248|8@1+ (1.0,0) [0|252] "" FBD_HL,FBD_HM,FBD_HR,FBD_MM,FBD_Miko,FBD_VL,FBD_VM,FBD_VR,IPB_App1
 SG_ StatusUWBRangingFDD1FBD_Trunk__7 : 256|8@1+ (1.0,0) [0|252] "" FBD_HL,FBD_HM,FBD_HR,FBD_MM,FBD_Miko,FBD_VL,FBD_VM,FBD_VR,IPB_App1
 SG_ StatusUWBRangingFDD1FBD_Trunk__8 : 264|8@1+ (1.0,0) [0|252] "" FBD_HL,FBD_HM,FBD_HR,FBD_MM,FBD_Miko,FBD_VL,FBD_VM,FBD_VR,IPB_App1
 SG_ StatusUWBRangingFDD1FBD_Trunk__9 : 272|32@1+ (1.0,0) [0|4294967292] "" FBD_HL,FBD_HM,FBD_HR,FBD_MM,FBD_Miko,FBD_VL,FBD_VM,FBD_VR,IPB_App1
 SG_ StatusUWBRangingFDD1FBD_Trunk_10 : 304|8@1+ (1.0,0) [0|252] "" FBD_HL,FBD_HM,FBD_HR,FBD_MM,FBD_Miko,FBD_VL,FBD_VM,FBD_VR,IPB_App1
 SG_ StatusUWBRangingFDD1FBD_Trunk_11 : 312|8@1+ (1.0,0) [0|252] "" FBD_HL,FBD_HM,FBD_HR,FBD_MM,FBD_Miko,FBD_VL,FBD_VM,FBD_VR,IPB_App1
 SG_ StatusUWBRangingFDD1FBD_Trunk_12 : 320|8@1+ (1.0,0) [0|252] "" FBD_HL,FBD_HM,FBD_HR,FBD_MM,FBD_Miko,FBD_VL,FBD_VM,FBD_VR,IPB_App1
 SG_ StatusUWBRangingFDD1FBD_Trunk_13 : 328|32@1+ (1.0,0) [0|4294967292] "" FBD_HL,FBD_HM,FBD_HR,FBD_MM,FBD_Miko,FBD_VL,FBD_VM,FBD_VR,IPB_App1
 SG_ StatusUWBRangingFDD1FBD_Trunk_14 : 360|8@1+ (1.0,0) [0|252] "" FBD_HL,FBD_HM,FBD_HR,FBD_MM,FBD_Miko,FBD_VL,FBD_VM,FBD_VR,IPB_App1
 SG_ StatusUWBRangingFDD1FBD_Trunk_15 : 368|8@1+ (1.0,0) [0|252] "" FBD_HL,FBD_HM,FBD_HR,FBD_MM,FBD_Miko,FBD_VL,FBD_VM,FBD_VR,IPB_App1
 SG_ StatusUWBRangingFDD1FBD_Trunk_16 : 376|8@1+ (1.0,0) [0|252] "" FBD_HL,FBD_HM,FBD_HR,FBD_MM,FBD_Miko,FBD_VL,FBD_VM,FBD_VR,IPB_App1
 SG_ StatusUWBRangingFDD1FBD_Trunk_17 : 384|32@1+ (1.0,0) [0|4294967292] "" FBD_HL,FBD_HM,FBD_HR,FBD_MM,FBD_Miko,FBD_VL,FBD_VM,FBD_VR,IPB_App1
 SG_ StatusUWBRangingFDD1FBD_Trunk_18 : 416|8@1+ (1.0,0) [0|252] "" FBD_HL,FBD_HM,FBD_HR,FBD_MM,FBD_Miko,FBD_VL,FBD_VM,FBD_VR,IPB_App1
 SG_ StatusUWBRangingFDD1FBD_Trunk_19 : 424|8@1+ (1.0,0) [0|252] "" FBD_HL,FBD_HM,FBD_HR,FBD_MM,FBD_Miko,FBD_VL,FBD_VM,FBD_VR,IPB_App1
 SG_ StatusUWBRangingFDD1FBD_Trunk_20 : 432|8@1+ (1.0,0) [0|252] "" FBD_HL,FBD_HM,FBD_HR,FBD_MM,FBD_Miko,FBD_VL,FBD_VM,FBD_VR,IPB_App1
 SG_ StatusUWBRangingFDD1FBD_Trunk_21 : 440|32@1+ (1.0,0) [0|4294967292] "" FBD_HL,FBD_HM,FBD_HR,FBD_MM,FBD_Miko,FBD_VL,FBD_VM,FBD_VR,IPB_App1
 SG_ StatusUWBRangingFDD1FBD_Trunk_22 : 472|8@1+ (1.0,0) [0|252] "" FBD_HL,FBD_HM,FBD_HR,FBD_MM,FBD_Miko,FBD_VL,FBD_VM,FBD_VR,IPB_App1
 SG_ StatusUWBRangingFDD1FBD_Trunk_23 : 480|8@1+ (1.0,0) [0|252] "" FBD_HL,FBD_HM,FBD_HR,FBD_MM,FBD_Miko,FBD_VL,FBD_VM,FBD_VR,IPB_App1
 SG_ StatusUWBRangingFDD1FBD_Trunk_IV : 488|8@1+ (1.0,0) [0|255] "" FBD_HL,FBD_HM,FBD_HR,FBD_MM,FBD_Miko,FBD_VL,FBD_VM,FBD_VR,IPB_App1
 SG_ StatusUWBRangingFDD1FBD_Trunk_24 : 496|8@1+ (1.0,0) [0|255] "" FBD_HL,FBD_HM,FBD_HR,FBD_MM,FBD_Miko,FBD_VL,FBD_VM,FBD_VR,IPB_App1

BO_ 454 StatusUWBRangingFDD1FBD_VL: 64 FBD_VL
 SG_ StatusUWBRangingFDD1FBD_VL_Sessi : 0|8@1+ (1.0,0) [0|252] "" FBD_HL,FBD_HM,FBD_HR,FBD_MM,FBD_Miko,FBD_Trunk,FBD_VM,FBD_VR,IPB_App1
 SG_ StatusUWBRangingFDD1FBD_VL_UWBSe : 8|32@1+ (1.0,0) [0|4294967292] "" FBD_HL,FBD_HM,FBD_HR,FBD_MM,FBD_Miko,FBD_Trunk,FBD_VM,FBD_VR,IPB_App1
 SG_ StatusUWBRangingFDD1FBD_VL_Rangi : 40|16@1+ (1.0,0) [0|65532] "" FBD_HL,FBD_HM,FBD_HR,FBD_MM,FBD_Miko,FBD_Trunk,FBD_VM,FBD_VR,IPB_App1
 SG_ StatusUWBRangingFDD1FBD_VL_Hoppi : 56|8@1+ (1.0,0) [0|252] "" FBD_HL,FBD_HM,FBD_HR,FBD_MM,FBD_Miko,FBD_Trunk,FBD_VM,FBD_VR,IPB_App1
 SG_ StatusUWBRangingFDD1FBD_VL_Round : 64|16@1+ (1.0,0) [0|65532] "" FBD_HL,FBD_HM,FBD_HR,FBD_MM,FBD_Miko,FBD_Trunk,FBD_VM,FBD_VR,IPB_App1
 SG_ StatusUWBRangingFDD1FBD_VL_Final : 80|32@1+ (1.0,0) [0|4294967292] "" FBD_HL,FBD_HM,FBD_HR,FBD_MM,FBD_Miko,FBD_Trunk,FBD_VM,FBD_VR,IPB_App1
 SG_ StatusUWBRangingFDD1FBD_VL_Fin_2 : 112|32@1+ (1.0,0) [0|4294967292] "" FBD_HL,FBD_HM,FBD_HR,FBD_MM,FBD_Miko,FBD_Trunk,FBD_VM,FBD_VR,IPB_App1
 SG_ StatusUWBRangingFDD1FBD_VL_Numbe : 144|8@1+ (1.0,0) [0|252] "" FBD_HL,FBD_HM,FBD_HR,FBD_MM,FBD_Miko,FBD_Trunk,FBD_VM,FBD_VR,IPB_App1
 SG_ StatusUWBRangingFDD1FBD_VL_Index : 152|8@1+ (1.0,0) [0|252] "" FBD_HL,FBD_HM,FBD_HR,FBD_MM,FBD_Miko,FBD_Trunk,FBD_VM,FBD_VR,IPB_App1
 SG_ StatusUWBRangingFDD1FBD_VL_TimeS : 160|32@1+ (1.0,0) [0|4294967292] "" FBD_HL,FBD_HM,FBD_HR,FBD_MM,FBD_Miko,FBD_Trunk,FBD_VM,FBD_VR,IPB_App1
 SG_ StatusUWBRangingFDD1FBD_VL_Tim_2 : 192|8@1+ (1.0,0) [0|252] "" FBD_HL,FBD_HM,FBD_HR,FBD_MM,FBD_Miko,FBD_Trunk,FBD_VM,FBD_VR,IPB_App1
 SG_ StatusUWBRangingFDD1FBD_VL_Statu : 200|8@1+ (1.0,0) [0|252] "" FBD_HL,FBD_HM,FBD_HR,FBD_MM,FBD_Miko,FBD_Trunk,FBD_VM,FBD_VR,IPB_App1
 SG_ StatusUWBRangingFDD1FBD_VL_Ind_2 : 208|8@1+ (1.0,0) [0|252] "" FBD_HL,FBD_HM,FBD_HR,FBD_MM,FBD_Miko,FBD_Trunk,FBD_VM,FBD_VR,IPB_App1
 SG_ StatusUWBRangingFDD1FBD_VL_Tim_3 : 216|32@1+ (1.0,0) [0|4294967292] "" FBD_HL,FBD_HM,FBD_HR,FBD_MM,FBD_Miko,FBD_Trunk,FBD_VM,FBD_VR,IPB_App1
 SG_ StatusUWBRangingFDD1FBD_VL_Tim_4 : 248|8@1+ (1.0,0) [0|252] "" FBD_HL,FBD_HM,FBD_HR,FBD_MM,FBD_Miko,FBD_Trunk,FBD_VM,FBD_VR,IPB_App1
 SG_ StatusUWBRangingFDD1FBD_VL_Sta_2 : 256|8@1+ (1.0,0) [0|252] "" FBD_HL,FBD_HM,FBD_HR,FBD_MM,FBD_Miko,FBD_Trunk,FBD_VM,FBD_VR,IPB_App1
 SG_ StatusUWBRangingFDD1FBD_VL_Ind_3 : 264|8@1+ (1.0,0) [0|252] "" FBD_HL,FBD_HM,FBD_HR,FBD_MM,FBD_Miko,FBD_Trunk,FBD_VM,FBD_VR,IPB_App1
 SG_ StatusUWBRangingFDD1FBD_VL_Tim_5 : 272|32@1+ (1.0,0) [0|4294967292] "" FBD_HL,FBD_HM,FBD_HR,FBD_MM,FBD_Miko,FBD_Trunk,FBD_VM,FBD_VR,IPB_App1
 SG_ StatusUWBRangingFDD1FBD_VL_Tim_6 : 304|8@1+ (1.0,0) [0|252] "" FBD_HL,FBD_HM,FBD_HR,FBD_MM,FBD_Miko,FBD_Trunk,FBD_VM,FBD_VR,IPB_App1
 SG_ StatusUWBRangingFDD1FBD_VL_Sta_3 : 312|8@1+ (1.0,0) [0|252] "" FBD_HL,FBD_HM,FBD_HR,FBD_MM,FBD_Miko,FBD_Trunk,FBD_VM,FBD_VR,IPB_App1
 SG_ StatusUWBRangingFDD1FBD_VL_Ind_4 : 320|8@1+ (1.0,0) [0|252] "" FBD_HL,FBD_HM,FBD_HR,FBD_MM,FBD_Miko,FBD_Trunk,FBD_VM,FBD_VR,IPB_App1
 SG_ StatusUWBRangingFDD1FBD_VL_Tim_7 : 328|32@1+ (1.0,0) [0|4294967292] "" FBD_HL,FBD_HM,FBD_HR,FBD_MM,FBD_Miko,FBD_Trunk,FBD_VM,FBD_VR,IPB_App1
 SG_ StatusUWBRangingFDD1FBD_VL_Tim_8 : 360|8@1+ (1.0,0) [0|252] "" FBD_HL,FBD_HM,FBD_HR,FBD_MM,FBD_Miko,FBD_Trunk,FBD_VM,FBD_VR,IPB_App1
 SG_ StatusUWBRangingFDD1FBD_VL_Sta_4 : 368|8@1+ (1.0,0) [0|252] "" FBD_HL,FBD_HM,FBD_HR,FBD_MM,FBD_Miko,FBD_Trunk,FBD_VM,FBD_VR,IPB_App1
 SG_ StatusUWBRangingFDD1FBD_VL_Ind_5 : 376|8@1+ (1.0,0) [0|252] "" FBD_HL,FBD_HM,FBD_HR,FBD_MM,FBD_Miko,FBD_Trunk,FBD_VM,FBD_VR,IPB_App1
 SG_ StatusUWBRangingFDD1FBD_VL_Tim_9 : 384|32@1+ (1.0,0) [0|4294967292] "" FBD_HL,FBD_HM,FBD_HR,FBD_MM,FBD_Miko,FBD_Trunk,FBD_VM,FBD_VR,IPB_App1
 SG_ StatusUWBRangingFDD1FBD_VL_Ti_10 : 416|8@1+ (1.0,0) [0|252] "" FBD_HL,FBD_HM,FBD_HR,FBD_MM,FBD_Miko,FBD_Trunk,FBD_VM,FBD_VR,IPB_App1
 SG_ StatusUWBRangingFDD1FBD_VL_Sta_5 : 424|8@1+ (1.0,0) [0|252] "" FBD_HL,FBD_HM,FBD_HR,FBD_MM,FBD_Miko,FBD_Trunk,FBD_VM,FBD_VR,IPB_App1
 SG_ StatusUWBRangingFDD1FBD_VL_Ind_6 : 432|8@1+ (1.0,0) [0|252] "" FBD_HL,FBD_HM,FBD_HR,FBD_MM,FBD_Miko,FBD_Trunk,FBD_VM,FBD_VR,IPB_App1
 SG_ StatusUWBRangingFDD1FBD_VL_Ti_11 : 440|32@1+ (1.0,0) [0|4294967292] "" FBD_HL,FBD_HM,FBD_HR,FBD_MM,FBD_Miko,FBD_Trunk,FBD_VM,FBD_VR,IPB_App1
 SG_ StatusUWBRangingFDD1FBD_VL_Ti_12 : 472|8@1+ (1.0,0) [0|252] "" FBD_HL,FBD_HM,FBD_HR,FBD_MM,FBD_Miko,FBD_Trunk,FBD_VM,FBD_VR,IPB_App1
 SG_ StatusUWBRangingFDD1FBD_VL_Sta_6 : 480|8@1+ (1.0,0) [0|252] "" FBD_HL,FBD_HM,FBD_HR,FBD_MM,FBD_Miko,FBD_Trunk,FBD_VM,FBD_VR,IPB_App1
 SG_ StatusUWBRangingFDD1FBD_VL_IV0 : 488|8@1+ (1.0,0) [0|255] "" FBD_HL,FBD_HM,FBD_HR,FBD_MM,FBD_Miko,FBD_Trunk,FBD_VM,FBD_VR,IPB_App1
 SG_ StatusUWBRangingFDD1FBD_VL_IV1 : 496|8@1+ (1.0,0) [0|255] "" FBD_HL,FBD_HM,FBD_HR,FBD_MM,FBD_Miko,FBD_Trunk,FBD_VM,FBD_VR,IPB_App1

BO_ 450 StatusUWBRangingFDD1FBD_VM: 64 FBD_VM
 SG_ StatusUWBRangingFDD1FBD_VM_Sessi : 0|8@1+ (1.0,0) [0|252] "" FBD_HL,FBD_HM,FBD_HR,FBD_MM,FBD_Miko,FBD_Trunk,FBD_VL,FBD_VR,IPB_App1
 SG_ StatusUWBRangingFDD1FBD_VM_UWBSe : 8|32@1+ (1.0,0) [0|4294967292] "" FBD_HL,FBD_HM,FBD_HR,FBD_MM,FBD_Miko,FBD_Trunk,FBD_VL,FBD_VR,IPB_App1
 SG_ StatusUWBRangingFDD1FBD_VM_Rangi : 40|16@1+ (1.0,0) [0|65532] "" FBD_HL,FBD_HM,FBD_HR,FBD_MM,FBD_Miko,FBD_Trunk,FBD_VL,FBD_VR,IPB_App1
 SG_ StatusUWBRangingFDD1FBD_VM_Hoppi : 56|8@1+ (1.0,0) [0|252] "" FBD_HL,FBD_HM,FBD_HR,FBD_MM,FBD_Miko,FBD_Trunk,FBD_VL,FBD_VR,IPB_App1
 SG_ StatusUWBRangingFDD1FBD_VM_Round : 64|16@1+ (1.0,0) [0|65532] "" FBD_HL,FBD_HM,FBD_HR,FBD_MM,FBD_Miko,FBD_Trunk,FBD_VL,FBD_VR,IPB_App1
 SG_ StatusUWBRangingFDD1FBD_VM_Final : 80|32@1+ (1.0,0) [0|4294967292] "" FBD_HL,FBD_HM,FBD_HR,FBD_MM,FBD_Miko,FBD_Trunk,FBD_VL,FBD_VR,IPB_App1
 SG_ StatusUWBRangingFDD1FBD_VM_Fin_2 : 112|32@1+ (1.0,0) [0|4294967292] "" FBD_HL,FBD_HM,FBD_HR,FBD_MM,FBD_Miko,FBD_Trunk,FBD_VL,FBD_VR,IPB_App1
 SG_ StatusUWBRangingFDD1FBD_VM_Numbe : 144|8@1+ (1.0,0) [0|252] "" FBD_HL,FBD_HM,FBD_HR,FBD_MM,FBD_Miko,FBD_Trunk,FBD_VL,FBD_VR,IPB_App1
 SG_ StatusUWBRangingFDD1FBD_VM_Index : 152|8@1+ (1.0,0) [0|252] "" FBD_HL,FBD_HM,FBD_HR,FBD_MM,FBD_Miko,FBD_Trunk,FBD_VL,FBD_VR,IPB_App1
 SG_ StatusUWBRangingFDD1FBD_VM_TimeS : 160|32@1+ (1.0,0) [0|4294967292] "" FBD_HL,FBD_HM,FBD_HR,FBD_MM,FBD_Miko,FBD_Trunk,FBD_VL,FBD_VR,IPB_App1
 SG_ StatusUWBRangingFDD1FBD_VM_Tim_2 : 192|8@1+ (1.0,0) [0|252] "" FBD_HL,FBD_HM,FBD_HR,FBD_MM,FBD_Miko,FBD_Trunk,FBD_VL,FBD_VR,IPB_App1
 SG_ StatusUWBRangingFDD1FBD_VM_Statu : 200|8@1+ (1.0,0) [0|252] "" FBD_HL,FBD_HM,FBD_HR,FBD_MM,FBD_Miko,FBD_Trunk,FBD_VL,FBD_VR,IPB_App1
 SG_ StatusUWBRangingFDD1FBD_VM_Ind_2 : 208|8@1+ (1.0,0) [0|252] "" FBD_HL,FBD_HM,FBD_HR,FBD_MM,FBD_Miko,FBD_Trunk,FBD_VL,FBD_VR,IPB_App1
 SG_ StatusUWBRangingFDD1FBD_VM_Tim_3 : 216|32@1+ (1.0,0) [0|4294967292] "" FBD_HL,FBD_HM,FBD_HR,FBD_MM,FBD_Miko,FBD_Trunk,FBD_VL,FBD_VR,IPB_App1
 SG_ StatusUWBRangingFDD1FBD_VM_Tim_4 : 248|8@1+ (1.0,0) [0|252] "" FBD_HL,FBD_HM,FBD_HR,FBD_MM,FBD_Miko,FBD_Trunk,FBD_VL,FBD_VR,IPB_App1
 SG_ StatusUWBRangingFDD1FBD_VM_Sta_2 : 256|8@1+ (1.0,0) [0|252] "" FBD_HL,FBD_HM,FBD_HR,FBD_MM,FBD_Miko,FBD_Trunk,FBD_VL,FBD_VR,IPB_App1
 SG_ StatusUWBRangingFDD1FBD_VM_Ind_3 : 264|8@1+ (1.0,0) [0|252] "" FBD_HL,FBD_HM,FBD_HR,FBD_MM,FBD_Miko,FBD_Trunk,FBD_VL,FBD_VR,IPB_App1
 SG_ StatusUWBRangingFDD1FBD_VM_Tim_5 : 272|32@1+ (1.0,0) [0|4294967292] "" FBD_HL,FBD_HM,FBD_HR,FBD_MM,FBD_Miko,FBD_Trunk,FBD_VL,FBD_VR,IPB_App1
 SG_ StatusUWBRangingFDD1FBD_VM_Tim_6 : 304|8@1+ (1.0,0) [0|252] "" FBD_HL,FBD_HM,FBD_HR,FBD_MM,FBD_Miko,FBD_Trunk,FBD_VL,FBD_VR,IPB_App1
 SG_ StatusUWBRangingFDD1FBD_VM_Sta_3 : 312|8@1+ (1.0,0) [0|252] "" FBD_HL,FBD_HM,FBD_HR,FBD_MM,FBD_Miko,FBD_Trunk,FBD_VL,FBD_VR,IPB_App1
 SG_ StatusUWBRangingFDD1FBD_VM_Ind_4 : 320|8@1+ (1.0,0) [0|252] "" FBD_HL,FBD_HM,FBD_HR,FBD_MM,FBD_Miko,FBD_Trunk,FBD_VL,FBD_VR,IPB_App1
 SG_ StatusUWBRangingFDD1FBD_VM_Tim_7 : 328|32@1+ (1.0,0) [0|4294967292] "" FBD_HL,FBD_HM,FBD_HR,FBD_MM,FBD_Miko,FBD_Trunk,FBD_VL,FBD_VR,IPB_App1
 SG_ StatusUWBRangingFDD1FBD_VM_Tim_8 : 360|8@1+ (1.0,0) [0|252] "" FBD_HL,FBD_HM,FBD_HR,FBD_MM,FBD_Miko,FBD_Trunk,FBD_VL,FBD_VR,IPB_App1
 SG_ StatusUWBRangingFDD1FBD_VM_Sta_4 : 368|8@1+ (1.0,0) [0|252] "" FBD_HL,FBD_HM,FBD_HR,FBD_MM,FBD_Miko,FBD_Trunk,FBD_VL,FBD_VR,IPB_App1
 SG_ StatusUWBRangingFDD1FBD_VM_Ind_5 : 376|8@1+ (1.0,0) [0|252] "" FBD_HL,FBD_HM,FBD_HR,FBD_MM,FBD_Miko,FBD_Trunk,FBD_VL,FBD_VR,IPB_App1
 SG_ StatusUWBRangingFDD1FBD_VM_Tim_9 : 384|32@1+ (1.0,0) [0|4294967292] "" FBD_HL,FBD_HM,FBD_HR,FBD_MM,FBD_Miko,FBD_Trunk,FBD_VL,FBD_VR,IPB_App1
 SG_ StatusUWBRangingFDD1FBD_VM_Ti_10 : 416|8@1+ (1.0,0) [0|252] "" FBD_HL,FBD_HM,FBD_HR,FBD_MM,FBD_Miko,FBD_Trunk,FBD_VL,FBD_VR,IPB_App1
 SG_ StatusUWBRangingFDD1FBD_VM_Sta_5 : 424|8@1+ (1.0,0) [0|252] "" FBD_HL,FBD_HM,FBD_HR,FBD_MM,FBD_Miko,FBD_Trunk,FBD_VL,FBD_VR,IPB_App1
 SG_ StatusUWBRangingFDD1FBD_VM_Ind_6 : 432|8@1+ (1.0,0) [0|252] "" FBD_HL,FBD_HM,FBD_HR,FBD_MM,FBD_Miko,FBD_Trunk,FBD_VL,FBD_VR,IPB_App1
 SG_ StatusUWBRangingFDD1FBD_VM_Ti_11 : 440|32@1+ (1.0,0) [0|4294967292] "" FBD_HL,FBD_HM,FBD_HR,FBD_MM,FBD_Miko,FBD_Trunk,FBD_VL,FBD_VR,IPB_App1
 SG_ StatusUWBRangingFDD1FBD_VM_Ti_12 : 472|8@1+ (1.0,0) [0|252] "" FBD_HL,FBD_HM,FBD_HR,FBD_MM,FBD_Miko,FBD_Trunk,FBD_VL,FBD_VR,IPB_App1
 SG_ StatusUWBRangingFDD1FBD_VM_Sta_6 : 480|8@1+ (1.0,0) [0|252] "" FBD_HL,FBD_HM,FBD_HR,FBD_MM,FBD_Miko,FBD_Trunk,FBD_VL,FBD_VR,IPB_App1
 SG_ StatusUWBRangingFDD1FBD_VM_IV0 : 488|8@1+ (1.0,0) [0|255] "" FBD_HL,FBD_HM,FBD_HR,FBD_MM,FBD_Miko,FBD_Trunk,FBD_VL,FBD_VR,IPB_App1
 SG_ StatusUWBRangingFDD1FBD_VM_IV1 : 496|8@1+ (1.0,0) [0|255] "" FBD_HL,FBD_HM,FBD_HR,FBD_MM,FBD_Miko,FBD_Trunk,FBD_VL,FBD_VR,IPB_App1

BO_ 455 StatusUWBRangingFDD1FBD_VR: 64 FBD_VR
 SG_ StatusUWBRangingFDD1FBD_VR_Sessi : 0|8@1+ (1.0,0) [0|252] "" FBD_HL,FBD_HM,FBD_HR,FBD_MM,FBD_Miko,FBD_Trunk,FBD_VL,FBD_VM,IPB_App1
 SG_ StatusUWBRangingFDD1FBD_VR_UWBSe : 8|32@1+ (1.0,0) [0|4294967292] "" FBD_HL,FBD_HM,FBD_HR,FBD_MM,FBD_Miko,FBD_Trunk,FBD_VL,FBD_VM,IPB_App1
 SG_ StatusUWBRangingFDD1FBD_VR_Rangi : 40|16@1+ (1.0,0) [0|65532] "" FBD_HL,FBD_HM,FBD_HR,FBD_MM,FBD_Miko,FBD_Trunk,FBD_VL,FBD_VM,IPB_App1
 SG_ StatusUWBRangingFDD1FBD_VR_Hoppi : 56|8@1+ (1.0,0) [0|252] "" FBD_HL,FBD_HM,FBD_HR,FBD_MM,FBD_Miko,FBD_Trunk,FBD_VL,FBD_VM,IPB_App1
 SG_ StatusUWBRangingFDD1FBD_VR_Round : 64|16@1+ (1.0,0) [0|65532] "" FBD_HL,FBD_HM,FBD_HR,FBD_MM,FBD_Miko,FBD_Trunk,FBD_VL,FBD_VM,IPB_App1
 SG_ StatusUWBRangingFDD1FBD_VR_Final : 80|32@1+ (1.0,0) [0|4294967292] "" FBD_HL,FBD_HM,FBD_HR,FBD_MM,FBD_Miko,FBD_Trunk,FBD_VL,FBD_VM,IPB_App1
 SG_ StatusUWBRangingFDD1FBD_VR_Fin_2 : 112|32@1+ (1.0,0) [0|4294967292] "" FBD_HL,FBD_HM,FBD_HR,FBD_MM,FBD_Miko,FBD_Trunk,FBD_VL,FBD_VM,IPB_App1
 SG_ StatusUWBRangingFDD1FBD_VR_Numbe : 144|8@1+ (1.0,0) [0|252] "" FBD_HL,FBD_HM,FBD_HR,FBD_MM,FBD_Miko,FBD_Trunk,FBD_VL,FBD_VM,IPB_App1
 SG_ StatusUWBRangingFDD1FBD_VR_Index : 152|8@1+ (1.0,0) [0|252] "" FBD_HL,FBD_HM,FBD_HR,FBD_MM,FBD_Miko,FBD_Trunk,FBD_VL,FBD_VM,IPB_App1
 SG_ StatusUWBRangingFDD1FBD_VR_TimeS : 160|32@1+ (1.0,0) [0|4294967292] "" FBD_HL,FBD_HM,FBD_HR,FBD_MM,FBD_Miko,FBD_Trunk,FBD_VL,FBD_VM,IPB_App1
 SG_ StatusUWBRangingFDD1FBD_VR_Tim_2 : 192|8@1+ (1.0,0) [0|252] "" FBD_HL,FBD_HM,FBD_HR,FBD_MM,FBD_Miko,FBD_Trunk,FBD_VL,FBD_VM,IPB_App1
 SG_ StatusUWBRangingFDD1FBD_VR_Statu : 200|8@1+ (1.0,0) [0|252] "" FBD_HL,FBD_HM,FBD_HR,FBD_MM,FBD_Miko,FBD_Trunk,FBD_VL,FBD_VM,IPB_App1
 SG_ StatusUWBRangingFDD1FBD_VR_Ind_2 : 208|8@1+ (1.0,0) [0|252] "" FBD_HL,FBD_HM,FBD_HR,FBD_MM,FBD_Miko,FBD_Trunk,FBD_VL,FBD_VM,IPB_App1
 SG_ StatusUWBRangingFDD1FBD_VR_Tim_3 : 216|32@1+ (1.0,0) [0|4294967292] "" FBD_HL,FBD_HM,FBD_HR,FBD_MM,FBD_Miko,FBD_Trunk,FBD_VL,FBD_VM,IPB_App1
 SG_ StatusUWBRangingFDD1FBD_VR_Tim_4 : 248|8@1+ (1.0,0) [0|252] "" FBD_HL,FBD_HM,FBD_HR,FBD_MM,FBD_Miko,FBD_Trunk,FBD_VL,FBD_VM,IPB_App1
 SG_ StatusUWBRangingFDD1FBD_VR_Sta_2 : 256|8@1+ (1.0,0) [0|252] "" FBD_HL,FBD_HM,FBD_HR,FBD_MM,FBD_Miko,FBD_Trunk,FBD_VL,FBD_VM,IPB_App1
 SG_ StatusUWBRangingFDD1FBD_VR_Ind_3 : 264|8@1+ (1.0,0) [0|252] "" FBD_HL,FBD_HM,FBD_HR,FBD_MM,FBD_Miko,FBD_Trunk,FBD_VL,FBD_VM,IPB_App1
 SG_ StatusUWBRangingFDD1FBD_VR_Tim_5 : 272|32@1+ (1.0,0) [0|4294967292] "" FBD_HL,FBD_HM,FBD_HR,FBD_MM,FBD_Miko,FBD_Trunk,FBD_VL,FBD_VM,IPB_App1
 SG_ StatusUWBRangingFDD1FBD_VR_Tim_6 : 304|8@1+ (1.0,0) [0|252] "" FBD_HL,FBD_HM,FBD_HR,FBD_MM,FBD_Miko,FBD_Trunk,FBD_VL,FBD_VM,IPB_App1
 SG_ StatusUWBRangingFDD1FBD_VR_Sta_3 : 312|8@1+ (1.0,0) [0|252] "" FBD_HL,FBD_HM,FBD_HR,FBD_MM,FBD_Miko,FBD_Trunk,FBD_VL,FBD_VM,IPB_App1
 SG_ StatusUWBRangingFDD1FBD_VR_Ind_4 : 320|8@1+ (1.0,0) [0|252] "" FBD_HL,FBD_HM,FBD_HR,FBD_MM,FBD_Miko,FBD_Trunk,FBD_VL,FBD_VM,IPB_App1
 SG_ StatusUWBRangingFDD1FBD_VR_Tim_7 : 328|32@1+ (1.0,0) [0|4294967292] "" FBD_HL,FBD_HM,FBD_HR,FBD_MM,FBD_Miko,FBD_Trunk,FBD_VL,FBD_VM,IPB_App1
 SG_ StatusUWBRangingFDD1FBD_VR_Tim_8 : 360|8@1+ (1.0,0) [0|252] "" FBD_HL,FBD_HM,FBD_HR,FBD_MM,FBD_Miko,FBD_Trunk,FBD_VL,FBD_VM,IPB_App1
 SG_ StatusUWBRangingFDD1FBD_VR_Sta_4 : 368|8@1+ (1.0,0) [0|252] "" FBD_HL,FBD_HM,FBD_HR,FBD_MM,FBD_Miko,FBD_Trunk,FBD_VL,FBD_VM,IPB_App1
 SG_ StatusUWBRangingFDD1FBD_VR_Ind_5 : 376|8@1+ (1.0,0) [0|252] "" FBD_HL,FBD_HM,FBD_HR,FBD_MM,FBD_Miko,FBD_Trunk,FBD_VL,FBD_VM,IPB_App1
 SG_ StatusUWBRangingFDD1FBD_VR_Tim_9 : 384|32@1+ (1.0,0) [0|4294967292] "" FBD_HL,FBD_HM,FBD_HR,FBD_MM,FBD_Miko,FBD_Trunk,FBD_VL,FBD_VM,IPB_App1
 SG_ StatusUWBRangingFDD1FBD_VR_Ti_10 : 416|8@1+ (1.0,0) [0|252] "" FBD_HL,FBD_HM,FBD_HR,FBD_MM,FBD_Miko,FBD_Trunk,FBD_VL,FBD_VM,IPB_App1
 SG_ StatusUWBRangingFDD1FBD_VR_Sta_5 : 424|8@1+ (1.0,0) [0|252] "" FBD_HL,FBD_HM,FBD_HR,FBD_MM,FBD_Miko,FBD_Trunk,FBD_VL,FBD_VM,IPB_App1
 SG_ StatusUWBRangingFDD1FBD_VR_Ind_6 : 432|8@1+ (1.0,0) [0|252] "" FBD_HL,FBD_HM,FBD_HR,FBD_MM,FBD_Miko,FBD_Trunk,FBD_VL,FBD_VM,IPB_App1
 SG_ StatusUWBRangingFDD1FBD_VR_Ti_11 : 440|32@1+ (1.0,0) [0|4294967292] "" FBD_HL,FBD_HM,FBD_HR,FBD_MM,FBD_Miko,FBD_Trunk,FBD_VL,FBD_VM,IPB_App1
 SG_ StatusUWBRangingFDD1FBD_VR_Ti_12 : 472|8@1+ (1.0,0) [0|252] "" FBD_HL,FBD_HM,FBD_HR,FBD_MM,FBD_Miko,FBD_Trunk,FBD_VL,FBD_VM,IPB_App1
 SG_ StatusUWBRangingFDD1FBD_VR_Sta_6 : 480|8@1+ (1.0,0) [0|252] "" FBD_HL,FBD_HM,FBD_HR,FBD_MM,FBD_Miko,FBD_Trunk,FBD_VL,FBD_VM,IPB_App1
 SG_ StatusUWBRangingFDD1FBD_VR_IV0 : 488|8@1+ (1.0,0) [0|255] "" FBD_HL,FBD_HM,FBD_HR,FBD_MM,FBD_Miko,FBD_Trunk,FBD_VL,FBD_VM,IPB_App1
 SG_ StatusUWBRangingFDD1FBD_VR_IV1 : 496|8@1+ (1.0,0) [0|255] "" FBD_HL,FBD_HM,FBD_HR,FBD_MM,FBD_Miko,FBD_Trunk,FBD_VL,FBD_VM,IPB_App1

BO_ 466 StatusUWBRangingFDD2FBD_HL: 48 FBD_HL
 SG_ StatusUWBRangingFDD2FBD_HL_Sessi : 0|8@1+ (1.0,0) [0|252] "" FBD_HM,FBD_HR,FBD_MM,FBD_Miko,FBD_Trunk,FBD_VL,FBD_VM,FBD_VR,IPB_App1
 SG_ StatusUWBRangingFDD2FBD_HL_Index : 8|8@1+ (1.0,0) [0|252] "" FBD_HM,FBD_HR,FBD_MM,FBD_Miko,FBD_Trunk,FBD_VL,FBD_VM,FBD_VR,IPB_App1
 SG_ StatusUWBRangingFDD2FBD_HL_TimeS : 16|32@1+ (1.0,0) [0|4294967292] "" FBD_HM,FBD_HR,FBD_MM,FBD_Miko,FBD_Trunk,FBD_VL,FBD_VM,FBD_VR,IPB_App1
 SG_ StatusUWBRangingFDD2FBD_HL_Tim_2 : 48|8@1+ (1.0,0) [0|252] "" FBD_HM,FBD_HR,FBD_MM,FBD_Miko,FBD_Trunk,FBD_VL,FBD_VM,FBD_VR,IPB_App1
 SG_ StatusUWBRangingFDD2FBD_HL_Statu : 56|8@1+ (1.0,0) [0|252] "" FBD_HM,FBD_HR,FBD_MM,FBD_Miko,FBD_Trunk,FBD_VL,FBD_VM,FBD_VR,IPB_App1
 SG_ StatusUWBRangingFDD2FBD_HL_Ind_2 : 64|8@1+ (1.0,0) [0|252] "" FBD_HM,FBD_HR,FBD_MM,FBD_Miko,FBD_Trunk,FBD_VL,FBD_VM,FBD_VR,IPB_App1
 SG_ StatusUWBRangingFDD2FBD_HL_Tim_3 : 72|32@1+ (1.0,0) [0|4294967292] "" FBD_HM,FBD_HR,FBD_MM,FBD_Miko,FBD_Trunk,FBD_VL,FBD_VM,FBD_VR,IPB_App1
 SG_ StatusUWBRangingFDD2FBD_HL_Tim_4 : 104|8@1+ (1.0,0) [0|252] "" FBD_HM,FBD_HR,FBD_MM,FBD_Miko,FBD_Trunk,FBD_VL,FBD_VM,FBD_VR,IPB_App1
 SG_ StatusUWBRangingFDD2FBD_HL_Sta_2 : 112|8@1+ (1.0,0) [0|252] "" FBD_HM,FBD_HR,FBD_MM,FBD_Miko,FBD_Trunk,FBD_VL,FBD_VM,FBD_VR,IPB_App1
 SG_ StatusUWBRangingFDD2FBD_HL_Ind_3 : 120|8@1+ (1.0,0) [0|252] "" FBD_HM,FBD_HR,FBD_MM,FBD_Miko,FBD_Trunk,FBD_VL,FBD_VM,FBD_VR,IPB_App1
 SG_ StatusUWBRangingFDD2FBD_HL_Tim_5 : 128|32@1+ (1.0,0) [0|4294967292] "" FBD_HM,FBD_HR,FBD_MM,FBD_Miko,FBD_Trunk,FBD_VL,FBD_VM,FBD_VR,IPB_App1
 SG_ StatusUWBRangingFDD2FBD_HL_Tim_6 : 160|8@1+ (1.0,0) [0|252] "" FBD_HM,FBD_HR,FBD_MM,FBD_Miko,FBD_Trunk,FBD_VL,FBD_VM,FBD_VR,IPB_App1
 SG_ StatusUWBRangingFDD2FBD_HL_Sta_3 : 168|8@1+ (1.0,0) [0|252] "" FBD_HM,FBD_HR,FBD_MM,FBD_Miko,FBD_Trunk,FBD_VL,FBD_VM,FBD_VR,IPB_App1
 SG_ StatusUWBRangingFDD2FBD_HL_Ind_4 : 176|8@1+ (1.0,0) [0|252] "" FBD_HM,FBD_HR,FBD_MM,FBD_Miko,FBD_Trunk,FBD_VL,FBD_VM,FBD_VR,IPB_App1
 SG_ StatusUWBRangingFDD2FBD_HL_Tim_7 : 184|32@1+ (1.0,0) [0|4294967292] "" FBD_HM,FBD_HR,FBD_MM,FBD_Miko,FBD_Trunk,FBD_VL,FBD_VM,FBD_VR,IPB_App1
 SG_ StatusUWBRangingFDD2FBD_HL_Tim_8 : 216|8@1+ (1.0,0) [0|252] "" FBD_HM,FBD_HR,FBD_MM,FBD_Miko,FBD_Trunk,FBD_VL,FBD_VM,FBD_VR,IPB_App1
 SG_ StatusUWBRangingFDD2FBD_HL_Sta_4 : 224|8@1+ (1.0,0) [0|252] "" FBD_HM,FBD_HR,FBD_MM,FBD_Miko,FBD_Trunk,FBD_VL,FBD_VM,FBD_VR,IPB_App1
 SG_ StatusUWBRangingFDD2FBD_HL_Tim_9 : 232|64@1+ (1.0,0) [0|18446744073709551612] "" FBD_HM,FBD_HR,FBD_MM,FBD_Miko,FBD_Trunk,FBD_VL,FBD_VM,FBD_VR,IPB_App1
 SG_ StatusUWBRangingFDD2FBD_HL_Signa : 296|64@1+ (1.0,0) [0|18446744073709551614] "" FBD_HM,FBD_HR,FBD_MM,FBD_Miko,FBD_Trunk,FBD_VL,FBD_VM,FBD_VR,IPB_App1
 SG_ StatusUWBRangingFDD2FBD_HL_IV2 : 360|8@1+ (1.0,0) [0|255] "" FBD_HM,FBD_HR,FBD_MM,FBD_Miko,FBD_Trunk,FBD_VL,FBD_VM,FBD_VR,IPB_App1
 SG_ StatusUWBRangingFDD2FBD_HL_IV3 : 368|8@1+ (1.0,0) [0|255] "" FBD_HM,FBD_HR,FBD_MM,FBD_Miko,FBD_Trunk,FBD_VL,FBD_VM,FBD_VR,IPB_App1

BO_ 461 StatusUWBRangingFDD2FBD_HM: 48 FBD_HM
 SG_ StatusUWBRangingFDD2FBD_HM_Sessi : 0|8@1+ (1.0,0) [0|252] "" FBD_HL,FBD_HR,FBD_MM,FBD_Miko,FBD_Trunk,FBD_VL,FBD_VM,FBD_VR,IPB_App1
 SG_ StatusUWBRangingFDD2FBD_HM_Index : 8|8@1+ (1.0,0) [0|252] "" FBD_HL,FBD_HR,FBD_MM,FBD_Miko,FBD_Trunk,FBD_VL,FBD_VM,FBD_VR,IPB_App1
 SG_ StatusUWBRangingFDD2FBD_HM_TimeS : 16|32@1+ (1.0,0) [0|4294967292] "" FBD_HL,FBD_HR,FBD_MM,FBD_Miko,FBD_Trunk,FBD_VL,FBD_VM,FBD_VR,IPB_App1
 SG_ StatusUWBRangingFDD2FBD_HM_Tim_2 : 48|8@1+ (1.0,0) [0|252] "" FBD_HL,FBD_HR,FBD_MM,FBD_Miko,FBD_Trunk,FBD_VL,FBD_VM,FBD_VR,IPB_App1
 SG_ StatusUWBRangingFDD2FBD_HM_Statu : 56|8@1+ (1.0,0) [0|252] "" FBD_HL,FBD_HR,FBD_MM,FBD_Miko,FBD_Trunk,FBD_VL,FBD_VM,FBD_VR,IPB_App1
 SG_ StatusUWBRangingFDD2FBD_HM_Ind_2 : 64|8@1+ (1.0,0) [0|252] "" FBD_HL,FBD_HR,FBD_MM,FBD_Miko,FBD_Trunk,FBD_VL,FBD_VM,FBD_VR,IPB_App1
 SG_ StatusUWBRangingFDD2FBD_HM_Tim_3 : 72|32@1+ (1.0,0) [0|4294967292] "" FBD_HL,FBD_HR,FBD_MM,FBD_Miko,FBD_Trunk,FBD_VL,FBD_VM,FBD_VR,IPB_App1
 SG_ StatusUWBRangingFDD2FBD_HM_Tim_4 : 104|8@1+ (1.0,0) [0|252] "" FBD_HL,FBD_HR,FBD_MM,FBD_Miko,FBD_Trunk,FBD_VL,FBD_VM,FBD_VR,IPB_App1
 SG_ StatusUWBRangingFDD2FBD_HM_Sta_2 : 112|8@1+ (1.0,0) [0|252] "" FBD_HL,FBD_HR,FBD_MM,FBD_Miko,FBD_Trunk,FBD_VL,FBD_VM,FBD_VR,IPB_App1
 SG_ StatusUWBRangingFDD2FBD_HM_Ind_3 : 120|8@1+ (1.0,0) [0|252] "" FBD_HL,FBD_HR,FBD_MM,FBD_Miko,FBD_Trunk,FBD_VL,FBD_VM,FBD_VR,IPB_App1
 SG_ StatusUWBRangingFDD2FBD_HM_Tim_5 : 128|32@1+ (1.0,0) [0|4294967292] "" FBD_HL,FBD_HR,FBD_MM,FBD_Miko,FBD_Trunk,FBD_VL,FBD_VM,FBD_VR,IPB_App1
 SG_ StatusUWBRangingFDD2FBD_HM_Tim_6 : 160|8@1+ (1.0,0) [0|252] "" FBD_HL,FBD_HR,FBD_MM,FBD_Miko,FBD_Trunk,FBD_VL,FBD_VM,FBD_VR,IPB_App1
 SG_ StatusUWBRangingFDD2FBD_HM_Sta_3 : 168|8@1+ (1.0,0) [0|252] "" FBD_HL,FBD_HR,FBD_MM,FBD_Miko,FBD_Trunk,FBD_VL,FBD_VM,FBD_VR,IPB_App1
 SG_ StatusUWBRangingFDD2FBD_HM_Ind_4 : 176|8@1+ (1.0,0) [0|252] "" FBD_HL,FBD_HR,FBD_MM,FBD_Miko,FBD_Trunk,FBD_VL,FBD_VM,FBD_VR,IPB_App1
 SG_ StatusUWBRangingFDD2FBD_HM_Tim_7 : 184|32@1+ (1.0,0) [0|4294967292] "" FBD_HL,FBD_HR,FBD_MM,FBD_Miko,FBD_Trunk,FBD_VL,FBD_VM,FBD_VR,IPB_App1
 SG_ StatusUWBRangingFDD2FBD_HM_Tim_8 : 216|8@1+ (1.0,0) [0|252] "" FBD_HL,FBD_HR,FBD_MM,FBD_Miko,FBD_Trunk,FBD_VL,FBD_VM,FBD_VR,IPB_App1
 SG_ StatusUWBRangingFDD2FBD_HM_Sta_4 : 224|8@1+ (1.0,0) [0|252] "" FBD_HL,FBD_HR,FBD_MM,FBD_Miko,FBD_Trunk,FBD_VL,FBD_VM,FBD_VR,IPB_App1
 SG_ StatusUWBRangingFDD2FBD_HM_Tim_9 : 232|64@1+ (1.0,0) [0|18446744073709551612] "" FBD_HL,FBD_HR,FBD_MM,FBD_Miko,FBD_Trunk,FBD_VL,FBD_VM,FBD_VR,IPB_App1
 SG_ StatusUWBRangingFDD2FBD_HM_Signa : 296|64@1+ (1.0,0) [0|18446744073709551614] "" FBD_HL,FBD_HR,FBD_MM,FBD_Miko,FBD_Trunk,FBD_VL,FBD_VM,FBD_VR,IPB_App1
 SG_ StatusUWBRangingFDD2FBD_HM_IV2 : 360|8@1+ (1.0,0) [0|255] "" FBD_HL,FBD_HR,FBD_MM,FBD_Miko,FBD_Trunk,FBD_VL,FBD_VM,FBD_VR,IPB_App1
 SG_ StatusUWBRangingFDD2FBD_HM_IV3 : 368|8@1+ (1.0,0) [0|255] "" FBD_HL,FBD_HR,FBD_MM,FBD_Miko,FBD_Trunk,FBD_VL,FBD_VM,FBD_VR,IPB_App1

BO_ 467 StatusUWBRangingFDD2FBD_HR: 48 FBD_HR
 SG_ StatusUWBRangingFDD2FBD_HR_Sessi : 0|8@1+ (1.0,0) [0|252] "" FBD_HL,FBD_HM,FBD_MM,FBD_Miko,FBD_Trunk,FBD_VL,FBD_VM,FBD_VR,IPB_App1
 SG_ StatusUWBRangingFDD2FBD_HR_Index : 8|8@1+ (1.0,0) [0|252] "" FBD_HL,FBD_HM,FBD_MM,FBD_Miko,FBD_Trunk,FBD_VL,FBD_VM,FBD_VR,IPB_App1
 SG_ StatusUWBRangingFDD2FBD_HR_TimeS : 16|32@1+ (1.0,0) [0|4294967292] "" FBD_HL,FBD_HM,FBD_MM,FBD_Miko,FBD_Trunk,FBD_VL,FBD_VM,FBD_VR,IPB_App1
 SG_ StatusUWBRangingFDD2FBD_HR_Tim_2 : 48|8@1+ (1.0,0) [0|252] "" FBD_HL,FBD_HM,FBD_MM,FBD_Miko,FBD_Trunk,FBD_VL,FBD_VM,FBD_VR,IPB_App1
 SG_ StatusUWBRangingFDD2FBD_HR_Statu : 56|8@1+ (1.0,0) [0|252] "" FBD_HL,FBD_HM,FBD_MM,FBD_Miko,FBD_Trunk,FBD_VL,FBD_VM,FBD_VR,IPB_App1
 SG_ StatusUWBRangingFDD2FBD_HR_Ind_2 : 64|8@1+ (1.0,0) [0|252] "" FBD_HL,FBD_HM,FBD_MM,FBD_Miko,FBD_Trunk,FBD_VL,FBD_VM,FBD_VR,IPB_App1
 SG_ StatusUWBRangingFDD2FBD_HR_Tim_3 : 72|32@1+ (1.0,0) [0|4294967292] "" FBD_HL,FBD_HM,FBD_MM,FBD_Miko,FBD_Trunk,FBD_VL,FBD_VM,FBD_VR,IPB_App1
 SG_ StatusUWBRangingFDD2FBD_HR_Tim_4 : 104|8@1+ (1.0,0) [0|252] "" FBD_HL,FBD_HM,FBD_MM,FBD_Miko,FBD_Trunk,FBD_VL,FBD_VM,FBD_VR,IPB_App1
 SG_ StatusUWBRangingFDD2FBD_HR_Sta_2 : 112|8@1+ (1.0,0) [0|252] "" FBD_HL,FBD_HM,FBD_MM,FBD_Miko,FBD_Trunk,FBD_VL,FBD_VM,FBD_VR,IPB_App1
 SG_ StatusUWBRangingFDD2FBD_HR_Ind_3 : 120|8@1+ (1.0,0) [0|252] "" FBD_HL,FBD_HM,FBD_MM,FBD_Miko,FBD_Trunk,FBD_VL,FBD_VM,FBD_VR,IPB_App1
 SG_ StatusUWBRangingFDD2FBD_HR_Tim_5 : 128|32@1+ (1.0,0) [0|4294967292] "" FBD_HL,FBD_HM,FBD_MM,FBD_Miko,FBD_Trunk,FBD_VL,FBD_VM,FBD_VR,IPB_App1
 SG_ StatusUWBRangingFDD2FBD_HR_Tim_6 : 160|8@1+ (1.0,0) [0|252] "" FBD_HL,FBD_HM,FBD_MM,FBD_Miko,FBD_Trunk,FBD_VL,FBD_VM,FBD_VR,IPB_App1
 SG_ StatusUWBRangingFDD2FBD_HR_Sta_3 : 168|8@1+ (1.0,0) [0|252] "" FBD_HL,FBD_HM,FBD_MM,FBD_Miko,FBD_Trunk,FBD_VL,FBD_VM,FBD_VR,IPB_App1
 SG_ StatusUWBRangingFDD2FBD_HR_Ind_4 : 176|8@1+ (1.0,0) [0|252] "" FBD_HL,FBD_HM,FBD_MM,FBD_Miko,FBD_Trunk,FBD_VL,FBD_VM,FBD_VR,IPB_App1
 SG_ StatusUWBRangingFDD2FBD_HR_Tim_7 : 184|32@1+ (1.0,0) [0|4294967292] "" FBD_HL,FBD_HM,FBD_MM,FBD_Miko,FBD_Trunk,FBD_VL,FBD_VM,FBD_VR,IPB_App1
 SG_ StatusUWBRangingFDD2FBD_HR_Tim_8 : 216|8@1+ (1.0,0) [0|252] "" FBD_HL,FBD_HM,FBD_MM,FBD_Miko,FBD_Trunk,FBD_VL,FBD_VM,FBD_VR,IPB_App1
 SG_ StatusUWBRangingFDD2FBD_HR_Sta_4 : 224|8@1+ (1.0,0) [0|252] "" FBD_HL,FBD_HM,FBD_MM,FBD_Miko,FBD_Trunk,FBD_VL,FBD_VM,FBD_VR,IPB_App1
 SG_ StatusUWBRangingFDD2FBD_HR_Tim_9 : 232|64@1+ (1.0,0) [0|18446744073709551612] "" FBD_HL,FBD_HM,FBD_MM,FBD_Miko,FBD_Trunk,FBD_VL,FBD_VM,FBD_VR,IPB_App1
 SG_ StatusUWBRangingFDD2FBD_HR_Signa : 296|64@1+ (1.0,0) [0|18446744073709551614] "" FBD_HL,FBD_HM,FBD_MM,FBD_Miko,FBD_Trunk,FBD_VL,FBD_VM,FBD_VR,IPB_App1
 SG_ StatusUWBRangingFDD2FBD_HR_IV2 : 360|8@1+ (1.0,0) [0|255] "" FBD_HL,FBD_HM,FBD_MM,FBD_Miko,FBD_Trunk,FBD_VL,FBD_VM,FBD_VR,IPB_App1
 SG_ StatusUWBRangingFDD2FBD_HR_IV3 : 368|8@1+ (1.0,0) [0|255] "" FBD_HL,FBD_HM,FBD_MM,FBD_Miko,FBD_Trunk,FBD_VL,FBD_VM,FBD_VR,IPB_App1

BO_ 462 StatusUWBRangingFDD2FBD_Miko: 48 FBD_Miko
 SG_ StatusUWBRangingFDD2FBD_Miko_Ses : 0|8@1+ (1.0,0) [0|252] "" FBD_HL,FBD_HM,FBD_HR,FBD_MM,FBD_Trunk,FBD_VL,FBD_VM,FBD_VR,IPB_App1
 SG_ StatusUWBRangingFDD2FBD_Miko_Ind : 8|8@1+ (1.0,0) [0|252] "" FBD_HL,FBD_HM,FBD_HR,FBD_MM,FBD_Trunk,FBD_VL,FBD_VM,FBD_VR,IPB_App1
 SG_ StatusUWBRangingFDD2FBD_Miko_Tim : 16|32@1+ (1.0,0) [0|4294967292] "" FBD_HL,FBD_HM,FBD_HR,FBD_MM,FBD_Trunk,FBD_VL,FBD_VM,FBD_VR,IPB_App1
 SG_ StatusUWBRangingFDD2FBD_Miko_T_2 : 48|8@1+ (1.0,0) [0|252] "" FBD_HL,FBD_HM,FBD_HR,FBD_MM,FBD_Trunk,FBD_VL,FBD_VM,FBD_VR,IPB_App1
 SG_ StatusUWBRangingFDD2FBD_Miko_Sta : 56|8@1+ (1.0,0) [0|252] "" FBD_HL,FBD_HM,FBD_HR,FBD_MM,FBD_Trunk,FBD_VL,FBD_VM,FBD_VR,IPB_App1
 SG_ StatusUWBRangingFDD2FBD_Miko_I_2 : 64|8@1+ (1.0,0) [0|252] "" FBD_HL,FBD_HM,FBD_HR,FBD_MM,FBD_Trunk,FBD_VL,FBD_VM,FBD_VR,IPB_App1
 SG_ StatusUWBRangingFDD2FBD_Miko_T_3 : 72|32@1+ (1.0,0) [0|4294967292] "" FBD_HL,FBD_HM,FBD_HR,FBD_MM,FBD_Trunk,FBD_VL,FBD_VM,FBD_VR,IPB_App1
 SG_ StatusUWBRangingFDD2FBD_Miko_T_4 : 104|8@1+ (1.0,0) [0|252] "" FBD_HL,FBD_HM,FBD_HR,FBD_MM,FBD_Trunk,FBD_VL,FBD_VM,FBD_VR,IPB_App1
 SG_ StatusUWBRangingFDD2FBD_Miko_S_2 : 112|8@1+ (1.0,0) [0|252] "" FBD_HL,FBD_HM,FBD_HR,FBD_MM,FBD_Trunk,FBD_VL,FBD_VM,FBD_VR,IPB_App1
 SG_ StatusUWBRangingFDD2FBD_Miko_I_3 : 120|8@1+ (1.0,0) [0|252] "" FBD_HL,FBD_HM,FBD_HR,FBD_MM,FBD_Trunk,FBD_VL,FBD_VM,FBD_VR,IPB_App1
 SG_ StatusUWBRangingFDD2FBD_Miko_T_5 : 128|32@1+ (1.0,0) [0|4294967292] "" FBD_HL,FBD_HM,FBD_HR,FBD_MM,FBD_Trunk,FBD_VL,FBD_VM,FBD_VR,IPB_App1
 SG_ StatusUWBRangingFDD2FBD_Miko_T_6 : 160|8@1+ (1.0,0) [0|252] "" FBD_HL,FBD_HM,FBD_HR,FBD_MM,FBD_Trunk,FBD_VL,FBD_VM,FBD_VR,IPB_App1
 SG_ StatusUWBRangingFDD2FBD_Miko_S_3 : 168|8@1+ (1.0,0) [0|252] "" FBD_HL,FBD_HM,FBD_HR,FBD_MM,FBD_Trunk,FBD_VL,FBD_VM,FBD_VR,IPB_App1
 SG_ StatusUWBRangingFDD2FBD_Miko_I_4 : 176|8@1+ (1.0,0) [0|252] "" FBD_HL,FBD_HM,FBD_HR,FBD_MM,FBD_Trunk,FBD_VL,FBD_VM,FBD_VR,IPB_App1
 SG_ StatusUWBRangingFDD2FBD_Miko_T_7 : 184|32@1+ (1.0,0) [0|4294967292] "" FBD_HL,FBD_HM,FBD_HR,FBD_MM,FBD_Trunk,FBD_VL,FBD_VM,FBD_VR,IPB_App1
 SG_ StatusUWBRangingFDD2FBD_Miko_T_8 : 216|8@1+ (1.0,0) [0|252] "" FBD_HL,FBD_HM,FBD_HR,FBD_MM,FBD_Trunk,FBD_VL,FBD_VM,FBD_VR,IPB_App1
 SG_ StatusUWBRangingFDD2FBD_Miko_S_4 : 224|8@1+ (1.0,0) [0|252] "" FBD_HL,FBD_HM,FBD_HR,FBD_MM,FBD_Trunk,FBD_VL,FBD_VM,FBD_VR,IPB_App1
 SG_ StatusUWBRangingFDD2FBD_Miko_T_9 : 232|64@1+ (1.0,0) [0|18446744073709551612] "" FBD_HL,FBD_HM,FBD_HR,FBD_MM,FBD_Trunk,FBD_VL,FBD_VM,FBD_VR,IPB_App1
 SG_ StatusUWBRangingFDD2FBD_Miko_Sig : 296|64@1+ (1.0,0) [0|18446744073709551614] "" FBD_HL,FBD_HM,FBD_HR,FBD_MM,FBD_Trunk,FBD_VL,FBD_VM,FBD_VR,IPB_App1
 SG_ StatusUWBRangingFDD2FBD_Miko_IV2 : 360|8@1+ (1.0,0) [0|255] "" FBD_HL,FBD_HM,FBD_HR,FBD_MM,FBD_Trunk,FBD_VL,FBD_VM,FBD_VR,IPB_App1
 SG_ StatusUWBRangingFDD2FBD_Miko_IV3 : 368|8@1+ (1.0,0) [0|255] "" FBD_HL,FBD_HM,FBD_HR,FBD_MM,FBD_Trunk,FBD_VL,FBD_VM,FBD_VR,IPB_App1

BO_ 445 StatusUWBRangingFDD2FBD_MM: 48 FBD_MM
 SG_ StatusUWBRangingFDD2FBD_MM_Sessi : 0|8@1+ (1.0,0) [0|252] "" FBD_HL,FBD_HM,FBD_HR,FBD_Miko,FBD_Trunk,FBD_VL,FBD_VM,FBD_VR,IPB_App1
 SG_ StatusUWBRangingFDD2FBD_MM_Index : 8|8@1+ (1.0,0) [0|252] "" FBD_HL,FBD_HM,FBD_HR,FBD_Miko,FBD_Trunk,FBD_VL,FBD_VM,FBD_VR,IPB_App1
 SG_ StatusUWBRangingFDD2FBD_MM_TimeS : 16|32@1+ (1.0,0) [0|4294967292] "" FBD_HL,FBD_HM,FBD_HR,FBD_Miko,FBD_Trunk,FBD_VL,FBD_VM,FBD_VR,IPB_App1
 SG_ StatusUWBRangingFDD2FBD_MM_Tim_2 : 48|8@1+ (1.0,0) [0|252] "" FBD_HL,FBD_HM,FBD_HR,FBD_Miko,FBD_Trunk,FBD_VL,FBD_VM,FBD_VR,IPB_App1
 SG_ StatusUWBRangingFDD2FBD_MM_Statu : 56|8@1+ (1.0,0) [0|252] "" FBD_HL,FBD_HM,FBD_HR,FBD_Miko,FBD_Trunk,FBD_VL,FBD_VM,FBD_VR,IPB_App1
 SG_ StatusUWBRangingFDD2FBD_MM_Ind_2 : 64|8@1+ (1.0,0) [0|252] "" FBD_HL,FBD_HM,FBD_HR,FBD_Miko,FBD_Trunk,FBD_VL,FBD_VM,FBD_VR,IPB_App1
 SG_ StatusUWBRangingFDD2FBD_MM_Tim_3 : 72|32@1+ (1.0,0) [0|4294967292] "" FBD_HL,FBD_HM,FBD_HR,FBD_Miko,FBD_Trunk,FBD_VL,FBD_VM,FBD_VR,IPB_App1
 SG_ StatusUWBRangingFDD2FBD_MM_Tim_4 : 104|8@1+ (1.0,0) [0|252] "" FBD_HL,FBD_HM,FBD_HR,FBD_Miko,FBD_Trunk,FBD_VL,FBD_VM,FBD_VR,IPB_App1
 SG_ StatusUWBRangingFDD2FBD_MM_Sta_2 : 112|8@1+ (1.0,0) [0|252] "" FBD_HL,FBD_HM,FBD_HR,FBD_Miko,FBD_Trunk,FBD_VL,FBD_VM,FBD_VR,IPB_App1
 SG_ StatusUWBRangingFDD2FBD_MM_Ind_3 : 120|8@1+ (1.0,0) [0|252] "" FBD_HL,FBD_HM,FBD_HR,FBD_Miko,FBD_Trunk,FBD_VL,FBD_VM,FBD_VR,IPB_App1
 SG_ StatusUWBRangingFDD2FBD_MM_Tim_5 : 128|32@1+ (1.0,0) [0|4294967292] "" FBD_HL,FBD_HM,FBD_HR,FBD_Miko,FBD_Trunk,FBD_VL,FBD_VM,FBD_VR,IPB_App1
 SG_ StatusUWBRangingFDD2FBD_MM_Tim_6 : 160|8@1+ (1.0,0) [0|252] "" FBD_HL,FBD_HM,FBD_HR,FBD_Miko,FBD_Trunk,FBD_VL,FBD_VM,FBD_VR,IPB_App1
 SG_ StatusUWBRangingFDD2FBD_MM_Sta_3 : 168|8@1+ (1.0,0) [0|252] "" FBD_HL,FBD_HM,FBD_HR,FBD_Miko,FBD_Trunk,FBD_VL,FBD_VM,FBD_VR,IPB_App1
 SG_ StatusUWBRangingFDD2FBD_MM_Ind_4 : 176|8@1+ (1.0,0) [0|252] "" FBD_HL,FBD_HM,FBD_HR,FBD_Miko,FBD_Trunk,FBD_VL,FBD_VM,FBD_VR,IPB_App1
 SG_ StatusUWBRangingFDD2FBD_MM_Tim_7 : 184|32@1+ (1.0,0) [0|4294967292] "" FBD_HL,FBD_HM,FBD_HR,FBD_Miko,FBD_Trunk,FBD_VL,FBD_VM,FBD_VR,IPB_App1
 SG_ StatusUWBRangingFDD2FBD_MM_Tim_8 : 216|8@1+ (1.0,0) [0|252] "" FBD_HL,FBD_HM,FBD_HR,FBD_Miko,FBD_Trunk,FBD_VL,FBD_VM,FBD_VR,IPB_App1
 SG_ StatusUWBRangingFDD2FBD_MM_Sta_4 : 224|8@1+ (1.0,0) [0|252] "" FBD_HL,FBD_HM,FBD_HR,FBD_Miko,FBD_Trunk,FBD_VL,FBD_VM,FBD_VR,IPB_App1
 SG_ StatusUWBRangingFDD2FBD_MM_Tim_9 : 232|64@1+ (1.0,0) [0|18446744073709551612] "" FBD_HL,FBD_HM,FBD_HR,FBD_Miko,FBD_Trunk,FBD_VL,FBD_VM,FBD_VR,IPB_App1
 SG_ StatusUWBRangingFDD2FBD_MM_Signa : 296|64@1+ (1.0,0) [0|18446744073709551614] "" FBD_HL,FBD_HM,FBD_HR,FBD_Miko,FBD_Trunk,FBD_VL,FBD_VM,FBD_VR,IPB_App1
 SG_ StatusUWBRangingFDD2FBD_MM_IV2 : 360|8@1+ (1.0,0) [0|255] "" FBD_HL,FBD_HM,FBD_HR,FBD_Miko,FBD_Trunk,FBD_VL,FBD_VM,FBD_VR,IPB_App1
 SG_ StatusUWBRangingFDD2FBD_MM_IV3 : 368|8@1+ (1.0,0) [0|255] "" FBD_HL,FBD_HM,FBD_HR,FBD_Miko,FBD_Trunk,FBD_VL,FBD_VM,FBD_VR,IPB_App1

BO_ 468 StatusUWBRangingFDD2FBD_SML: 48 IPB_App1
 SG_ StatusUWBRangingFDD2FBD_SML_Sess : 0|8@1+ (1.0,0) [0|252] "" FBD_HL,FBD_HM,FBD_HR,FBD_MM,FBD_Miko,FBD_Trunk,FBD_VL,FBD_VM,FBD_VR
 SG_ StatusUWBRangingFDD2FBD_SML_Inde : 8|8@1+ (1.0,0) [0|252] "" FBD_HL,FBD_HM,FBD_HR,FBD_MM,FBD_Miko,FBD_Trunk,FBD_VL,FBD_VM,FBD_VR
 SG_ StatusUWBRangingFDD2FBD_SML_Time : 16|32@1+ (1.0,0) [0|4294967292] "" FBD_HL,FBD_HM,FBD_HR,FBD_MM,FBD_Miko,FBD_Trunk,FBD_VL,FBD_VM,FBD_VR
 SG_ StatusUWBRangingFDD2FBD_SML_Ti_2 : 48|8@1+ (1.0,0) [0|252] "" FBD_HL,FBD_HM,FBD_HR,FBD_MM,FBD_Miko,FBD_Trunk,FBD_VL,FBD_VM,FBD_VR
 SG_ StatusUWBRangingFDD2FBD_SML_Stat : 56|8@1+ (1.0,0) [0|252] "" FBD_HL,FBD_HM,FBD_HR,FBD_MM,FBD_Miko,FBD_Trunk,FBD_VL,FBD_VM,FBD_VR
 SG_ StatusUWBRangingFDD2FBD_SML_In_2 : 64|8@1+ (1.0,0) [0|252] "" FBD_HL,FBD_HM,FBD_HR,FBD_MM,FBD_Miko,FBD_Trunk,FBD_VL,FBD_VM,FBD_VR
 SG_ StatusUWBRangingFDD2FBD_SML_Ti_3 : 72|32@1+ (1.0,0) [0|4294967292] "" FBD_HL,FBD_HM,FBD_HR,FBD_MM,FBD_Miko,FBD_Trunk,FBD_VL,FBD_VM,FBD_VR
 SG_ StatusUWBRangingFDD2FBD_SML_Ti_4 : 104|8@1+ (1.0,0) [0|252] "" FBD_HL,FBD_HM,FBD_HR,FBD_MM,FBD_Miko,FBD_Trunk,FBD_VL,FBD_VM,FBD_VR
 SG_ StatusUWBRangingFDD2FBD_SML_St_2 : 112|8@1+ (1.0,0) [0|252] "" FBD_HL,FBD_HM,FBD_HR,FBD_MM,FBD_Miko,FBD_Trunk,FBD_VL,FBD_VM,FBD_VR
 SG_ StatusUWBRangingFDD2FBD_SML_In_3 : 120|8@1+ (1.0,0) [0|252] "" FBD_HL,FBD_HM,FBD_HR,FBD_MM,FBD_Miko,FBD_Trunk,FBD_VL,FBD_VM,FBD_VR
 SG_ StatusUWBRangingFDD2FBD_SML_Ti_5 : 128|32@1+ (1.0,0) [0|4294967292] "" FBD_HL,FBD_HM,FBD_HR,FBD_MM,FBD_Miko,FBD_Trunk,FBD_VL,FBD_VM,FBD_VR
 SG_ StatusUWBRangingFDD2FBD_SML_Ti_6 : 160|8@1+ (1.0,0) [0|252] "" FBD_HL,FBD_HM,FBD_HR,FBD_MM,FBD_Miko,FBD_Trunk,FBD_VL,FBD_VM,FBD_VR
 SG_ StatusUWBRangingFDD2FBD_SML_St_3 : 168|8@1+ (1.0,0) [0|252] "" FBD_HL,FBD_HM,FBD_HR,FBD_MM,FBD_Miko,FBD_Trunk,FBD_VL,FBD_VM,FBD_VR
 SG_ StatusUWBRangingFDD2FBD_SML_In_4 : 176|8@1+ (1.0,0) [0|252] "" FBD_HL,FBD_HM,FBD_HR,FBD_MM,FBD_Miko,FBD_Trunk,FBD_VL,FBD_VM,FBD_VR
 SG_ StatusUWBRangingFDD2FBD_SML_Ti_7 : 184|32@1+ (1.0,0) [0|4294967292] "" FBD_HL,FBD_HM,FBD_HR,FBD_MM,FBD_Miko,FBD_Trunk,FBD_VL,FBD_VM,FBD_VR
 SG_ StatusUWBRangingFDD2FBD_SML_Ti_8 : 216|8@1+ (1.0,0) [0|252] "" FBD_HL,FBD_HM,FBD_HR,FBD_MM,FBD_Miko,FBD_Trunk,FBD_VL,FBD_VM,FBD_VR
 SG_ StatusUWBRangingFDD2FBD_SML_St_4 : 224|8@1+ (1.0,0) [0|252] "" FBD_HL,FBD_HM,FBD_HR,FBD_MM,FBD_Miko,FBD_Trunk,FBD_VL,FBD_VM,FBD_VR
 SG_ StatusUWBRangingFDD2FBD_SML_Ti_9 : 232|64@1+ (1.0,0) [0|18446744073709551612] "" FBD_HL,FBD_HM,FBD_HR,FBD_MM,FBD_Miko,FBD_Trunk,FBD_VL,FBD_VM,FBD_VR
 SG_ StatusUWBRangingFDD2FBD_SML_Sign : 296|64@1+ (1.0,0) [0|18446744073709551614] "" FBD_HL,FBD_HM,FBD_HR,FBD_MM,FBD_Miko,FBD_Trunk,FBD_VL,FBD_VM,FBD_VR
 SG_ StatusUWBRangingFDD2FBD_SML_IV2 : 360|8@1+ (1.0,0) [0|255] "" FBD_HL,FBD_HM,FBD_HR,FBD_MM,FBD_Miko,FBD_Trunk,FBD_VL,FBD_VM,FBD_VR
 SG_ StatusUWBRangingFDD2FBD_SML_IV3 : 368|8@1+ (1.0,0) [0|255] "" FBD_HL,FBD_HM,FBD_HR,FBD_MM,FBD_Miko,FBD_Trunk,FBD_VL,FBD_VM,FBD_VR

BO_ 469 StatusUWBRangingFDD2FBD_SMR: 48 IPB_App1
 SG_ StatusUWBRangingFDD2FBD_SMR_Sess : 0|8@1+ (1.0,0) [0|252] "" FBD_HL,FBD_HM,FBD_HR,FBD_MM,FBD_Miko,FBD_Trunk,FBD_VL,FBD_VM,FBD_VR
 SG_ StatusUWBRangingFDD2FBD_SMR_Inde : 8|8@1+ (1.0,0) [0|252] "" FBD_HL,FBD_HM,FBD_HR,FBD_MM,FBD_Miko,FBD_Trunk,FBD_VL,FBD_VM,FBD_VR
 SG_ StatusUWBRangingFDD2FBD_SMR_Time : 16|32@1+ (1.0,0) [0|4294967292] "" FBD_HL,FBD_HM,FBD_HR,FBD_MM,FBD_Miko,FBD_Trunk,FBD_VL,FBD_VM,FBD_VR
 SG_ StatusUWBRangingFDD2FBD_SMR_Ti_2 : 48|8@1+ (1.0,0) [0|252] "" FBD_HL,FBD_HM,FBD_HR,FBD_MM,FBD_Miko,FBD_Trunk,FBD_VL,FBD_VM,FBD_VR
 SG_ StatusUWBRangingFDD2FBD_SMR_Stat : 56|8@1+ (1.0,0) [0|252] "" FBD_HL,FBD_HM,FBD_HR,FBD_MM,FBD_Miko,FBD_Trunk,FBD_VL,FBD_VM,FBD_VR
 SG_ StatusUWBRangingFDD2FBD_SMR_In_2 : 64|8@1+ (1.0,0) [0|252] "" FBD_HL,FBD_HM,FBD_HR,FBD_MM,FBD_Miko,FBD_Trunk,FBD_VL,FBD_VM,FBD_VR
 SG_ StatusUWBRangingFDD2FBD_SMR_Ti_3 : 72|32@1+ (1.0,0) [0|4294967292] "" FBD_HL,FBD_HM,FBD_HR,FBD_MM,FBD_Miko,FBD_Trunk,FBD_VL,FBD_VM,FBD_VR
 SG_ StatusUWBRangingFDD2FBD_SMR_Ti_4 : 104|8@1+ (1.0,0) [0|252] "" FBD_HL,FBD_HM,FBD_HR,FBD_MM,FBD_Miko,FBD_Trunk,FBD_VL,FBD_VM,FBD_VR
 SG_ StatusUWBRangingFDD2FBD_SMR_St_2 : 112|8@1+ (1.0,0) [0|252] "" FBD_HL,FBD_HM,FBD_HR,FBD_MM,FBD_Miko,FBD_Trunk,FBD_VL,FBD_VM,FBD_VR
 SG_ StatusUWBRangingFDD2FBD_SMR_In_3 : 120|8@1+ (1.0,0) [0|252] "" FBD_HL,FBD_HM,FBD_HR,FBD_MM,FBD_Miko,FBD_Trunk,FBD_VL,FBD_VM,FBD_VR
 SG_ StatusUWBRangingFDD2FBD_SMR_Ti_5 : 128|32@1+ (1.0,0) [0|4294967292] "" FBD_HL,FBD_HM,FBD_HR,FBD_MM,FBD_Miko,FBD_Trunk,FBD_VL,FBD_VM,FBD_VR
 SG_ StatusUWBRangingFDD2FBD_SMR_Ti_6 : 160|8@1+ (1.0,0) [0|252] "" FBD_HL,FBD_HM,FBD_HR,FBD_MM,FBD_Miko,FBD_Trunk,FBD_VL,FBD_VM,FBD_VR
 SG_ StatusUWBRangingFDD2FBD_SMR_St_3 : 168|8@1+ (1.0,0) [0|252] "" FBD_HL,FBD_HM,FBD_HR,FBD_MM,FBD_Miko,FBD_Trunk,FBD_VL,FBD_VM,FBD_VR
 SG_ StatusUWBRangingFDD2FBD_SMR_In_4 : 176|8@1+ (1.0,0) [0|252] "" FBD_HL,FBD_HM,FBD_HR,FBD_MM,FBD_Miko,FBD_Trunk,FBD_VL,FBD_VM,FBD_VR
 SG_ StatusUWBRangingFDD2FBD_SMR_Ti_7 : 184|32@1+ (1.0,0) [0|4294967292] "" FBD_HL,FBD_HM,FBD_HR,FBD_MM,FBD_Miko,FBD_Trunk,FBD_VL,FBD_VM,FBD_VR
 SG_ StatusUWBRangingFDD2FBD_SMR_Ti_8 : 216|8@1+ (1.0,0) [0|252] "" FBD_HL,FBD_HM,FBD_HR,FBD_MM,FBD_Miko,FBD_Trunk,FBD_VL,FBD_VM,FBD_VR
 SG_ StatusUWBRangingFDD2FBD_SMR_St_4 : 224|8@1+ (1.0,0) [0|252] "" FBD_HL,FBD_HM,FBD_HR,FBD_MM,FBD_Miko,FBD_Trunk,FBD_VL,FBD_VM,FBD_VR
 SG_ StatusUWBRangingFDD2FBD_SMR_Ti_9 : 232|64@1+ (1.0,0) [0|18446744073709551612] "" FBD_HL,FBD_HM,FBD_HR,FBD_MM,FBD_Miko,FBD_Trunk,FBD_VL,FBD_VM,FBD_VR
 SG_ StatusUWBRangingFDD2FBD_SMR_Sign : 296|64@1+ (1.0,0) [0|18446744073709551614] "" FBD_HL,FBD_HM,FBD_HR,FBD_MM,FBD_Miko,FBD_Trunk,FBD_VL,FBD_VM,FBD_VR
 SG_ StatusUWBRangingFDD2FBD_SMR_IV2 : 360|8@1+ (1.0,0) [0|255] "" FBD_HL,FBD_HM,FBD_HR,FBD_MM,FBD_Miko,FBD_Trunk,FBD_VL,FBD_VM,FBD_VR
 SG_ StatusUWBRangingFDD2FBD_SMR_IV3 : 368|8@1+ (1.0,0) [0|255] "" FBD_HL,FBD_HM,FBD_HR,FBD_MM,FBD_Miko,FBD_Trunk,FBD_VL,FBD_VM,FBD_VR

BO_ 463 StatusUWBRangingFDD2FBD_Trunk: 48 FBD_Trunk
 SG_ StatusUWBRangingFDD2FBD_Trunk_Se : 0|8@1+ (1.0,0) [0|252] "" FBD_HL,FBD_HM,FBD_HR,FBD_MM,FBD_Miko,FBD_VL,FBD_VM,FBD_VR,IPB_App1
 SG_ StatusUWBRangingFDD2FBD_Trunk_In : 8|8@1+ (1.0,0) [0|252] "" FBD_HL,FBD_HM,FBD_HR,FBD_MM,FBD_Miko,FBD_VL,FBD_VM,FBD_VR,IPB_App1
 SG_ StatusUWBRangingFDD2FBD_Trunk_Ti : 16|32@1+ (1.0,0) [0|4294967292] "" FBD_HL,FBD_HM,FBD_HR,FBD_MM,FBD_Miko,FBD_VL,FBD_VM,FBD_VR,IPB_App1
 SG_ StatusUWBRangingFDD2FBD_Trunk__2 : 48|8@1+ (1.0,0) [0|252] "" FBD_HL,FBD_HM,FBD_HR,FBD_MM,FBD_Miko,FBD_VL,FBD_VM,FBD_VR,IPB_App1
 SG_ StatusUWBRangingFDD2FBD_Trunk_St : 56|8@1+ (1.0,0) [0|252] "" FBD_HL,FBD_HM,FBD_HR,FBD_MM,FBD_Miko,FBD_VL,FBD_VM,FBD_VR,IPB_App1
 SG_ StatusUWBRangingFDD2FBD_Trunk__3 : 64|8@1+ (1.0,0) [0|252] "" FBD_HL,FBD_HM,FBD_HR,FBD_MM,FBD_Miko,FBD_VL,FBD_VM,FBD_VR,IPB_App1
 SG_ StatusUWBRangingFDD2FBD_Trunk__4 : 72|32@1+ (1.0,0) [0|4294967292] "" FBD_HL,FBD_HM,FBD_HR,FBD_MM,FBD_Miko,FBD_VL,FBD_VM,FBD_VR,IPB_App1
 SG_ StatusUWBRangingFDD2FBD_Trunk__5 : 104|8@1+ (1.0,0) [0|252] "" FBD_HL,FBD_HM,FBD_HR,FBD_MM,FBD_Miko,FBD_VL,FBD_VM,FBD_VR,IPB_App1
 SG_ StatusUWBRangingFDD2FBD_Trunk__6 : 112|8@1+ (1.0,0) [0|252] "" FBD_HL,FBD_HM,FBD_HR,FBD_MM,FBD_Miko,FBD_VL,FBD_VM,FBD_VR,IPB_App1
 SG_ StatusUWBRangingFDD2FBD_Trunk__7 : 120|8@1+ (1.0,0) [0|252] "" FBD_HL,FBD_HM,FBD_HR,FBD_MM,FBD_Miko,FBD_VL,FBD_VM,FBD_VR,IPB_App1
 SG_ StatusUWBRangingFDD2FBD_Trunk__8 : 128|32@1+ (1.0,0) [0|4294967292] "" FBD_HL,FBD_HM,FBD_HR,FBD_MM,FBD_Miko,FBD_VL,FBD_VM,FBD_VR,IPB_App1
 SG_ StatusUWBRangingFDD2FBD_Trunk__9 : 160|8@1+ (1.0,0) [0|252] "" FBD_HL,FBD_HM,FBD_HR,FBD_MM,FBD_Miko,FBD_VL,FBD_VM,FBD_VR,IPB_App1
 SG_ StatusUWBRangingFDD2FBD_Trunk_10 : 168|8@1+ (1.0,0) [0|252] "" FBD_HL,FBD_HM,FBD_HR,FBD_MM,FBD_Miko,FBD_VL,FBD_VM,FBD_VR,IPB_App1
 SG_ StatusUWBRangingFDD2FBD_Trunk_11 : 176|8@1+ (1.0,0) [0|252] "" FBD_HL,FBD_HM,FBD_HR,FBD_MM,FBD_Miko,FBD_VL,FBD_VM,FBD_VR,IPB_App1
 SG_ StatusUWBRangingFDD2FBD_Trunk_12 : 184|32@1+ (1.0,0) [0|4294967292] "" FBD_HL,FBD_HM,FBD_HR,FBD_MM,FBD_Miko,FBD_VL,FBD_VM,FBD_VR,IPB_App1
 SG_ StatusUWBRangingFDD2FBD_Trunk_13 : 216|8@1+ (1.0,0) [0|252] "" FBD_HL,FBD_HM,FBD_HR,FBD_MM,FBD_Miko,FBD_VL,FBD_VM,FBD_VR,IPB_App1
 SG_ StatusUWBRangingFDD2FBD_Trunk_14 : 224|8@1+ (1.0,0) [0|252] "" FBD_HL,FBD_HM,FBD_HR,FBD_MM,FBD_Miko,FBD_VL,FBD_VM,FBD_VR,IPB_App1
 SG_ StatusUWBRangingFDD2FBD_Trunk_15 : 232|64@1+ (1.0,0) [0|18446744073709551612] "" FBD_HL,FBD_HM,FBD_HR,FBD_MM,FBD_Miko,FBD_VL,FBD_VM,FBD_VR,IPB_App1
 SG_ StatusUWBRangingFDD2FBD_Trunk_Si : 296|64@1+ (1.0,0) [0|18446744073709551614] "" FBD_HL,FBD_HM,FBD_HR,FBD_MM,FBD_Miko,FBD_VL,FBD_VM,FBD_VR,IPB_App1
 SG_ StatusUWBRangingFDD2FBD_Trunk_IV : 360|8@1+ (1.0,0) [0|255] "" FBD_HL,FBD_HM,FBD_HR,FBD_MM,FBD_Miko,FBD_VL,FBD_VM,FBD_VR,IPB_App1
 SG_ StatusUWBRangingFDD2FBD_Trunk_16 : 368|8@1+ (1.0,0) [0|255] "" FBD_HL,FBD_HM,FBD_HR,FBD_MM,FBD_Miko,FBD_VL,FBD_VM,FBD_VR,IPB_App1

BO_ 464 StatusUWBRangingFDD2FBD_VL: 48 FBD_VL
 SG_ StatusUWBRangingFDD2FBD_VL_Sessi : 0|8@1+ (1.0,0) [0|252] "" FBD_HL,FBD_HM,FBD_HR,FBD_MM,FBD_Miko,FBD_Trunk,FBD_VM,FBD_VR,IPB_App1
 SG_ StatusUWBRangingFDD2FBD_VL_Index : 8|8@1+ (1.0,0) [0|252] "" FBD_HL,FBD_HM,FBD_HR,FBD_MM,FBD_Miko,FBD_Trunk,FBD_VM,FBD_VR,IPB_App1
 SG_ StatusUWBRangingFDD2FBD_VL_TimeS : 16|32@1+ (1.0,0) [0|4294967292] "" FBD_HL,FBD_HM,FBD_HR,FBD_MM,FBD_Miko,FBD_Trunk,FBD_VM,FBD_VR,IPB_App1
 SG_ StatusUWBRangingFDD2FBD_VL_Tim_2 : 48|8@1+ (1.0,0) [0|252] "" FBD_HL,FBD_HM,FBD_HR,FBD_MM,FBD_Miko,FBD_Trunk,FBD_VM,FBD_VR,IPB_App1
 SG_ StatusUWBRangingFDD2FBD_VL_Statu : 56|8@1+ (1.0,0) [0|252] "" FBD_HL,FBD_HM,FBD_HR,FBD_MM,FBD_Miko,FBD_Trunk,FBD_VM,FBD_VR,IPB_App1
 SG_ StatusUWBRangingFDD2FBD_VL_Ind_2 : 64|8@1+ (1.0,0) [0|252] "" FBD_HL,FBD_HM,FBD_HR,FBD_MM,FBD_Miko,FBD_Trunk,FBD_VM,FBD_VR,IPB_App1
 SG_ StatusUWBRangingFDD2FBD_VL_Tim_3 : 72|32@1+ (1.0,0) [0|4294967292] "" FBD_HL,FBD_HM,FBD_HR,FBD_MM,FBD_Miko,FBD_Trunk,FBD_VM,FBD_VR,IPB_App1
 SG_ StatusUWBRangingFDD2FBD_VL_Tim_4 : 104|8@1+ (1.0,0) [0|252] "" FBD_HL,FBD_HM,FBD_HR,FBD_MM,FBD_Miko,FBD_Trunk,FBD_VM,FBD_VR,IPB_App1
 SG_ StatusUWBRangingFDD2FBD_VL_Sta_2 : 112|8@1+ (1.0,0) [0|252] "" FBD_HL,FBD_HM,FBD_HR,FBD_MM,FBD_Miko,FBD_Trunk,FBD_VM,FBD_VR,IPB_App1
 SG_ StatusUWBRangingFDD2FBD_VL_Ind_3 : 120|8@1+ (1.0,0) [0|252] "" FBD_HL,FBD_HM,FBD_HR,FBD_MM,FBD_Miko,FBD_Trunk,FBD_VM,FBD_VR,IPB_App1
 SG_ StatusUWBRangingFDD2FBD_VL_Tim_5 : 128|32@1+ (1.0,0) [0|4294967292] "" FBD_HL,FBD_HM,FBD_HR,FBD_MM,FBD_Miko,FBD_Trunk,FBD_VM,FBD_VR,IPB_App1
 SG_ StatusUWBRangingFDD2FBD_VL_Tim_6 : 160|8@1+ (1.0,0) [0|252] "" FBD_HL,FBD_HM,FBD_HR,FBD_MM,FBD_Miko,FBD_Trunk,FBD_VM,FBD_VR,IPB_App1
 SG_ StatusUWBRangingFDD2FBD_VL_Sta_3 : 168|8@1+ (1.0,0) [0|252] "" FBD_HL,FBD_HM,FBD_HR,FBD_MM,FBD_Miko,FBD_Trunk,FBD_VM,FBD_VR,IPB_App1
 SG_ StatusUWBRangingFDD2FBD_VL_Ind_4 : 176|8@1+ (1.0,0) [0|252] "" FBD_HL,FBD_HM,FBD_HR,FBD_MM,FBD_Miko,FBD_Trunk,FBD_VM,FBD_VR,IPB_App1
 SG_ StatusUWBRangingFDD2FBD_VL_Tim_7 : 184|32@1+ (1.0,0) [0|4294967292] "" FBD_HL,FBD_HM,FBD_HR,FBD_MM,FBD_Miko,FBD_Trunk,FBD_VM,FBD_VR,IPB_App1
 SG_ StatusUWBRangingFDD2FBD_VL_Tim_8 : 216|8@1+ (1.0,0) [0|252] "" FBD_HL,FBD_HM,FBD_HR,FBD_MM,FBD_Miko,FBD_Trunk,FBD_VM,FBD_VR,IPB_App1
 SG_ StatusUWBRangingFDD2FBD_VL_Sta_4 : 224|8@1+ (1.0,0) [0|252] "" FBD_HL,FBD_HM,FBD_HR,FBD_MM,FBD_Miko,FBD_Trunk,FBD_VM,FBD_VR,IPB_App1
 SG_ StatusUWBRangingFDD2FBD_VL_Tim_9 : 232|64@1+ (1.0,0) [0|18446744073709551612] "" FBD_HL,FBD_HM,FBD_HR,FBD_MM,FBD_Miko,FBD_Trunk,FBD_VM,FBD_VR,IPB_App1
 SG_ StatusUWBRangingFDD2FBD_VL_Signa : 296|64@1+ (1.0,0) [0|18446744073709551614] "" FBD_HL,FBD_HM,FBD_HR,FBD_MM,FBD_Miko,FBD_Trunk,FBD_VM,FBD_VR,IPB_App1
 SG_ StatusUWBRangingFDD2FBD_VL_IV2 : 360|8@1+ (1.0,0) [0|255] "" FBD_HL,FBD_HM,FBD_HR,FBD_MM,FBD_Miko,FBD_Trunk,FBD_VM,FBD_VR,IPB_App1
 SG_ StatusUWBRangingFDD2FBD_VL_IV3 : 368|8@1+ (1.0,0) [0|255] "" FBD_HL,FBD_HM,FBD_HR,FBD_MM,FBD_Miko,FBD_Trunk,FBD_VM,FBD_VR,IPB_App1

BO_ 460 StatusUWBRangingFDD2FBD_VM: 48 FBD_VM
 SG_ StatusUWBRangingFDD2FBD_VM_Sessi : 0|8@1+ (1.0,0) [0|252] "" FBD_HL,FBD_HM,FBD_HR,FBD_MM,FBD_Miko,FBD_Trunk,FBD_VL,FBD_VR,IPB_App1
 SG_ StatusUWBRangingFDD2FBD_VM_Index : 8|8@1+ (1.0,0) [0|252] "" FBD_HL,FBD_HM,FBD_HR,FBD_MM,FBD_Miko,FBD_Trunk,FBD_VL,FBD_VR,IPB_App1
 SG_ StatusUWBRangingFDD2FBD_VM_TimeS : 16|32@1+ (1.0,0) [0|4294967292] "" FBD_HL,FBD_HM,FBD_HR,FBD_MM,FBD_Miko,FBD_Trunk,FBD_VL,FBD_VR,IPB_App1
 SG_ StatusUWBRangingFDD2FBD_VM_Tim_2 : 48|8@1+ (1.0,0) [0|252] "" FBD_HL,FBD_HM,FBD_HR,FBD_MM,FBD_Miko,FBD_Trunk,FBD_VL,FBD_VR,IPB_App1
 SG_ StatusUWBRangingFDD2FBD_VM_Statu : 56|8@1+ (1.0,0) [0|252] "" FBD_HL,FBD_HM,FBD_HR,FBD_MM,FBD_Miko,FBD_Trunk,FBD_VL,FBD_VR,IPB_App1
 SG_ StatusUWBRangingFDD2FBD_VM_Ind_2 : 64|8@1+ (1.0,0) [0|252] "" FBD_HL,FBD_HM,FBD_HR,FBD_MM,FBD_Miko,FBD_Trunk,FBD_VL,FBD_VR,IPB_App1
 SG_ StatusUWBRangingFDD2FBD_VM_Tim_3 : 72|32@1+ (1.0,0) [0|4294967292] "" FBD_HL,FBD_HM,FBD_HR,FBD_MM,FBD_Miko,FBD_Trunk,FBD_VL,FBD_VR,IPB_App1
 SG_ StatusUWBRangingFDD2FBD_VM_Tim_4 : 104|8@1+ (1.0,0) [0|252] "" FBD_HL,FBD_HM,FBD_HR,FBD_MM,FBD_Miko,FBD_Trunk,FBD_VL,FBD_VR,IPB_App1
 SG_ StatusUWBRangingFDD2FBD_VM_Sta_2 : 112|8@1+ (1.0,0) [0|252] "" FBD_HL,FBD_HM,FBD_HR,FBD_MM,FBD_Miko,FBD_Trunk,FBD_VL,FBD_VR,IPB_App1
 SG_ StatusUWBRangingFDD2FBD_VM_Ind_3 : 120|8@1+ (1.0,0) [0|252] "" FBD_HL,FBD_HM,FBD_HR,FBD_MM,FBD_Miko,FBD_Trunk,FBD_VL,FBD_VR,IPB_App1
 SG_ StatusUWBRangingFDD2FBD_VM_Tim_5 : 128|32@1+ (1.0,0) [0|4294967292] "" FBD_HL,FBD_HM,FBD_HR,FBD_MM,FBD_Miko,FBD_Trunk,FBD_VL,FBD_VR,IPB_App1
 SG_ StatusUWBRangingFDD2FBD_VM_Tim_6 : 160|8@1+ (1.0,0) [0|252] "" FBD_HL,FBD_HM,FBD_HR,FBD_MM,FBD_Miko,FBD_Trunk,FBD_VL,FBD_VR,IPB_App1
 SG_ StatusUWBRangingFDD2FBD_VM_Sta_3 : 168|8@1+ (1.0,0) [0|252] "" FBD_HL,FBD_HM,FBD_HR,FBD_MM,FBD_Miko,FBD_Trunk,FBD_VL,FBD_VR,IPB_App1
 SG_ StatusUWBRangingFDD2FBD_VM_Ind_4 : 176|8@1+ (1.0,0) [0|252] "" FBD_HL,FBD_HM,FBD_HR,FBD_MM,FBD_Miko,FBD_Trunk,FBD_VL,FBD_VR,IPB_App1
 SG_ StatusUWBRangingFDD2FBD_VM_Tim_7 : 184|32@1+ (1.0,0) [0|4294967292] "" FBD_HL,FBD_HM,FBD_HR,FBD_MM,FBD_Miko,FBD_Trunk,FBD_VL,FBD_VR,IPB_App1
 SG_ StatusUWBRangingFDD2FBD_VM_Tim_8 : 216|8@1+ (1.0,0) [0|252] "" FBD_HL,FBD_HM,FBD_HR,FBD_MM,FBD_Miko,FBD_Trunk,FBD_VL,FBD_VR,IPB_App1
 SG_ StatusUWBRangingFDD2FBD_VM_Sta_4 : 224|8@1+ (1.0,0) [0|252] "" FBD_HL,FBD_HM,FBD_HR,FBD_MM,FBD_Miko,FBD_Trunk,FBD_VL,FBD_VR,IPB_App1
 SG_ StatusUWBRangingFDD2FBD_VM_Tim_9 : 232|64@1+ (1.0,0) [0|18446744073709551612] "" FBD_HL,FBD_HM,FBD_HR,FBD_MM,FBD_Miko,FBD_Trunk,FBD_VL,FBD_VR,IPB_App1
 SG_ StatusUWBRangingFDD2FBD_VM_Signa : 296|64@1+ (1.0,0) [0|18446744073709551614] "" FBD_HL,FBD_HM,FBD_HR,FBD_MM,FBD_Miko,FBD_Trunk,FBD_VL,FBD_VR,IPB_App1
 SG_ StatusUWBRangingFDD2FBD_VM_IV2 : 360|8@1+ (1.0,0) [0|255] "" FBD_HL,FBD_HM,FBD_HR,FBD_MM,FBD_Miko,FBD_Trunk,FBD_VL,FBD_VR,IPB_App1
 SG_ StatusUWBRangingFDD2FBD_VM_IV3 : 368|8@1+ (1.0,0) [0|255] "" FBD_HL,FBD_HM,FBD_HR,FBD_MM,FBD_Miko,FBD_Trunk,FBD_VL,FBD_VR,IPB_App1

BO_ 465 StatusUWBRangingFDD2FBD_VR: 48 FBD_VR
 SG_ StatusUWBRangingFDD2FBD_VR_Sessi : 0|8@1+ (1.0,0) [0|252] "" FBD_HL,FBD_HM,FBD_HR,FBD_MM,FBD_Miko,FBD_Trunk,FBD_VL,FBD_VM,IPB_App1
 SG_ StatusUWBRangingFDD2FBD_VR_Index : 8|8@1+ (1.0,0) [0|252] "" FBD_HL,FBD_HM,FBD_HR,FBD_MM,FBD_Miko,FBD_Trunk,FBD_VL,FBD_VM,IPB_App1
 SG_ StatusUWBRangingFDD2FBD_VR_TimeS : 16|32@1+ (1.0,0) [0|4294967292] "" FBD_HL,FBD_HM,FBD_HR,FBD_MM,FBD_Miko,FBD_Trunk,FBD_VL,FBD_VM,IPB_App1
 SG_ StatusUWBRangingFDD2FBD_VR_Tim_2 : 48|8@1+ (1.0,0) [0|252] "" FBD_HL,FBD_HM,FBD_HR,FBD_MM,FBD_Miko,FBD_Trunk,FBD_VL,FBD_VM,IPB_App1
 SG_ StatusUWBRangingFDD2FBD_VR_Statu : 56|8@1+ (1.0,0) [0|252] "" FBD_HL,FBD_HM,FBD_HR,FBD_MM,FBD_Miko,FBD_Trunk,FBD_VL,FBD_VM,IPB_App1
 SG_ StatusUWBRangingFDD2FBD_VR_Ind_2 : 64|8@1+ (1.0,0) [0|252] "" FBD_HL,FBD_HM,FBD_HR,FBD_MM,FBD_Miko,FBD_Trunk,FBD_VL,FBD_VM,IPB_App1
 SG_ StatusUWBRangingFDD2FBD_VR_Tim_3 : 72|32@1+ (1.0,0) [0|4294967292] "" FBD_HL,FBD_HM,FBD_HR,FBD_MM,FBD_Miko,FBD_Trunk,FBD_VL,FBD_VM,IPB_App1
 SG_ StatusUWBRangingFDD2FBD_VR_Tim_4 : 104|8@1+ (1.0,0) [0|252] "" FBD_HL,FBD_HM,FBD_HR,FBD_MM,FBD_Miko,FBD_Trunk,FBD_VL,FBD_VM,IPB_App1
 SG_ StatusUWBRangingFDD2FBD_VR_Sta_2 : 112|8@1+ (1.0,0) [0|252] "" FBD_HL,FBD_HM,FBD_HR,FBD_MM,FBD_Miko,FBD_Trunk,FBD_VL,FBD_VM,IPB_App1
 SG_ StatusUWBRangingFDD2FBD_VR_Ind_3 : 120|8@1+ (1.0,0) [0|252] "" FBD_HL,FBD_HM,FBD_HR,FBD_MM,FBD_Miko,FBD_Trunk,FBD_VL,FBD_VM,IPB_App1
 SG_ StatusUWBRangingFDD2FBD_VR_Tim_5 : 128|32@1+ (1.0,0) [0|4294967292] "" FBD_HL,FBD_HM,FBD_HR,FBD_MM,FBD_Miko,FBD_Trunk,FBD_VL,FBD_VM,IPB_App1
 SG_ StatusUWBRangingFDD2FBD_VR_Tim_6 : 160|8@1+ (1.0,0) [0|252] "" FBD_HL,FBD_HM,FBD_HR,FBD_MM,FBD_Miko,FBD_Trunk,FBD_VL,FBD_VM,IPB_App1
 SG_ StatusUWBRangingFDD2FBD_VR_Sta_3 : 168|8@1+ (1.0,0) [0|252] "" FBD_HL,FBD_HM,FBD_HR,FBD_MM,FBD_Miko,FBD_Trunk,FBD_VL,FBD_VM,IPB_App1
 SG_ StatusUWBRangingFDD2FBD_VR_Ind_4 : 176|8@1+ (1.0,0) [0|252] "" FBD_HL,FBD_HM,FBD_HR,FBD_MM,FBD_Miko,FBD_Trunk,FBD_VL,FBD_VM,IPB_App1
 SG_ StatusUWBRangingFDD2FBD_VR_Tim_7 : 184|32@1+ (1.0,0) [0|4294967292] "" FBD_HL,FBD_HM,FBD_HR,FBD_MM,FBD_Miko,FBD_Trunk,FBD_VL,FBD_VM,IPB_App1
 SG_ StatusUWBRangingFDD2FBD_VR_Tim_8 : 216|8@1+ (1.0,0) [0|252] "" FBD_HL,FBD_HM,FBD_HR,FBD_MM,FBD_Miko,FBD_Trunk,FBD_VL,FBD_VM,IPB_App1
 SG_ StatusUWBRangingFDD2FBD_VR_Sta_4 : 224|8@1+ (1.0,0) [0|252] "" FBD_HL,FBD_HM,FBD_HR,FBD_MM,FBD_Miko,FBD_Trunk,FBD_VL,FBD_VM,IPB_App1
 SG_ StatusUWBRangingFDD2FBD_VR_Tim_9 : 232|64@1+ (1.0,0) [0|18446744073709551612] "" FBD_HL,FBD_HM,FBD_HR,FBD_MM,FBD_Miko,FBD_Trunk,FBD_VL,FBD_VM,IPB_App1
 SG_ StatusUWBRangingFDD2FBD_VR_Signa : 296|64@1+ (1.0,0) [0|18446744073709551614] "" FBD_HL,FBD_HM,FBD_HR,FBD_MM,FBD_Miko,FBD_Trunk,FBD_VL,FBD_VM,IPB_App1
 SG_ StatusUWBRangingFDD2FBD_VR_IV2 : 360|8@1+ (1.0,0) [0|255] "" FBD_HL,FBD_HM,FBD_HR,FBD_MM,FBD_Miko,FBD_Trunk,FBD_VL,FBD_VM,IPB_App1
 SG_ StatusUWBRangingFDD2FBD_VR_IV3 : 368|8@1+ (1.0,0) [0|255] "" FBD_HL,FBD_HM,FBD_HR,FBD_MM,FBD_Miko,FBD_Trunk,FBD_VL,FBD_VM,IPB_App1

BO_ 176 StatusWakeUpFBDOnlyMode_HL: 8 FBD_HL
 SG_ StatusWakeUpFBDOnlyMode_HL_Power : 0|8@1+ (1,0) [0|0] "" FBD_HM,FBD_HR,FBD_MM,FBD_Miko,FBD_Trunk,FBD_VL,FBD_VM,FBD_VR,IPB_App1

BO_ 171 StatusWakeUpFBDOnlyMode_HM: 8 FBD_HM
 SG_ StatusWakeUpFBDOnlyMode_HM_Power : 0|8@1+ (1,0) [0|0] "" FBD_HL,FBD_HR,FBD_MM,FBD_Miko,FBD_Trunk,FBD_VL,FBD_VM,FBD_VR,IPB_App1

BO_ 177 StatusWakeUpFBDOnlyMode_HR: 8 FBD_HR
 SG_ StatusWakeUpFBDOnlyMode_HR_Power : 0|8@1+ (1,0) [0|0] "" FBD_HL,FBD_HM,FBD_MM,FBD_Miko,FBD_Trunk,FBD_VL,FBD_VM,FBD_VR,IPB_App1

BO_ 172 StatusWakeUpFBDOnlyMode_Miko: 8 FBD_Miko
 SG_ StatusWakeUpFBDOnlyMode_Miko_Pow : 0|8@1+ (1,0) [0|0] "" FBD_HL,FBD_HM,FBD_HR,FBD_MM,FBD_Trunk,FBD_VL,FBD_VM,FBD_VR,IPB_App1

BO_ 181 StatusWakeUpFBDOnlyMode_MM: 8 FBD_MM
 SG_ StatusWakeUpFBDOnlyMode_MM_Power : 0|8@1+ (1,0) [0|0] "" FBD_HL,FBD_HM,FBD_HR,FBD_Miko,FBD_Trunk,FBD_VL,FBD_VM,FBD_VR,IPB_App1

BO_ 178 StatusWakeUpFBDOnlyMode_SML: 8 IPB_App1
 SG_ StatusWakeUpFBDOnlyMode_SML_Powe : 0|8@1+ (1,0) [0|0] "" FBD_HL,FBD_HM,FBD_HR,FBD_MM,FBD_Miko,FBD_Trunk,FBD_VL,FBD_VM,FBD_VR

BO_ 179 StatusWakeUpFBDOnlyMode_SMR: 8 IPB_App1
 SG_ StatusWakeUpFBDOnlyMode_SMR_Powe : 0|8@1+ (1,0) [0|0] "" FBD_HL,FBD_HM,FBD_HR,FBD_MM,FBD_Miko,FBD_Trunk,FBD_VL,FBD_VM,FBD_VR

BO_ 173 StatusWakeUpFBDOnlyMode_Trunk: 8 FBD_Trunk
 SG_ StatusWakeUpFBDOnlyMode_Trunk_Po : 0|8@1+ (1,0) [0|0] "" FBD_HL,FBD_HM,FBD_HR,FBD_MM,FBD_Miko,FBD_VL,FBD_VM,FBD_VR,IPB_App1

BO_ 174 StatusWakeUpFBDOnlyMode_VL: 8 FBD_VL
 SG_ StatusWakeUpFBDOnlyMode_VL_Power : 0|8@1+ (1,0) [0|0] "" FBD_HL,FBD_HM,FBD_HR,FBD_MM,FBD_Miko,FBD_Trunk,FBD_VM,FBD_VR,IPB_App1

BO_ 170 StatusWakeUpFBDOnlyMode_VM: 8 FBD_VM
 SG_ StatusWakeUpFBDOnlyMode_VM_Power : 0|8@1+ (1,0) [0|0] "" FBD_HL,FBD_HM,FBD_HR,FBD_MM,FBD_Miko,FBD_Trunk,FBD_VL,FBD_VR,IPB_App1

BO_ 175 StatusWakeUpFBDOnlyMode_VR: 8 FBD_VR
 SG_ StatusWakeUpFBDOnlyMode_VR_Power : 0|8@1+ (1,0) [0|0] "" FBD_HL,FBD_HM,FBD_HR,FBD_MM,FBD_Miko,FBD_Trunk,FBD_VL,FBD_VM,IPB_App1

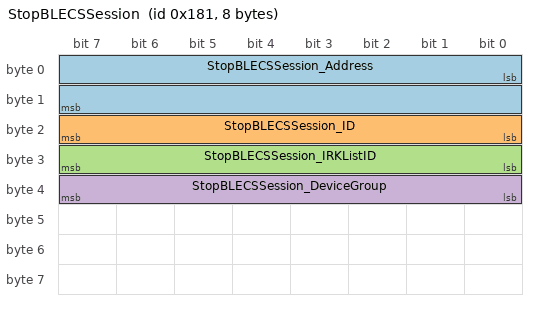
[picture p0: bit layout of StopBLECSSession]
BO_ 385 StopBLECSSession: 8 IPB_App1
 SG_ StopBLECSSession_Address : 0|16@1+ (1,0) [0|0] "" FBD_HL,FBD_HM,FBD_HR,FBD_MM,FBD_Miko,FBD_Trunk,FBD_VL,FBD_VM,FBD_VR
 SG_ StopBLECSSession_ID : 16|8@1+ (1.0,0) [0|252] "" FBD_HL,FBD_HM,FBD_HR,FBD_MM,FBD_Miko,FBD_Trunk,FBD_VL,FBD_VM,FBD_VR
 SG_ StopBLECSSession_IRKListID : 24|8@1+ (1.0,0) [0|252] "" FBD_HL,FBD_HM,FBD_HR,FBD_MM,FBD_Miko,FBD_Trunk,FBD_VL,FBD_VM,FBD_VR
 SG_ StopBLECSSession_DeviceGroup : 32|8@1+ (1.0,0) [0|252] "" FBD_HL,FBD_HM,FBD_HR,FBD_MM,FBD_Miko,FBD_Trunk,FBD_VL,FBD_VM,FBD_VR

BO_ 116 TimeSyncDeviceOffsetFBD_HL: 16 FBD_HL
 SG_ TimeSyncDeviceOffsetFBD_HL_Sessi : 0|8@1+ (1.0,0) [0|252] "" FBD_HM,FBD_HR,FBD_MM,FBD_Miko,FBD_Trunk,FBD_VL,FBD_VM,FBD_VR,IPB_App1
 SG_ TimeSyncDeviceOffsetFBD_HL_IRKLi : 8|8@1+ (1.0,0) [0|252] "" FBD_HM,FBD_HR,FBD_MM,FBD_Miko,FBD_Trunk,FBD_VL,FBD_VM,FBD_VR,IPB_App1
 SG_ TimeSyncDeviceOffsetFBD_HL_TimeO : 16|64@1+ (1.0,0) [0|18446744073709551612] "" FBD_HM,FBD_HR,FBD_MM,FBD_Miko,FBD_Trunk,FBD_VL,FBD_VM,FBD_VR,IPB_App1
 SG_ TimeSyncDeviceOffsetFBD_HL_Tim_2 : 80|16@1+ (1.0,0) [0|65532] "" FBD_HM,FBD_HR,FBD_MM,FBD_Miko,FBD_Trunk,FBD_VL,FBD_VM,FBD_VR,IPB_App1
 SG_ TimeSyncDeviceOffsetFBD_HL_UWBDe : 96|8@1+ (1.0,0) [0|252] "" FBD_HM,FBD_HR,FBD_MM,FBD_Miko,FBD_Trunk,FBD_VL,FBD_VM,FBD_VR,IPB_App1
 SG_ TimeSyncDeviceOffsetFBD_HL_UWB_2 : 104|16@1+ (1.0,0) [0|65532] "" FBD_HM,FBD_HR,FBD_MM,FBD_Miko,FBD_Trunk,FBD_VL,FBD_VM,FBD_VR,IPB_App1
 SG_ TimeSyncDeviceOffsetFBD_HL_UWBCl : 120|8@1+ (1.0,0) [0|252] "" FBD_HM,FBD_HR,FBD_MM,FBD_Miko,FBD_Trunk,FBD_VL,FBD_VM,FBD_VR,IPB_App1

BO_ 111 TimeSyncDeviceOffsetFBD_HM: 16 FBD_HM
 SG_ TimeSyncDeviceOffsetFBD_HM_Sessi : 0|8@1+ (1.0,0) [0|252] "" FBD_HL,FBD_HR,FBD_MM,FBD_Miko,FBD_Trunk,FBD_VL,FBD_VM,FBD_VR,IPB_App1
 SG_ TimeSyncDeviceOffsetFBD_HM_IRKLi : 8|8@1+ (1.0,0) [0|252] "" FBD_HL,FBD_HR,FBD_MM,FBD_Miko,FBD_Trunk,FBD_VL,FBD_VM,FBD_VR,IPB_App1
 SG_ TimeSyncDeviceOffsetFBD_HM_TimeO : 16|64@1+ (1.0,0) [0|18446744073709551612] "" FBD_HL,FBD_HR,FBD_MM,FBD_Miko,FBD_Trunk,FBD_VL,FBD_VM,FBD_VR,IPB_App1
 SG_ TimeSyncDeviceOffsetFBD_HM_Tim_2 : 80|16@1+ (1.0,0) [0|65532] "" FBD_HL,FBD_HR,FBD_MM,FBD_Miko,FBD_Trunk,FBD_VL,FBD_VM,FBD_VR,IPB_App1
 SG_ TimeSyncDeviceOffsetFBD_HM_UWBDe : 96|8@1+ (1.0,0) [0|252] "" FBD_HL,FBD_HR,FBD_MM,FBD_Miko,FBD_Trunk,FBD_VL,FBD_VM,FBD_VR,IPB_App1
 SG_ TimeSyncDeviceOffsetFBD_HM_UWB_2 : 104|16@1+ (1.0,0) [0|65532] "" FBD_HL,FBD_HR,FBD_MM,FBD_Miko,FBD_Trunk,FBD_VL,FBD_VM,FBD_VR,IPB_App1
 SG_ TimeSyncDeviceOffsetFBD_HM_UWBCl : 120|8@1+ (1.0,0) [0|252] "" FBD_HL,FBD_HR,FBD_MM,FBD_Miko,FBD_Trunk,FBD_VL,FBD_VM,FBD_VR,IPB_App1

BO_ 117 TimeSyncDeviceOffsetFBD_HR: 16 FBD_HR
 SG_ TimeSyncDeviceOffsetFBD_HR_Sessi : 0|8@1+ (1.0,0) [0|252] "" FBD_HL,FBD_HM,FBD_MM,FBD_Miko,FBD_Trunk,FBD_VL,FBD_VM,FBD_VR,IPB_App1
 SG_ TimeSyncDeviceOffsetFBD_HR_IRKLi : 8|8@1+ (1.0,0) [0|252] "" FBD_HL,FBD_HM,FBD_MM,FBD_Miko,FBD_Trunk,FBD_VL,FBD_VM,FBD_VR,IPB_App1
 SG_ TimeSyncDeviceOffsetFBD_HR_TimeO : 16|64@1+ (1.0,0) [0|18446744073709551612] "" FBD_HL,FBD_HM,FBD_MM,FBD_Miko,FBD_Trunk,FBD_VL,FBD_VM,FBD_VR,IPB_App1
 SG_ TimeSyncDeviceOffsetFBD_HR_Tim_2 : 80|16@1+ (1.0,0) [0|65532] "" FBD_HL,FBD_HM,FBD_MM,FBD_Miko,FBD_Trunk,FBD_VL,FBD_VM,FBD_VR,IPB_App1
 SG_ TimeSyncDeviceOffsetFBD_HR_UWBDe : 96|8@1+ (1.0,0) [0|252] "" FBD_HL,FBD_HM,FBD_MM,FBD_Miko,FBD_Trunk,FBD_VL,FBD_VM,FBD_VR,IPB_App1
 SG_ TimeSyncDeviceOffsetFBD_HR_UWB_2 : 104|16@1+ (1.0,0) [0|65532] "" FBD_HL,FBD_HM,FBD_MM,FBD_Miko,FBD_Trunk,FBD_VL,FBD_VM,FBD_VR,IPB_App1
 SG_ TimeSyncDeviceOffsetFBD_HR_UWBCl : 120|8@1+ (1.0,0) [0|252] "" FBD_HL,FBD_HM,FBD_MM,FBD_Miko,FBD_Trunk,FBD_VL,FBD_VM,FBD_VR,IPB_App1

BO_ 112 TimeSyncDeviceOffsetFBD_Miko: 16 FBD_Miko
 SG_ TimeSyncDeviceOffsetFBD_Miko_Ses : 0|8@1+ (1.0,0) [0|252] "" FBD_HL,FBD_HM,FBD_HR,FBD_MM,FBD_Trunk,FBD_VL,FBD_VM,FBD_VR,IPB_App1
 SG_ TimeSyncDeviceOffsetFBD_Miko_IRK : 8|8@1+ (1.0,0) [0|252] "" FBD_HL,FBD_HM,FBD_HR,FBD_MM,FBD_Trunk,FBD_VL,FBD_VM,FBD_VR,IPB_App1
 SG_ TimeSyncDeviceOffsetFBD_Miko_Tim : 16|64@1+ (1.0,0) [0|18446744073709551612] "" FBD_HL,FBD_HM,FBD_HR,FBD_MM,FBD_Trunk,FBD_VL,FBD_VM,FBD_VR,IPB_App1
 SG_ TimeSyncDeviceOffsetFBD_Miko_T_2 : 80|16@1+ (1.0,0) [0|65532] "" FBD_HL,FBD_HM,FBD_HR,FBD_MM,FBD_Trunk,FBD_VL,FBD_VM,FBD_VR,IPB_App1
 SG_ TimeSyncDeviceOffsetFBD_Miko_UWB : 96|8@1+ (1.0,0) [0|252] "" FBD_HL,FBD_HM,FBD_HR,FBD_MM,FBD_Trunk,FBD_VL,FBD_VM,FBD_VR,IPB_App1
 SG_ TimeSyncDeviceOffsetFBD_Miko_U_2 : 104|16@1+ (1.0,0) [0|65532] "" FBD_HL,FBD_HM,FBD_HR,FBD_MM,FBD_Trunk,FBD_VL,FBD_VM,FBD_VR,IPB_App1
 SG_ TimeSyncDeviceOffsetFBD_Miko_U_3 : 120|8@1+ (1.0,0) [0|252] "" FBD_HL,FBD_HM,FBD_HR,FBD_MM,FBD_Trunk,FBD_VL,FBD_VM,FBD_VR,IPB_App1

BO_ 811 TimeSyncDeviceOffsetFBD_MM: 16 FBD_MM
 SG_ TimeSyncDeviceOffsetFBD_MM_Sessi : 0|8@1+ (1.0,0) [0|252] "" FBD_HL,FBD_HM,FBD_HR,FBD_Miko,FBD_Trunk,FBD_VL,FBD_VM,FBD_VR,IPB_App1
 SG_ TimeSyncDeviceOffsetFBD_MM_IRKLi : 8|8@1+ (1.0,0) [0|252] "" FBD_HL,FBD_HM,FBD_HR,FBD_Miko,FBD_Trunk,FBD_VL,FBD_VM,FBD_VR,IPB_App1
 SG_ TimeSyncDeviceOffsetFBD_MM_TimeO : 16|64@1+ (1.0,0) [0|18446744073709551612] "" FBD_HL,FBD_HM,FBD_HR,FBD_Miko,FBD_Trunk,FBD_VL,FBD_VM,FBD_VR,IPB_App1
 SG_ TimeSyncDeviceOffsetFBD_MM_Tim_2 : 80|16@1+ (1.0,0) [0|65532] "" FBD_HL,FBD_HM,FBD_HR,FBD_Miko,FBD_Trunk,FBD_VL,FBD_VM,FBD_VR,IPB_App1
 SG_ TimeSyncDeviceOffsetFBD_MM_UWBDe : 96|8@1+ (1.0,0) [0|252] "" FBD_HL,FBD_HM,FBD_HR,FBD_Miko,FBD_Trunk,FBD_VL,FBD_VM,FBD_VR,IPB_App1
 SG_ TimeSyncDeviceOffsetFBD_MM_UWB_2 : 104|16@1+ (1.0,0) [0|65532] "" FBD_HL,FBD_HM,FBD_HR,FBD_Miko,FBD_Trunk,FBD_VL,FBD_VM,FBD_VR,IPB_App1
 SG_ TimeSyncDeviceOffsetFBD_MM_UWBCl : 120|8@1+ (1.0,0) [0|252] "" FBD_HL,FBD_HM,FBD_HR,FBD_Miko,FBD_Trunk,FBD_VL,FBD_VM,FBD_VR,IPB_App1

BO_ 118 TimeSyncDeviceOffsetFBD_SML: 16 IPB_App1
 SG_ TimeSyncDeviceOffsetFBD_SML_Sess : 0|8@1+ (1.0,0) [0|252] "" FBD_HL,FBD_HM,FBD_HR,FBD_MM,FBD_Miko,FBD_Trunk,FBD_VL,FBD_VM,FBD_VR
 SG_ TimeSyncDeviceOffsetFBD_SML_IRKL : 8|8@1+ (1.0,0) [0|252] "" FBD_HL,FBD_HM,FBD_HR,FBD_MM,FBD_Miko,FBD_Trunk,FBD_VL,FBD_VM,FBD_VR
 SG_ TimeSyncDeviceOffsetFBD_SML_Time : 16|64@1+ (1.0,0) [0|18446744073709551612] "" FBD_HL,FBD_HM,FBD_HR,FBD_MM,FBD_Miko,FBD_Trunk,FBD_VL,FBD_VM,FBD_VR
 SG_ TimeSyncDeviceOffsetFBD_SML_Ti_2 : 80|16@1+ (1.0,0) [0|65532] "" FBD_HL,FBD_HM,FBD_HR,FBD_MM,FBD_Miko,FBD_Trunk,FBD_VL,FBD_VM,FBD_VR
 SG_ TimeSyncDeviceOffsetFBD_SML_UWBD : 96|8@1+ (1.0,0) [0|252] "" FBD_HL,FBD_HM,FBD_HR,FBD_MM,FBD_Miko,FBD_Trunk,FBD_VL,FBD_VM,FBD_VR
 SG_ TimeSyncDeviceOffsetFBD_SML_UW_2 : 104|16@1+ (1.0,0) [0|65532] "" FBD_HL,FBD_HM,FBD_HR,FBD_MM,FBD_Miko,FBD_Trunk,FBD_VL,FBD_VM,FBD_VR
 SG_ TimeSyncDeviceOffsetFBD_SML_UWBC : 120|8@1+ (1.0,0) [0|252] "" FBD_HL,FBD_HM,FBD_HR,FBD_MM,FBD_Miko,FBD_Trunk,FBD_VL,FBD_VM,FBD_VR

BO_ 119 TimeSyncDeviceOffsetFBD_SMR: 16 IPB_App1
 SG_ TimeSyncDeviceOffsetFBD_SMR_Sess : 0|8@1+ (1.0,0) [0|252] "" FBD_HL,FBD_HM,FBD_HR,FBD_MM,FBD_Miko,FBD_Trunk,FBD_VL,FBD_VM,FBD_VR
 SG_ TimeSyncDeviceOffsetFBD_SMR_IRKL : 8|8@1+ (1.0,0) [0|252] "" FBD_HL,FBD_HM,FBD_HR,FBD_MM,FBD_Miko,FBD_Trunk,FBD_VL,FBD_VM,FBD_VR
 SG_ TimeSyncDeviceOffsetFBD_SMR_Time : 16|64@1+ (1.0,0) [0|18446744073709551612] "" FBD_HL,FBD_HM,FBD_HR,FBD_MM,FBD_Miko,FBD_Trunk,FBD_VL,FBD_VM,FBD_VR
 SG_ TimeSyncDeviceOffsetFBD_SMR_Ti_2 : 80|16@1+ (1.0,0) [0|65532] "" FBD_HL,FBD_HM,FBD_HR,FBD_MM,FBD_Miko,FBD_Trunk,FBD_VL,FBD_VM,FBD_VR
 SG_ TimeSyncDeviceOffsetFBD_SMR_UWBD : 96|8@1+ (1.0,0) [0|252] "" FBD_HL,FBD_HM,FBD_HR,FBD_MM,FBD_Miko,FBD_Trunk,FBD_VL,FBD_VM,FBD_VR
 SG_ TimeSyncDeviceOffsetFBD_SMR_UW_2 : 104|16@1+ (1.0,0) [0|65532] "" FBD_HL,FBD_HM,FBD_HR,FBD_MM,FBD_Miko,FBD_Trunk,FBD_VL,FBD_VM,FBD_VR
 SG_ TimeSyncDeviceOffsetFBD_SMR_UWBC : 120|8@1+ (1.0,0) [0|252] "" FBD_HL,FBD_HM,FBD_HR,FBD_MM,FBD_Miko,FBD_Trunk,FBD_VL,FBD_VM,FBD_VR

BO_ 113 TimeSyncDeviceOffsetFBD_Trunk: 16 FBD_Trunk
 SG_ TimeSyncDeviceOffsetFBD_Trunk_Se : 0|8@1+ (1.0,0) [0|252] "" FBD_HL,FBD_HM,FBD_HR,FBD_MM,FBD_Miko,FBD_VL,FBD_VM,FBD_VR,IPB_App1
 SG_ TimeSyncDeviceOffsetFBD_Trunk_IR : 8|8@1+ (1.0,0) [0|252] "" FBD_HL,FBD_HM,FBD_HR,FBD_MM,FBD_Miko,FBD_VL,FBD_VM,FBD_VR,IPB_App1
 SG_ TimeSyncDeviceOffsetFBD_Trunk_Ti : 16|64@1+ (1.0,0) [0|18446744073709551612] "" FBD_HL,FBD_HM,FBD_HR,FBD_MM,FBD_Miko,FBD_VL,FBD_VM,FBD_VR,IPB_App1
 SG_ TimeSyncDeviceOffsetFBD_Trunk__2 : 80|16@1+ (1.0,0) [0|65532] "" FBD_HL,FBD_HM,FBD_HR,FBD_MM,FBD_Miko,FBD_VL,FBD_VM,FBD_VR,IPB_App1
 SG_ TimeSyncDeviceOffsetFBD_Trunk_UW : 96|8@1+ (1.0,0) [0|252] "" FBD_HL,FBD_HM,FBD_HR,FBD_MM,FBD_Miko,FBD_VL,FBD_VM,FBD_VR,IPB_App1
 SG_ TimeSyncDeviceOffsetFBD_Trunk__3 : 104|16@1+ (1.0,0) [0|65532] "" FBD_HL,FBD_HM,FBD_HR,FBD_MM,FBD_Miko,FBD_VL,FBD_VM,FBD_VR,IPB_App1
 SG_ TimeSyncDeviceOffsetFBD_Trunk__4 : 120|8@1+ (1.0,0) [0|252] "" FBD_HL,FBD_HM,FBD_HR,FBD_MM,FBD_Miko,FBD_VL,FBD_VM,FBD_VR,IPB_App1

BO_ 114 TimeSyncDeviceOffsetFBD_VL: 16 FBD_VL
 SG_ TimeSyncDeviceOffsetFBD_VL_Sessi : 0|8@1+ (1.0,0) [0|252] "" FBD_HL,FBD_HM,FBD_HR,FBD_MM,FBD_Miko,FBD_Trunk,FBD_VM,FBD_VR,IPB_App1
 SG_ TimeSyncDeviceOffsetFBD_VL_IRKLi : 8|8@1+ (1.0,0) [0|252] "" FBD_HL,FBD_HM,FBD_HR,FBD_MM,FBD_Miko,FBD_Trunk,FBD_VM,FBD_VR,IPB_App1
 SG_ TimeSyncDeviceOffsetFBD_VL_TimeO : 16|64@1+ (1.0,0) [0|18446744073709551612] "" FBD_HL,FBD_HM,FBD_HR,FBD_MM,FBD_Miko,FBD_Trunk,FBD_VM,FBD_VR,IPB_App1
 SG_ TimeSyncDeviceOffsetFBD_VL_Tim_2 : 80|16@1+ (1.0,0) [0|65532] "" FBD_HL,FBD_HM,FBD_HR,FBD_MM,FBD_Miko,FBD_Trunk,FBD_VM,FBD_VR,IPB_App1
 SG_ TimeSyncDeviceOffsetFBD_VL_UWBDe : 96|8@1+ (1.0,0) [0|252] "" FBD_HL,FBD_HM,FBD_HR,FBD_MM,FBD_Miko,FBD_Trunk,FBD_VM,FBD_VR,IPB_App1
 SG_ TimeSyncDeviceOffsetFBD_VL_UWB_2 : 104|16@1+ (1.0,0) [0|65532] "" FBD_HL,FBD_HM,FBD_HR,FBD_MM,FBD_Miko,FBD_Trunk,FBD_VM,FBD_VR,IPB_App1
 SG_ TimeSyncDeviceOffsetFBD_VL_UWBCl : 120|8@1+ (1.0,0) [0|252] "" FBD_HL,FBD_HM,FBD_HR,FBD_MM,FBD_Miko,FBD_Trunk,FBD_VM,FBD_VR,IPB_App1

BO_ 110 TimeSyncDeviceOffsetFBD_VM: 16 FBD_VM
 SG_ TimeSyncDeviceOffsetFBD_VM_Sessi : 0|8@1+ (1.0,0) [0|252] "" FBD_HL,FBD_HM,FBD_HR,FBD_MM,FBD_Miko,FBD_Trunk,FBD_VL,FBD_VR,IPB_App1
 SG_ TimeSyncDeviceOffsetFBD_VM_IRKLi : 8|8@1+ (1.0,0) [0|252] "" FBD_HL,FBD_HM,FBD_HR,FBD_MM,FBD_Miko,FBD_Trunk,FBD_VL,FBD_VR,IPB_App1
 SG_ TimeSyncDeviceOffsetFBD_VM_TimeO : 16|64@1+ (1.0,0) [0|18446744073709551612] "" FBD_HL,FBD_HM,FBD_HR,FBD_MM,FBD_Miko,FBD_Trunk,FBD_VL,FBD_VR,IPB_App1
 SG_ TimeSyncDeviceOffsetFBD_VM_Tim_2 : 80|16@1+ (1.0,0) [0|65532] "" FBD_HL,FBD_HM,FBD_HR,FBD_MM,FBD_Miko,FBD_Trunk,FBD_VL,FBD_VR,IPB_App1
 SG_ TimeSyncDeviceOffsetFBD_VM_UWBDe : 96|8@1+ (1.0,0) [0|252] "" FBD_HL,FBD_HM,FBD_HR,FBD_MM,FBD_Miko,FBD_Trunk,FBD_VL,FBD_VR,IPB_App1
 SG_ TimeSyncDeviceOffsetFBD_VM_UWB_2 : 104|16@1+ (1.0,0) [0|65532] "" FBD_HL,FBD_HM,FBD_HR,FBD_MM,FBD_Miko,FBD_Trunk,FBD_VL,FBD_VR,IPB_App1
 SG_ TimeSyncDeviceOffsetFBD_VM_UWBCl : 120|8@1+ (1.0,0) [0|252] "" FBD_HL,FBD_HM,FBD_HR,FBD_MM,FBD_Miko,FBD_Trunk,FBD_VL,FBD_VR,IPB_App1

BO_ 115 TimeSyncDeviceOffsetFBD_VR: 16 FBD_VR
 SG_ TimeSyncDeviceOffsetFBD_VR_Sessi : 0|8@1+ (1.0,0) [0|252] "" FBD_HL,FBD_HM,FBD_HR,FBD_MM,FBD_Miko,FBD_Trunk,FBD_VL,FBD_VM,IPB_App1
 SG_ TimeSyncDeviceOffsetFBD_VR_IRKLi : 8|8@1+ (1.0,0) [0|252] "" FBD_HL,FBD_HM,FBD_HR,FBD_MM,FBD_Miko,FBD_Trunk,FBD_VL,FBD_VM,IPB_App1
 SG_ TimeSyncDeviceOffsetFBD_VR_TimeO : 16|64@1+ (1.0,0) [0|18446744073709551612] "" FBD_HL,FBD_HM,FBD_HR,FBD_MM,FBD_Miko,FBD_Trunk,FBD_VL,FBD_VM,IPB_App1
 SG_ TimeSyncDeviceOffsetFBD_VR_Tim_2 : 80|16@1+ (1.0,0) [0|65532] "" FBD_HL,FBD_HM,FBD_HR,FBD_MM,FBD_Miko,FBD_Trunk,FBD_VL,FBD_VM,IPB_App1
 SG_ TimeSyncDeviceOffsetFBD_VR_UWBDe : 96|8@1+ (1.0,0) [0|252] "" FBD_HL,FBD_HM,FBD_HR,FBD_MM,FBD_Miko,FBD_Trunk,FBD_VL,FBD_VM,IPB_App1
 SG_ TimeSyncDeviceOffsetFBD_VR_UWB_2 : 104|16@1+ (1.0,0) [0|65532] "" FBD_HL,FBD_HM,FBD_HR,FBD_MM,FBD_Miko,FBD_Trunk,FBD_VL,FBD_VM,IPB_App1
 SG_ TimeSyncDeviceOffsetFBD_VR_UWBCl : 120|8@1+ (1.0,0) [0|252] "" FBD_HL,FBD_HM,FBD_HR,FBD_MM,FBD_Miko,FBD_Trunk,FBD_VL,FBD_VM,IPB_App1

BO_ 106 TimeSyncFBD_HL: 8 FBD_HL
 SG_ TimeSyncFBD_HL_SyncTime : 0|64@1+ (1.0,0) [0|18446744073709551612] "" FBD_HM,FBD_HR,FBD_MM,FBD_Miko,FBD_Trunk,FBD_VL,FBD_VM,FBD_VR,IPB_App1

BO_ 101 TimeSyncFBD_HM: 8 FBD_HM
 SG_ TimeSyncFBD_HM_SyncTime : 0|64@1+ (1.0,0) [0|18446744073709551612] "" FBD_HL,FBD_HR,FBD_MM,FBD_Miko,FBD_Trunk,FBD_VL,FBD_VM,FBD_VR,IPB_App1

BO_ 107 TimeSyncFBD_HR: 8 FBD_HR
 SG_ TimeSyncFBD_HR_SyncTime : 0|64@1+ (1.0,0) [0|18446744073709551612] "" FBD_HL,FBD_HM,FBD_MM,FBD_Miko,FBD_Trunk,FBD_VL,FBD_VM,FBD_VR,IPB_App1

BO_ 102 TimeSyncFBD_Miko: 8 FBD_Miko
 SG_ TimeSyncFBD_Miko_SyncTime : 0|64@1+ (1.0,0) [0|18446744073709551612] "" FBD_HL,FBD_HM,FBD_HR,FBD_MM,FBD_Trunk,FBD_VL,FBD_VM,FBD_VR,IPB_App1

BO_ 810 TimeSyncFBD_MM: 8 FBD_MM
 SG_ TimeSyncFBD_MM_SyncTime : 0|64@1+ (1.0,0) [0|18446744073709551612] "" IPB_App1

BO_ 108 TimeSyncFBD_SML: 8 IPB_App1
 SG_ TimeSyncFBD_SML_SyncTime : 0|64@1+ (1.0,0) [0|18446744073709551612] "" FBD_HL,FBD_HM,FBD_HR,FBD_MM,FBD_Miko,FBD_Trunk,FBD_VL,FBD_VM,FBD_VR

BO_ 109 TimeSyncFBD_SMR: 8 IPB_App1
 SG_ TimeSyncFBD_SMR_SyncTime : 0|64@1+ (1.0,0) [0|18446744073709551612] "" FBD_HL,FBD_HM,FBD_HR,FBD_MM,FBD_Miko,FBD_Trunk,FBD_VL,FBD_VM,FBD_VR

BO_ 103 TimeSyncFBD_Trunk: 8 FBD_Trunk
 SG_ TimeSyncFBD_Trunk_SyncTime : 0|64@1+ (1.0,0) [0|18446744073709551612] "" FBD_HL,FBD_HM,FBD_HR,FBD_MM,FBD_Miko,FBD_VL,FBD_VM,FBD_VR,IPB_App1

BO_ 104 TimeSyncFBD_VL: 8 FBD_VL
 SG_ TimeSyncFBD_VL_SyncTime : 0|64@1+ (1.0,0) [0|18446744073709551612] "" FBD_HL,FBD_HM,FBD_HR,FBD_MM,FBD_Miko,FBD_Trunk,FBD_VM,FBD_VR,IPB_App1

BO_ 100 TimeSyncFBD_VM: 8 FBD_VM
 SG_ TimeSyncFBD_VM_SyncTime : 0|64@1+ (1.0,0) [0|18446744073709551612] "" FBD_HL,FBD_HM,FBD_HR,FBD_MM,FBD_Miko,FBD_Trunk,FBD_VL,FBD_VR,IPB_App1

BO_ 105 TimeSyncFBD_VR: 8 FBD_VR
 SG_ TimeSyncFBD_VR_SyncTime : 0|64@1+ (1.0,0) [0|18446744073709551612] "" FBD_HL,FBD_HM,FBD_HR,FBD_MM,FBD_Miko,FBD_Trunk,FBD_VL,FBD_VM,IPB_App1

BO_ 516 TPBLEDaten_FBD_HL_IPB: 64 FBD_HL
 SG_ TPBLEDatenFBD_HLIPB_Byte00 : 0|8@1+ (1.0,0) [0|252] "" IPB_App1
 SG_ TPBLEDatenFBD_HLIPB_Byte01 : 8|8@1+ (1.0,0) [0|252] "" IPB_App1
 SG_ TPBLEDatenFBD_HLIPB_Byte02 : 16|8@1+ (1.0,0) [0|252] "" IPB_App1
 SG_ TPBLEDatenFBD_HLIPB_Byte03 : 24|8@1+ (1.0,0) [0|252] "" IPB_App1
 SG_ TPBLEDatenFBD_HLIPB_Byte04 : 32|8@1+ (1.0,0) [0|252] "" IPB_App1
 SG_ TPBLEDatenFBD_HLIPB_Byte05 : 40|8@1+ (1.0,0) [0|252] "" IPB_App1
 SG_ TPBLEDatenFBD_HLIPB_Byte06 : 48|8@1+ (1.0,0) [0|252] "" IPB_App1
 SG_ TPBLEDatenFBD_HLIPB_Byte07 : 56|8@1+ (1.0,0) [0|252] "" IPB_App1
 SG_ TPBLEDatenFBD_HLIPB_Byte08 : 64|8@1+ (1.0,0) [0|252] "" IPB_App1
 SG_ TPBLEDatenFBD_HLIPB_Byte09 : 72|8@1+ (1.0,0) [0|252] "" IPB_App1
 SG_ TPBLEDatenFBD_HLIPB_Byte10 : 80|8@1+ (1.0,0) [0|252] "" IPB_App1
 SG_ TPBLEDatenFBD_HLIPB_Byte11 : 88|8@1+ (1.0,0) [0|252] "" IPB_App1
 SG_ TPBLEDatenFBD_HLIPB_Byte12 : 96|8@1+ (1.0,0) [0|252] "" IPB_App1
 SG_ TPBLEDatenFBD_HLIPB_Byte13 : 104|8@1+ (1.0,0) [0|252] "" IPB_App1
 SG_ TPBLEDatenFBD_HLIPB_Byte14 : 112|8@1+ (1.0,0) [0|252] "" IPB_App1
 SG_ TPBLEDatenFBD_HLIPB_Byte15 : 120|8@1+ (1.0,0) [0|252] "" IPB_App1
 SG_ TPBLEDatenFBD_HLIPB_Byte16 : 128|8@1+ (1.0,0) [0|252] "" IPB_App1
 SG_ TPBLEDatenFBD_HLIPB_Byte17 : 136|8@1+ (1.0,0) [0|252] "" IPB_App1
 SG_ TPBLEDatenFBD_HLIPB_Byte18 : 144|8@1+ (1.0,0) [0|252] "" IPB_App1
 SG_ TPBLEDatenFBD_HLIPB_Byte19 : 152|8@1+ (1.0,0) [0|252] "" IPB_App1
 SG_ TPBLEDatenFBD_HLIPB_Byte20 : 160|8@1+ (1.0,0) [0|252] "" IPB_App1
 SG_ TPBLEDatenFBD_HLIPB_Byte21 : 168|8@1+ (1.0,0) [0|252] "" IPB_App1
 SG_ TPBLEDatenFBD_HLIPB_Byte22 : 176|8@1+ (1.0,0) [0|252] "" IPB_App1
 SG_ TPBLEDatenFBD_HLIPB_Byte23 : 184|8@1+ (1.0,0) [0|252] "" IPB_App1
 SG_ TPBLEDatenFBD_HLIPB_Byte24 : 192|8@1+ (1.0,0) [0|252] "" IPB_App1
 SG_ TPBLEDatenFBD_HLIPB_Byte25 : 200|8@1+ (1.0,0) [0|252] "" IPB_App1
 SG_ TPBLEDatenFBD_HLIPB_Byte26 : 208|8@1+ (1.0,0) [0|252] "" IPB_App1
 SG_ TPBLEDatenFBD_HLIPB_Byte27 : 216|8@1+ (1.0,0) [0|252] "" IPB_App1
 SG_ TPBLEDatenFBD_HLIPB_Byte28 : 224|8@1+ (1.0,0) [0|252] "" IPB_App1
 SG_ TPBLEDatenFBD_HLIPB_Byte29 : 232|8@1+ (1.0,0) [0|252] "" IPB_App1
 SG_ TPBLEDatenFBD_HLIPB_Byte30 : 240|8@1+ (1.0,0) [0|252] "" IPB_App1
 SG_ TPBLEDatenFBD_HLIPB_Byte31 : 248|8@1+ (1.0,0) [0|252] "" IPB_App1
 SG_ TPBLEDatenFBD_HLIPB_Byte32 : 256|8@1+ (1.0,0) [0|252] "" IPB_App1
 SG_ TPBLEDatenFBD_HLIPB_Byte33 : 264|8@1+ (1.0,0) [0|252] "" IPB_App1
 SG_ TPBLEDatenFBD_HLIPB_Byte34 : 272|8@1+ (1.0,0) [0|252] "" IPB_App1
 SG_ TPBLEDatenFBD_HLIPB_Byte35 : 280|8@1+ (1.0,0) [0|252] "" IPB_App1
 SG_ TPBLEDatenFBD_HLIPB_Byte36 : 288|8@1+ (1.0,0) [0|252] "" IPB_App1
 SG_ TPBLEDatenFBD_HLIPB_Byte37 : 296|8@1+ (1.0,0) [0|252] "" IPB_App1
 SG_ TPBLEDatenFBD_HLIPB_Byte38 : 304|8@1+ (1.0,0) [0|252] "" IPB_App1
 SG_ TPBLEDatenFBD_HLIPB_Byte39 : 312|8@1+ (1.0,0) [0|252] "" IPB_App1
 SG_ TPBLEDatenFBD_HLIPB_Byte40 : 320|8@1+ (1.0,0) [0|252] "" IPB_App1
 SG_ TPBLEDatenFBD_HLIPB_Byte41 : 328|8@1+ (1.0,0) [0|252] "" IPB_App1
 SG_ TPBLEDatenFBD_HLIPB_Byte42 : 336|8@1+ (1.0,0) [0|252] "" IPB_App1
 SG_ TPBLEDatenFBD_HLIPB_Byte43 : 344|8@1+ (1.0,0) [0|252] "" IPB_App1
 SG_ TPBLEDatenFBD_HLIPB_Byte44 : 352|8@1+ (1.0,0) [0|252] "" IPB_App1
 SG_ TPBLEDatenFBD_HLIPB_Byte45 : 360|8@1+ (1.0,0) [0|252] "" IPB_App1
 SG_ TPBLEDatenFBD_HLIPB_Byte46 : 368|8@1+ (1.0,0) [0|252] "" IPB_App1
 SG_ TPBLEDatenFBD_HLIPB_Byte47 : 376|8@1+ (1.0,0) [0|252] "" IPB_App1
 SG_ TPBLEDatenFBD_HLIPB_Byte48 : 384|8@1+ (1.0,0) [0|252] "" IPB_App1
 SG_ TPBLEDatenFBD_HLIPB_Byte49 : 392|8@1+ (1.0,0) [0|252] "" IPB_App1
 SG_ TPBLEDatenFBD_HLIPB_Byte50 : 400|8@1+ (1.0,0) [0|252] "" IPB_App1
 SG_ TPBLEDatenFBD_HLIPB_Byte51 : 408|8@1+ (1.0,0) [0|252] "" IPB_App1
 SG_ TPBLEDatenFBD_HLIPB_Byte52 : 416|8@1+ (1.0,0) [0|252] "" IPB_App1
 SG_ TPBLEDatenFBD_HLIPB_Byte53 : 424|8@1+ (1.0,0) [0|252] "" IPB_App1
 SG_ TPBLEDatenFBD_HLIPB_Byte54 : 432|8@1+ (1.0,0) [0|252] "" IPB_App1
 SG_ TPBLEDatenFBD_HLIPB_Byte55 : 440|8@1+ (1.0,0) [0|252] "" IPB_App1
 SG_ TPBLEDatenFBD_HLIPB_Byte56 : 448|8@1+ (1.0,0) [0|252] "" IPB_App1
 SG_ TPBLEDatenFBD_HLIPB_Byte57 : 456|8@1+ (1.0,0) [0|252] "" IPB_App1
 SG_ TPBLEDatenFBD_HLIPB_Byte58 : 464|8@1+ (1.0,0) [0|252] "" IPB_App1
 SG_ TPBLEDatenFBD_HLIPB_Byte59 : 472|8@1+ (1.0,0) [0|252] "" IPB_App1
 SG_ TPBLEDatenFBD_HLIPB_Byte60 : 480|8@1+ (1.0,0) [0|252] "" IPB_App1
 SG_ TPBLEDatenFBD_HLIPB_Byte61 : 488|8@1+ (1.0,0) [0|252] "" IPB_App1
 SG_ TPBLEDatenFBD_HLIPB_Byte62 : 496|8@1+ (1.0,0) [0|252] "" IPB_App1
 SG_ TPBLEDatenFBD_HLIPB_Byte63 : 504|8@1+ (1.0,0) [0|252] "" IPB_App1

BO_ 511 TPBLEDaten_FBD_HM_IPB: 64 FBD_HM
 SG_ TPBLEDatenFBD_HMIPB_Byte00 : 0|8@1+ (1.0,0) [0|252] "" IPB_App1
 SG_ TPBLEDatenFBD_HMIPB_Byte01 : 8|8@1+ (1.0,0) [0|252] "" IPB_App1
 SG_ TPBLEDatenFBD_HMIPB_Byte02 : 16|8@1+ (1.0,0) [0|252] "" IPB_App1
 SG_ TPBLEDatenFBD_HMIPB_Byte03 : 24|8@1+ (1.0,0) [0|252] "" IPB_App1
 SG_ TPBLEDatenFBD_HMIPB_Byte04 : 32|8@1+ (1.0,0) [0|252] "" IPB_App1
 SG_ TPBLEDatenFBD_HMIPB_Byte05 : 40|8@1+ (1.0,0) [0|252] "" IPB_App1
 SG_ TPBLEDatenFBD_HMIPB_Byte06 : 48|8@1+ (1.0,0) [0|252] "" IPB_App1
 SG_ TPBLEDatenFBD_HMIPB_Byte07 : 56|8@1+ (1.0,0) [0|252] "" IPB_App1
 SG_ TPBLEDatenFBD_HMIPB_Byte08 : 64|8@1+ (1.0,0) [0|252] "" IPB_App1
 SG_ TPBLEDatenFBD_HMIPB_Byte09 : 72|8@1+ (1.0,0) [0|252] "" IPB_App1
 SG_ TPBLEDatenFBD_HMIPB_Byte10 : 80|8@1+ (1.0,0) [0|252] "" IPB_App1
 SG_ TPBLEDatenFBD_HMIPB_Byte11 : 88|8@1+ (1.0,0) [0|252] "" IPB_App1
 SG_ TPBLEDatenFBD_HMIPB_Byte12 : 96|8@1+ (1.0,0) [0|252] "" IPB_App1
 SG_ TPBLEDatenFBD_HMIPB_Byte13 : 104|8@1+ (1.0,0) [0|252] "" IPB_App1
 SG_ TPBLEDatenFBD_HMIPB_Byte14 : 112|8@1+ (1.0,0) [0|252] "" IPB_App1
 SG_ TPBLEDatenFBD_HMIPB_Byte15 : 120|8@1+ (1.0,0) [0|252] "" IPB_App1
 SG_ TPBLEDatenFBD_HMIPB_Byte16 : 128|8@1+ (1.0,0) [0|252] "" IPB_App1
 SG_ TPBLEDatenFBD_HMIPB_Byte17 : 136|8@1+ (1.0,0) [0|252] "" IPB_App1
 SG_ TPBLEDatenFBD_HMIPB_Byte18 : 144|8@1+ (1.0,0) [0|252] "" IPB_App1
 SG_ TPBLEDatenFBD_HMIPB_Byte19 : 152|8@1+ (1.0,0) [0|252] "" IPB_App1
 SG_ TPBLEDatenFBD_HMIPB_Byte20 : 160|8@1+ (1.0,0) [0|252] "" IPB_App1
 SG_ TPBLEDatenFBD_HMIPB_Byte21 : 168|8@1+ (1.0,0) [0|252] "" IPB_App1
 SG_ TPBLEDatenFBD_HMIPB_Byte22 : 176|8@1+ (1.0,0) [0|252] "" IPB_App1
 SG_ TPBLEDatenFBD_HMIPB_Byte23 : 184|8@1+ (1.0,0) [0|252] "" IPB_App1
 SG_ TPBLEDatenFBD_HMIPB_Byte24 : 192|8@1+ (1.0,0) [0|252] "" IPB_App1
 SG_ TPBLEDatenFBD_HMIPB_Byte25 : 200|8@1+ (1.0,0) [0|252] "" IPB_App1
 SG_ TPBLEDatenFBD_HMIPB_Byte26 : 208|8@1+ (1.0,0) [0|252] "" IPB_App1
 SG_ TPBLEDatenFBD_HMIPB_Byte27 : 216|8@1+ (1.0,0) [0|252] "" IPB_App1
 SG_ TPBLEDatenFBD_HMIPB_Byte28 : 224|8@1+ (1.0,0) [0|252] "" IPB_App1
 SG_ TPBLEDatenFBD_HMIPB_Byte29 : 232|8@1+ (1.0,0) [0|252] "" IPB_App1
 SG_ TPBLEDatenFBD_HMIPB_Byte30 : 240|8@1+ (1.0,0) [0|252] "" IPB_App1
 SG_ TPBLEDatenFBD_HMIPB_Byte31 : 248|8@1+ (1.0,0) [0|252] "" IPB_App1
 SG_ TPBLEDatenFBD_HMIPB_Byte32 : 256|8@1+ (1.0,0) [0|252] "" IPB_App1
 SG_ TPBLEDatenFBD_HMIPB_Byte33 : 264|8@1+ (1.0,0) [0|252] "" IPB_App1
 SG_ TPBLEDatenFBD_HMIPB_Byte34 : 272|8@1+ (1.0,0) [0|252] "" IPB_App1
 SG_ TPBLEDatenFBD_HMIPB_Byte35 : 280|8@1+ (1.0,0) [0|252] "" IPB_App1
 SG_ TPBLEDatenFBD_HMIPB_Byte36 : 288|8@1+ (1.0,0) [0|252] "" IPB_App1
 SG_ TPBLEDatenFBD_HMIPB_Byte37 : 296|8@1+ (1.0,0) [0|252] "" IPB_App1
 SG_ TPBLEDatenFBD_HMIPB_Byte38 : 304|8@1+ (1.0,0) [0|252] "" IPB_App1
 SG_ TPBLEDatenFBD_HMIPB_Byte39 : 312|8@1+ (1.0,0) [0|252] "" IPB_App1
 SG_ TPBLEDatenFBD_HMIPB_Byte40 : 320|8@1+ (1.0,0) [0|252] "" IPB_App1
 SG_ TPBLEDatenFBD_HMIPB_Byte41 : 328|8@1+ (1.0,0) [0|252] "" IPB_App1
 SG_ TPBLEDatenFBD_HMIPB_Byte42 : 336|8@1+ (1.0,0) [0|252] "" IPB_App1
 SG_ TPBLEDatenFBD_HMIPB_Byte43 : 344|8@1+ (1.0,0) [0|252] "" IPB_App1
 SG_ TPBLEDatenFBD_HMIPB_Byte44 : 352|8@1+ (1.0,0) [0|252] "" IPB_App1
 SG_ TPBLEDatenFBD_HMIPB_Byte45 : 360|8@1+ (1.0,0) [0|252] "" IPB_App1
 SG_ TPBLEDatenFBD_HMIPB_Byte46 : 368|8@1+ (1.0,0) [0|252] "" IPB_App1
 SG_ TPBLEDatenFBD_HMIPB_Byte47 : 376|8@1+ (1.0,0) [0|252] "" IPB_App1
 SG_ TPBLEDatenFBD_HMIPB_Byte48 : 384|8@1+ (1.0,0) [0|252] "" IPB_App1
 SG_ TPBLEDatenFBD_HMIPB_Byte49 : 392|8@1+ (1.0,0) [0|252] "" IPB_App1
 SG_ TPBLEDatenFBD_HMIPB_Byte50 : 400|8@1+ (1.0,0) [0|252] "" IPB_App1
 SG_ TPBLEDatenFBD_HMIPB_Byte51 : 408|8@1+ (1.0,0) [0|252] "" IPB_App1
 SG_ TPBLEDatenFBD_HMIPB_Byte52 : 416|8@1+ (1.0,0) [0|252] "" IPB_App1
 SG_ TPBLEDatenFBD_HMIPB_Byte53 : 424|8@1+ (1.0,0) [0|252] "" IPB_App1
 SG_ TPBLEDatenFBD_HMIPB_Byte54 : 432|8@1+ (1.0,0) [0|252] "" IPB_App1
 SG_ TPBLEDatenFBD_HMIPB_Byte55 : 440|8@1+ (1.0,0) [0|252] "" IPB_App1
 SG_ TPBLEDatenFBD_HMIPB_Byte56 : 448|8@1+ (1.0,0) [0|252] "" IPB_App1
 SG_ TPBLEDatenFBD_HMIPB_Byte57 : 456|8@1+ (1.0,0) [0|252] "" IPB_App1
 SG_ TPBLEDatenFBD_HMIPB_Byte58 : 464|8@1+ (1.0,0) [0|252] "" IPB_App1
 SG_ TPBLEDatenFBD_HMIPB_Byte59 : 472|8@1+ (1.0,0) [0|252] "" IPB_App1
 SG_ TPBLEDatenFBD_HMIPB_Byte60 : 480|8@1+ (1.0,0) [0|252] "" IPB_App1
 SG_ TPBLEDatenFBD_HMIPB_Byte61 : 488|8@1+ (1.0,0) [0|252] "" IPB_App1
 SG_ TPBLEDatenFBD_HMIPB_Byte62 : 496|8@1+ (1.0,0) [0|252] "" IPB_App1
 SG_ TPBLEDatenFBD_HMIPB_Byte63 : 504|8@1+ (1.0,0) [0|252] "" IPB_App1

BO_ 517 TPBLEDaten_FBD_HR_IPB: 64 FBD_HR
 SG_ TPBLEDatenFBD_HRIPB_Byte00 : 0|8@1+ (1.0,0) [0|252] "" IPB_App1
 SG_ TPBLEDatenFBD_HRIPB_Byte01 : 8|8@1+ (1.0,0) [0|252] "" IPB_App1
 SG_ TPBLEDatenFBD_HRIPB_Byte02 : 16|8@1+ (1.0,0) [0|252] "" IPB_App1
 SG_ TPBLEDatenFBD_HRIPB_Byte03 : 24|8@1+ (1.0,0) [0|252] "" IPB_App1
 SG_ TPBLEDatenFBD_HRIPB_Byte04 : 32|8@1+ (1.0,0) [0|252] "" IPB_App1
 SG_ TPBLEDatenFBD_HRIPB_Byte05 : 40|8@1+ (1.0,0) [0|252] "" IPB_App1
 SG_ TPBLEDatenFBD_HRIPB_Byte06 : 48|8@1+ (1.0,0) [0|252] "" IPB_App1
 SG_ TPBLEDatenFBD_HRIPB_Byte07 : 56|8@1+ (1.0,0) [0|252] "" IPB_App1
 SG_ TPBLEDatenFBD_HRIPB_Byte08 : 64|8@1+ (1.0,0) [0|252] "" IPB_App1
 SG_ TPBLEDatenFBD_HRIPB_Byte09 : 72|8@1+ (1.0,0) [0|252] "" IPB_App1
 SG_ TPBLEDatenFBD_HRIPB_Byte10 : 80|8@1+ (1.0,0) [0|252] "" IPB_App1
 SG_ TPBLEDatenFBD_HRIPB_Byte11 : 88|8@1+ (1.0,0) [0|252] "" IPB_App1
 SG_ TPBLEDatenFBD_HRIPB_Byte12 : 96|8@1+ (1.0,0) [0|252] "" IPB_App1
 SG_ TPBLEDatenFBD_HRIPB_Byte13 : 104|8@1+ (1.0,0) [0|252] "" IPB_App1
 SG_ TPBLEDatenFBD_HRIPB_Byte14 : 112|8@1+ (1.0,0) [0|252] "" IPB_App1
 SG_ TPBLEDatenFBD_HRIPB_Byte15 : 120|8@1+ (1.0,0) [0|252] "" IPB_App1
 SG_ TPBLEDatenFBD_HRIPB_Byte16 : 128|8@1+ (1.0,0) [0|252] "" IPB_App1
 SG_ TPBLEDatenFBD_HRIPB_Byte17 : 136|8@1+ (1.0,0) [0|252] "" IPB_App1
 SG_ TPBLEDatenFBD_HRIPB_Byte18 : 144|8@1+ (1.0,0) [0|252] "" IPB_App1
 SG_ TPBLEDatenFBD_HRIPB_Byte19 : 152|8@1+ (1.0,0) [0|252] "" IPB_App1
 SG_ TPBLEDatenFBD_HRIPB_Byte20 : 160|8@1+ (1.0,0) [0|252] "" IPB_App1
 SG_ TPBLEDatenFBD_HRIPB_Byte21 : 168|8@1+ (1.0,0) [0|252] "" IPB_App1
 SG_ TPBLEDatenFBD_HRIPB_Byte22 : 176|8@1+ (1.0,0) [0|252] "" IPB_App1
 SG_ TPBLEDatenFBD_HRIPB_Byte23 : 184|8@1+ (1.0,0) [0|252] "" IPB_App1
 SG_ TPBLEDatenFBD_HRIPB_Byte24 : 192|8@1+ (1.0,0) [0|252] "" IPB_App1
 SG_ TPBLEDatenFBD_HRIPB_Byte25 : 200|8@1+ (1.0,0) [0|252] "" IPB_App1
 SG_ TPBLEDatenFBD_HRIPB_Byte26 : 208|8@1+ (1.0,0) [0|252] "" IPB_App1
 SG_ TPBLEDatenFBD_HRIPB_Byte27 : 216|8@1+ (1.0,0) [0|252] "" IPB_App1
 SG_ TPBLEDatenFBD_HRIPB_Byte28 : 224|8@1+ (1.0,0) [0|252] "" IPB_App1
 SG_ TPBLEDatenFBD_HRIPB_Byte29 : 232|8@1+ (1.0,0) [0|252] "" IPB_App1
 SG_ TPBLEDatenFBD_HRIPB_Byte30 : 240|8@1+ (1.0,0) [0|252] "" IPB_App1
 SG_ TPBLEDatenFBD_HRIPB_Byte31 : 248|8@1+ (1.0,0) [0|252] "" IPB_App1
 SG_ TPBLEDatenFBD_HRIPB_Byte32 : 256|8@1+ (1.0,0) [0|252] "" IPB_App1
 SG_ TPBLEDatenFBD_HRIPB_Byte33 : 264|8@1+ (1.0,0) [0|252] "" IPB_App1
 SG_ TPBLEDatenFBD_HRIPB_Byte34 : 272|8@1+ (1.0,0) [0|252] "" IPB_App1
 SG_ TPBLEDatenFBD_HRIPB_Byte35 : 280|8@1+ (1.0,0) [0|252] "" IPB_App1
 SG_ TPBLEDatenFBD_HRIPB_Byte36 : 288|8@1+ (1.0,0) [0|252] "" IPB_App1
 SG_ TPBLEDatenFBD_HRIPB_Byte37 : 296|8@1+ (1.0,0) [0|252] "" IPB_App1
 SG_ TPBLEDatenFBD_HRIPB_Byte38 : 304|8@1+ (1.0,0) [0|252] "" IPB_App1
 SG_ TPBLEDatenFBD_HRIPB_Byte39 : 312|8@1+ (1.0,0) [0|252] "" IPB_App1
 SG_ TPBLEDatenFBD_HRIPB_Byte40 : 320|8@1+ (1.0,0) [0|252] "" IPB_App1
 SG_ TPBLEDatenFBD_HRIPB_Byte41 : 328|8@1+ (1.0,0) [0|252] "" IPB_App1
 SG_ TPBLEDatenFBD_HRIPB_Byte42 : 336|8@1+ (1.0,0) [0|252] "" IPB_App1
 SG_ TPBLEDatenFBD_HRIPB_Byte43 : 344|8@1+ (1.0,0) [0|252] "" IPB_App1
 SG_ TPBLEDatenFBD_HRIPB_Byte44 : 352|8@1+ (1.0,0) [0|252] "" IPB_App1
 SG_ TPBLEDatenFBD_HRIPB_Byte45 : 360|8@1+ (1.0,0) [0|252] "" IPB_App1
 SG_ TPBLEDatenFBD_HRIPB_Byte46 : 368|8@1+ (1.0,0) [0|252] "" IPB_App1
 SG_ TPBLEDatenFBD_HRIPB_Byte47 : 376|8@1+ (1.0,0) [0|252] "" IPB_App1
 SG_ TPBLEDatenFBD_HRIPB_Byte48 : 384|8@1+ (1.0,0) [0|252] "" IPB_App1
 SG_ TPBLEDatenFBD_HRIPB_Byte49 : 392|8@1+ (1.0,0) [0|252] "" IPB_App1
 SG_ TPBLEDatenFBD_HRIPB_Byte50 : 400|8@1+ (1.0,0) [0|252] "" IPB_App1
 SG_ TPBLEDatenFBD_HRIPB_Byte51 : 408|8@1+ (1.0,0) [0|252] "" IPB_App1
 SG_ TPBLEDatenFBD_HRIPB_Byte52 : 416|8@1+ (1.0,0) [0|252] "" IPB_App1
 SG_ TPBLEDatenFBD_HRIPB_Byte53 : 424|8@1+ (1.0,0) [0|252] "" IPB_App1
 SG_ TPBLEDatenFBD_HRIPB_Byte54 : 432|8@1+ (1.0,0) [0|252] "" IPB_App1
 SG_ TPBLEDatenFBD_HRIPB_Byte55 : 440|8@1+ (1.0,0) [0|252] "" IPB_App1
 SG_ TPBLEDatenFBD_HRIPB_Byte56 : 448|8@1+ (1.0,0) [0|252] "" IPB_App1
 SG_ TPBLEDatenFBD_HRIPB_Byte57 : 456|8@1+ (1.0,0) [0|252] "" IPB_App1
 SG_ TPBLEDatenFBD_HRIPB_Byte58 : 464|8@1+ (1.0,0) [0|252] "" IPB_App1
 SG_ TPBLEDatenFBD_HRIPB_Byte59 : 472|8@1+ (1.0,0) [0|252] "" IPB_App1
 SG_ TPBLEDatenFBD_HRIPB_Byte60 : 480|8@1+ (1.0,0) [0|252] "" IPB_App1
 SG_ TPBLEDatenFBD_HRIPB_Byte61 : 488|8@1+ (1.0,0) [0|252] "" IPB_App1
 SG_ TPBLEDatenFBD_HRIPB_Byte62 : 496|8@1+ (1.0,0) [0|252] "" IPB_App1
 SG_ TPBLEDatenFBD_HRIPB_Byte63 : 504|8@1+ (1.0,0) [0|252] "" IPB_App1

BO_ 512 TPBLEDaten_FBD_Miko_IPB: 64 FBD_Miko
 SG_ TPBLEDatenFBD_MikoIPB_Byte00 : 0|8@1+ (1.0,0) [0|252] "" IPB_App1
 SG_ TPBLEDatenFBD_MikoIPB_Byte01 : 8|8@1+ (1.0,0) [0|252] "" IPB_App1
 SG_ TPBLEDatenFBD_MikoIPB_Byte02 : 16|8@1+ (1.0,0) [0|252] "" IPB_App1
 SG_ TPBLEDatenFBD_MikoIPB_Byte03 : 24|8@1+ (1.0,0) [0|252] "" IPB_App1
 SG_ TPBLEDatenFBD_MikoIPB_Byte04 : 32|8@1+ (1.0,0) [0|252] "" IPB_App1
 SG_ TPBLEDatenFBD_MikoIPB_Byte05 : 40|8@1+ (1.0,0) [0|252] "" IPB_App1
 SG_ TPBLEDatenFBD_MikoIPB_Byte06 : 48|8@1+ (1.0,0) [0|252] "" IPB_App1
 SG_ TPBLEDatenFBD_MikoIPB_Byte07 : 56|8@1+ (1.0,0) [0|252] "" IPB_App1
 SG_ TPBLEDatenFBD_MikoIPB_Byte08 : 64|8@1+ (1.0,0) [0|252] "" IPB_App1
 SG_ TPBLEDatenFBD_MikoIPB_Byte09 : 72|8@1+ (1.0,0) [0|252] "" IPB_App1
 SG_ TPBLEDatenFBD_MikoIPB_Byte10 : 80|8@1+ (1.0,0) [0|252] "" IPB_App1
 SG_ TPBLEDatenFBD_MikoIPB_Byte11 : 88|8@1+ (1.0,0) [0|252] "" IPB_App1
 SG_ TPBLEDatenFBD_MikoIPB_Byte12 : 96|8@1+ (1.0,0) [0|252] "" IPB_App1
 SG_ TPBLEDatenFBD_MikoIPB_Byte13 : 104|8@1+ (1.0,0) [0|252] "" IPB_App1
 SG_ TPBLEDatenFBD_MikoIPB_Byte14 : 112|8@1+ (1.0,0) [0|252] "" IPB_App1
 SG_ TPBLEDatenFBD_MikoIPB_Byte15 : 120|8@1+ (1.0,0) [0|252] "" IPB_App1
 SG_ TPBLEDatenFBD_MikoIPB_Byte16 : 128|8@1+ (1.0,0) [0|252] "" IPB_App1
 SG_ TPBLEDatenFBD_MikoIPB_Byte17 : 136|8@1+ (1.0,0) [0|252] "" IPB_App1
 SG_ TPBLEDatenFBD_MikoIPB_Byte18 : 144|8@1+ (1.0,0) [0|252] "" IPB_App1
 SG_ TPBLEDatenFBD_MikoIPB_Byte19 : 152|8@1+ (1.0,0) [0|252] "" IPB_App1
 SG_ TPBLEDatenFBD_MikoIPB_Byte20 : 160|8@1+ (1.0,0) [0|252] "" IPB_App1
 SG_ TPBLEDatenFBD_MikoIPB_Byte21 : 168|8@1+ (1.0,0) [0|252] "" IPB_App1
 SG_ TPBLEDatenFBD_MikoIPB_Byte22 : 176|8@1+ (1.0,0) [0|252] "" IPB_App1
 SG_ TPBLEDatenFBD_MikoIPB_Byte23 : 184|8@1+ (1.0,0) [0|252] "" IPB_App1
 SG_ TPBLEDatenFBD_MikoIPB_Byte24 : 192|8@1+ (1.0,0) [0|252] "" IPB_App1
 SG_ TPBLEDatenFBD_MikoIPB_Byte25 : 200|8@1+ (1.0,0) [0|252] "" IPB_App1
 SG_ TPBLEDatenFBD_MikoIPB_Byte26 : 208|8@1+ (1.0,0) [0|252] "" IPB_App1
 SG_ TPBLEDatenFBD_MikoIPB_Byte27 : 216|8@1+ (1.0,0) [0|252] "" IPB_App1
 SG_ TPBLEDatenFBD_MikoIPB_Byte28 : 224|8@1+ (1.0,0) [0|252] "" IPB_App1
 SG_ TPBLEDatenFBD_MikoIPB_Byte29 : 232|8@1+ (1.0,0) [0|252] "" IPB_App1
 SG_ TPBLEDatenFBD_MikoIPB_Byte30 : 240|8@1+ (1.0,0) [0|252] "" IPB_App1
 SG_ TPBLEDatenFBD_MikoIPB_Byte31 : 248|8@1+ (1.0,0) [0|252] "" IPB_App1
 SG_ TPBLEDatenFBD_MikoIPB_Byte32 : 256|8@1+ (1.0,0) [0|252] "" IPB_App1
 SG_ TPBLEDatenFBD_MikoIPB_Byte33 : 264|8@1+ (1.0,0) [0|252] "" IPB_App1
 SG_ TPBLEDatenFBD_MikoIPB_Byte34 : 272|8@1+ (1.0,0) [0|252] "" IPB_App1
 SG_ TPBLEDatenFBD_MikoIPB_Byte35 : 280|8@1+ (1.0,0) [0|252] "" IPB_App1
 SG_ TPBLEDatenFBD_MikoIPB_Byte36 : 288|8@1+ (1.0,0) [0|252] "" IPB_App1
 SG_ TPBLEDatenFBD_MikoIPB_Byte37 : 296|8@1+ (1.0,0) [0|252] "" IPB_App1
 SG_ TPBLEDatenFBD_MikoIPB_Byte38 : 304|8@1+ (1.0,0) [0|252] "" IPB_App1
 SG_ TPBLEDatenFBD_MikoIPB_Byte39 : 312|8@1+ (1.0,0) [0|252] "" IPB_App1
 SG_ TPBLEDatenFBD_MikoIPB_Byte40 : 320|8@1+ (1.0,0) [0|252] "" IPB_App1
 SG_ TPBLEDatenFBD_MikoIPB_Byte41 : 328|8@1+ (1.0,0) [0|252] "" IPB_App1
 SG_ TPBLEDatenFBD_MikoIPB_Byte42 : 336|8@1+ (1.0,0) [0|252] "" IPB_App1
 SG_ TPBLEDatenFBD_MikoIPB_Byte43 : 344|8@1+ (1.0,0) [0|252] "" IPB_App1
 SG_ TPBLEDatenFBD_MikoIPB_Byte44 : 352|8@1+ (1.0,0) [0|252] "" IPB_App1
 SG_ TPBLEDatenFBD_MikoIPB_Byte45 : 360|8@1+ (1.0,0) [0|252] "" IPB_App1
 SG_ TPBLEDatenFBD_MikoIPB_Byte46 : 368|8@1+ (1.0,0) [0|252] "" IPB_App1
 SG_ TPBLEDatenFBD_MikoIPB_Byte47 : 376|8@1+ (1.0,0) [0|252] "" IPB_App1
 SG_ TPBLEDatenFBD_MikoIPB_Byte48 : 384|8@1+ (1.0,0) [0|252] "" IPB_App1
 SG_ TPBLEDatenFBD_MikoIPB_Byte49 : 392|8@1+ (1.0,0) [0|252] "" IPB_App1
 SG_ TPBLEDatenFBD_MikoIPB_Byte50 : 400|8@1+ (1.0,0) [0|252] "" IPB_App1
 SG_ TPBLEDatenFBD_MikoIPB_Byte51 : 408|8@1+ (1.0,0) [0|252] "" IPB_App1
 SG_ TPBLEDatenFBD_MikoIPB_Byte52 : 416|8@1+ (1.0,0) [0|252] "" IPB_App1
 SG_ TPBLEDatenFBD_MikoIPB_Byte53 : 424|8@1+ (1.0,0) [0|252] "" IPB_App1
 SG_ TPBLEDatenFBD_MikoIPB_Byte54 : 432|8@1+ (1.0,0) [0|252] "" IPB_App1
 SG_ TPBLEDatenFBD_MikoIPB_Byte55 : 440|8@1+ (1.0,0) [0|252] "" IPB_App1
 SG_ TPBLEDatenFBD_MikoIPB_Byte56 : 448|8@1+ (1.0,0) [0|252] "" IPB_App1
 SG_ TPBLEDatenFBD_MikoIPB_Byte57 : 456|8@1+ (1.0,0) [0|252] "" IPB_App1
 SG_ TPBLEDatenFBD_MikoIPB_Byte58 : 464|8@1+ (1.0,0) [0|252] "" IPB_App1
 SG_ TPBLEDatenFBD_MikoIPB_Byte59 : 472|8@1+ (1.0,0) [0|252] "" IPB_App1
 SG_ TPBLEDatenFBD_MikoIPB_Byte60 : 480|8@1+ (1.0,0) [0|252] "" IPB_App1
 SG_ TPBLEDatenFBD_MikoIPB_Byte61 : 488|8@1+ (1.0,0) [0|252] "" IPB_App1
 SG_ TPBLEDatenFBD_MikoIPB_Byte62 : 496|8@1+ (1.0,0) [0|252] "" IPB_App1
 SG_ TPBLEDatenFBD_MikoIPB_Byte63 : 504|8@1+ (1.0,0) [0|252] "" IPB_App1

BO_ 521 TPBLEDaten_FBD_MM_IPB: 64 FBD_MM
 SG_ TPBLEDatenFBD_MMIPB_Byte00 : 0|8@1+ (1.0,0) [0|255] "" IPB_App1
 SG_ TPBLEDatenFBD_MMIPB_Byte01 : 8|8@1+ (1.0,0) [0|255] "" IPB_App1
 SG_ TPBLEDatenFBD_MMIPB_Byte02 : 16|8@1+ (1.0,0) [0|255] "" IPB_App1
 SG_ TPBLEDatenFBD_MMIPB_Byte03 : 24|8@1+ (1.0,0) [0|255] "" IPB_App1
 SG_ TPBLEDatenFBD_MMIPB_Byte04 : 32|8@1+ (1.0,0) [0|255] "" IPB_App1
 SG_ TPBLEDatenFBD_MMIPB_Byte05 : 40|8@1+ (1.0,0) [0|255] "" IPB_App1
 SG_ TPBLEDatenFBD_MMIPB_Byte06 : 48|8@1+ (1.0,0) [0|255] "" IPB_App1
 SG_ TPBLEDatenFBD_MMIPB_Byte07 : 56|8@1+ (1.0,0) [0|255] "" IPB_App1
 SG_ TPBLEDatenFBD_MMIPB_Byte08 : 64|8@1+ (1.0,0) [0|255] "" IPB_App1
 SG_ TPBLEDatenFBD_MMIPB_Byte09 : 72|8@1+ (1.0,0) [0|255] "" IPB_App1
 SG_ TPBLEDatenFBD_MMIPB_Byte10 : 80|8@1+ (1.0,0) [0|255] "" IPB_App1
 SG_ TPBLEDatenFBD_MMIPB_Byte11 : 88|8@1+ (1.0,0) [0|255] "" IPB_App1
 SG_ TPBLEDatenFBD_MMIPB_Byte12 : 96|8@1+ (1.0,0) [0|255] "" IPB_App1
 SG_ TPBLEDatenFBD_MMIPB_Byte13 : 104|8@1+ (1.0,0) [0|255] "" IPB_App1
 SG_ TPBLEDatenFBD_MMIPB_Byte14 : 112|8@1+ (1.0,0) [0|255] "" IPB_App1
 SG_ TPBLEDatenFBD_MMIPB_Byte15 : 120|8@1+ (1.0,0) [0|255] "" IPB_App1
 SG_ TPBLEDatenFBD_MMIPB_Byte16 : 128|8@1+ (1.0,0) [0|255] "" IPB_App1
 SG_ TPBLEDatenFBD_MMIPB_Byte17 : 136|8@1+ (1.0,0) [0|255] "" IPB_App1
 SG_ TPBLEDatenFBD_MMIPB_Byte18 : 144|8@1+ (1.0,0) [0|255] "" IPB_App1
 SG_ TPBLEDatenFBD_MMIPB_Byte19 : 152|8@1+ (1.0,0) [0|255] "" IPB_App1
 SG_ TPBLEDatenFBD_MMIPB_Byte20 : 160|8@1+ (1.0,0) [0|255] "" IPB_App1
 SG_ TPBLEDatenFBD_MMIPB_Byte21 : 168|8@1+ (1.0,0) [0|255] "" IPB_App1
 SG_ TPBLEDatenFBD_MMIPB_Byte22 : 176|8@1+ (1.0,0) [0|255] "" IPB_App1
 SG_ TPBLEDatenFBD_MMIPB_Byte23 : 184|8@1+ (1.0,0) [0|255] "" IPB_App1
 SG_ TPBLEDatenFBD_MMIPB_Byte24 : 192|8@1+ (1.0,0) [0|255] "" IPB_App1
 SG_ TPBLEDatenFBD_MMIPB_Byte25 : 200|8@1+ (1.0,0) [0|255] "" IPB_App1
 SG_ TPBLEDatenFBD_MMIPB_Byte26 : 208|8@1+ (1.0,0) [0|255] "" IPB_App1
 SG_ TPBLEDatenFBD_MMIPB_Byte27 : 216|8@1+ (1.0,0) [0|255] "" IPB_App1
 SG_ TPBLEDatenFBD_MMIPB_Byte28 : 224|8@1+ (1.0,0) [0|255] "" IPB_App1
 SG_ TPBLEDatenFBD_MMIPB_Byte29 : 232|8@1+ (1.0,0) [0|255] "" IPB_App1
 SG_ TPBLEDatenFBD_MMIPB_Byte30 : 240|8@1+ (1.0,0) [0|255] "" IPB_App1
 SG_ TPBLEDatenFBD_MMIPB_Byte31 : 248|8@1+ (1.0,0) [0|255] "" IPB_App1
 SG_ TPBLEDatenFBD_MMIPB_Byte32 : 256|8@1+ (1.0,0) [0|255] "" IPB_App1
 SG_ TPBLEDatenFBD_MMIPB_Byte33 : 264|8@1+ (1.0,0) [0|255] "" IPB_App1
 SG_ TPBLEDatenFBD_MMIPB_Byte34 : 272|8@1+ (1.0,0) [0|255] "" IPB_App1
 SG_ TPBLEDatenFBD_MMIPB_Byte35 : 280|8@1+ (1.0,0) [0|255] "" IPB_App1
 SG_ TPBLEDatenFBD_MMIPB_Byte36 : 288|8@1+ (1.0,0) [0|255] "" IPB_App1
 SG_ TPBLEDatenFBD_MMIPB_Byte37 : 296|8@1+ (1.0,0) [0|255] "" IPB_App1
 SG_ TPBLEDatenFBD_MMIPB_Byte38 : 304|8@1+ (1.0,0) [0|255] "" IPB_App1
 SG_ TPBLEDatenFBD_MMIPB_Byte39 : 312|8@1+ (1.0,0) [0|255] "" IPB_App1
 SG_ TPBLEDatenFBD_MMIPB_Byte40 : 320|8@1+ (1.0,0) [0|255] "" IPB_App1
 SG_ TPBLEDatenFBD_MMIPB_Byte41 : 328|8@1+ (1.0,0) [0|255] "" IPB_App1
 SG_ TPBLEDatenFBD_MMIPB_Byte42 : 336|8@1+ (1.0,0) [0|255] "" IPB_App1
 SG_ TPBLEDatenFBD_MMIPB_Byte43 : 344|8@1+ (1.0,0) [0|255] "" IPB_App1
 SG_ TPBLEDatenFBD_MMIPB_Byte44 : 352|8@1+ (1.0,0) [0|255] "" IPB_App1
 SG_ TPBLEDatenFBD_MMIPB_Byte45 : 360|8@1+ (1.0,0) [0|255] "" IPB_App1
 SG_ TPBLEDatenFBD_MMIPB_Byte46 : 368|8@1+ (1.0,0) [0|255] "" IPB_App1
 SG_ TPBLEDatenFBD_MMIPB_Byte47 : 376|8@1+ (1.0,0) [0|255] "" IPB_App1
 SG_ TPBLEDatenFBD_MMIPB_Byte48 : 384|8@1+ (1.0,0) [0|255] "" IPB_App1
 SG_ TPBLEDatenFBD_MMIPB_Byte49 : 392|8@1+ (1.0,0) [0|255] "" IPB_App1
 SG_ TPBLEDatenFBD_MMIPB_Byte50 : 400|8@1+ (1.0,0) [0|255] "" IPB_App1
 SG_ TPBLEDatenFBD_MMIPB_Byte51 : 408|8@1+ (1.0,0) [0|255] "" IPB_App1
 SG_ TPBLEDatenFBD_MMIPB_Byte52 : 416|8@1+ (1.0,0) [0|255] "" IPB_App1
 SG_ TPBLEDatenFBD_MMIPB_Byte53 : 424|8@1+ (1.0,0) [0|255] "" IPB_App1
 SG_ TPBLEDatenFBD_MMIPB_Byte54 : 432|8@1+ (1.0,0) [0|255] "" IPB_App1
 SG_ TPBLEDatenFBD_MMIPB_Byte55 : 440|8@1+ (1.0,0) [0|255] "" IPB_App1
 SG_ TPBLEDatenFBD_MMIPB_Byte56 : 448|8@1+ (1.0,0) [0|255] "" IPB_App1
 SG_ TPBLEDatenFBD_MMIPB_Byte57 : 456|8@1+ (1.0,0) [0|255] "" IPB_App1
 SG_ TPBLEDatenFBD_MMIPB_Byte58 : 464|8@1+ (1.0,0) [0|255] "" IPB_App1
 SG_ TPBLEDatenFBD_MMIPB_Byte59 : 472|8@1+ (1.0,0) [0|255] "" IPB_App1
 SG_ TPBLEDatenFBD_MMIPB_Byte60 : 480|8@1+ (1.0,0) [0|255] "" IPB_App1
 SG_ TPBLEDatenFBD_MMIPB_Byte61 : 488|8@1+ (1.0,0) [0|255] "" IPB_App1
 SG_ TPBLEDatenFBD_MMIPB_Byte62 : 496|8@1+ (1.0,0) [0|255] "" IPB_App1
 SG_ TPBLEDatenFBD_MMIPB_Byte63 : 504|8@1+ (1.0,0) [0|255] "" IPB_App1

CM_ SG_ 435 StatusUWBRangingFBD_VR_SessionID "contains Session-ID";
CM_ SG_ 435 StatusUWBRangingFBD_VR_TimeOfFli "ranging result in ps (PH) = (DEC) * 15.65";
CM_ SG_ 435 StatusUWBRangingFBD_VR_RangingBl "contains Frame Index";
CM_ SG_ 435 StatusUWBRangingFBD_VR_RangingRo "contains Hopping Offset";
CM_ SG_ 435 StatusUWBRangingFBD_VR_OverallRe "overall receive power (Range: -127 ... -1 dB / step: 0.5dB)";
CM_ SG_ 435 StatusUWBRangingFBD_VR_FirstPath "first path power (Range: -127 ... -1 dB / step: 0.5dB)";
CM_ SG_ 435 StatusUWBRangingFBD_VR_AngleOfAr "first path AoA";
CM_ SG_ 435 StatusUWBRangingFBD_VR_PhaseDiff "indicates first path Phase Difference of Arrival (PDoA)";
CM_ SG_ 435 StatusUWBRangingFBD_VR_Strongest "strongest path power (Range: -127 ... -1 dB / step: 0.5dB)";
CM_ SG_ 435 StatusUWBRangingFBD_VR_BLE_RSSI "indicates strongest path based on BLE received signal strength indicator";
CM_ SG_ 435 StatusUWBRangingFBD_VR_Stronge_2 "strongest path offset (Range: 0 ... 125ns / step: 0.5ns)";
CM_ SG_ 435 StatusUWBRangingFBD_VR_PDoA_SNR "indicates minimum SNR of the two Rx paths of an FBD indicated at every ranging round";
CM_ SG_ 435 StatusUWBRangingFBD_VR_DutyCycle "indicates duty cycle limit (%), the actual percentage value of frames in relation to the maximum value of 26 frames per second";
CM_ SG_ 435 StatusUWBRangingFBD_VR_FinalData "indicates whether the Final Data is calculated over CAN-FD or received via RF UWB 0 = final data via RF UWB; 1 = final data over CAN-FD; F = no final data";
CM_ SG_ 435 StatusUWBRangingFBD_VR_Antenna "indicates Antenna information (which rx chain is used)";
CM_ SG_ 435 StatusUWBRangingFBD_VR_Status1 "PowerMode and debug information byte1 ToF: time off light FDD: Final data distribution";
CM_ SG_ 435 StatusUWBRangingFBD_VR_Status2 "PowerMode and debug information byte2";
CM_ SG_ 435 StatusUWBRangingFBD_VR_Status3 "PowerMode and debug information byte3";
CM_ SG_ 435 StatusUWBRangingFBD_VR_Status4 "NoisePower and debug information byte4 If Status2=0x00 and Status3=0x0F: Value in Status4 is NoisePower (manual calculation of NoisePower: (value)*0.5-127 [dB]";
CM_ SG_ 435 StatusUWBRangingFBD_VR_IV00 "contains IV";
CM_ SG_ 435 StatusUWBRangingFBD_VR_IV01 "contains IV";
CM_ SG_ 435 StatusUWBRangingFBD_VR_IV02 "contains IV";
CM_ SG_ 435 StatusUWBRangingFBD_VR_IV03 "contains IV";
CM_ SG_ 435 StatusUWBRangingFBD_VR_Sign00 "contains signing to ranging result";
CM_ SG_ 435 StatusUWBRangingFBD_VR_Sign01 "contains signing to ranging result";
CM_ SG_ 435 StatusUWBRangingFBD_VR_Sign02 "contains signing to ranging result";
CM_ SG_ 435 StatusUWBRangingFBD_VR_Sign03 "contains signing to ranging result";
CM_ SG_ 435 StatusUWBRangingFBD_VR_Sign04 "contains signing to ranging result";
CM_ SG_ 435 StatusUWBRangingFBD_VR_Sign05 "contains signing to ranging result";
CM_ SG_ 435 StatusUWBRangingFBD_VR_Sign06 "contains signing to ranging result";
CM_ SG_ 435 StatusUWBRangingFBD_VR_Sign07 "contains signing to ranging result";
CM_ SG_ 456 StatusUWBRangingFDD1FBD_HL_Sessi "contains Session-ID";
CM_ SG_ 456 StatusUWBRangingFDD1FBD_HL_UWBSe "contains UWB Session-ID";
CM_ SG_ 456 StatusUWBRangingFDD1FBD_HL_Rangi "contains Ranging Block";
CM_ SG_ 456 StatusUWBRangingFDD1FBD_HL_Hoppi "contians Hopping Flag";
CM_ SG_ 456 StatusUWBRangingFDD1FBD_HL_Round "contains Round Index";
CM_ SG_ 456 StatusUWBRangingFDD1FBD_HL_Final "contains Final STSIndex";
CM_ SG_ 456 StatusUWBRangingFDD1FBD_HL_Fin_2 "contains Final Time Stamp";
CM_ SG_ 456 StatusUWBRangingFDD1FBD_HL_Numbe "contains Number Responder";
CM_ SG_ 456 StatusUWBRangingFDD1FBD_HL_Index "contains Index Responder 1";
CM_ SG_ 456 StatusUWBRangingFDD1FBD_HL_TimeS "contains Time Stamp Responder 1";
CM_ SG_ 456 StatusUWBRangingFDD1FBD_HL_Tim_2 "contains Time Stamp Uncertainty Responder 1";
CM_ SG_ 456 StatusUWBRangingFDD1FBD_HL_Statu "contains Status Responder 1";
CM_ SG_ 456 StatusUWBRangingFDD1FBD_HL_Ind_2 "contains Index Responder 2";
CM_ SG_ 456 StatusUWBRangingFDD1FBD_HL_Tim_3 "contains Time Stamp Responder 2";
CM_ SG_ 456 StatusUWBRangingFDD1FBD_HL_Tim_4 "contains Time Stamp Uncertainty Responder 2";
CM_ SG_ 456 StatusUWBRangingFDD1FBD_HL_Sta_2 "contains Status Responder 2";
CM_ SG_ 456 StatusUWBRangingFDD1FBD_HL_Ind_3 "contains Index Responder 3";
CM_ SG_ 456 StatusUWBRangingFDD1FBD_HL_Tim_5 "contains Time Stamp Responder 3";
CM_ SG_ 456 StatusUWBRangingFDD1FBD_HL_Tim_6 "contains Time Stamp Uncertainty Responder 3";
CM_ SG_ 456 StatusUWBRangingFDD1FBD_HL_Sta_3 "contains Status Responder 3";
CM_ SG_ 456 StatusUWBRangingFDD1FBD_HL_Ind_4 "contains Index Responder 4";
CM_ SG_ 456 StatusUWBRangingFDD1FBD_HL_Tim_7 "contains Time Stamp Responder 4";
CM_ SG_ 456 StatusUWBRangingFDD1FBD_HL_Tim_8 "contains Time Stamp Uncertainty Responder 4";
CM_ SG_ 456 StatusUWBRangingFDD1FBD_HL_Sta_4 "contains Status Responder 4";
CM_ SG_ 456 StatusUWBRangingFDD1FBD_HL_Ind_5 "contains Index Responder 5";
CM_ SG_ 456 StatusUWBRangingFDD1FBD_HL_Tim_9 "contians Time Stamp Responder 5";
CM_ SG_ 456 StatusUWBRangingFDD1FBD_HL_Ti_10 "contains Time Stamp Uncertainty Responder 5";
CM_ SG_ 456 StatusUWBRangingFDD1FBD_HL_Sta_5 "contains Status Responder 5";
CM_ SG_ 456 StatusUWBRangingFDD1FBD_HL_Ind_6 "contains Index Responder 6";
CM_ SG_ 456 StatusUWBRangingFDD1FBD_HL_Ti_11 "contains Time Stamp Responder 6";
CM_ SG_ 456 StatusUWBRangingFDD1FBD_HL_Ti_12 "contains Time Stamp Uncertainty Responder 6";
CM_ SG_ 456 StatusUWBRangingFDD1FBD_HL_Sta_6 "contains Status Responder 6";
CM_ SG_ 456 StatusUWBRangingFDD1FBD_HL_IV0 "contains initialisation vector byte0";
CM_ SG_ 456 StatusUWBRangingFDD1FBD_HL_IV1 "contains initialisation vector byte1";
CM_ SG_ 451 StatusUWBRangingFDD1FBD_HM_Sessi "contains Session-ID";
CM_ SG_ 451 StatusUWBRangingFDD1FBD_HM_UWBSe "contains UWB Session-ID";
CM_ SG_ 451 StatusUWBRangingFDD1FBD_HM_Rangi "contains Ranging Block";
CM_ SG_ 451 StatusUWBRangingFDD1FBD_HM_Hoppi "contians Hopping Flag";
CM_ SG_ 451 StatusUWBRangingFDD1FBD_HM_Round "contains Round Index";
CM_ SG_ 451 StatusUWBRangingFDD1FBD_HM_Final "contains Final STSIndex";
CM_ SG_ 451 StatusUWBRangingFDD1FBD_HM_Fin_2 "contains Final Time Stamp";
CM_ SG_ 451 StatusUWBRangingFDD1FBD_HM_Numbe "contains Number Responder";
CM_ SG_ 451 StatusUWBRangingFDD1FBD_HM_Index "contains Index Responder 1";
CM_ SG_ 451 StatusUWBRangingFDD1FBD_HM_TimeS "contains Time Stamp Responder 1";
CM_ SG_ 451 StatusUWBRangingFDD1FBD_HM_Tim_2 "contains Time Stamp Uncertainty Responder 1";
CM_ SG_ 451 StatusUWBRangingFDD1FBD_HM_Statu "contains Status Responder 1";
CM_ SG_ 451 StatusUWBRangingFDD1FBD_HM_Ind_2 "contains Index Responder 2";
CM_ SG_ 451 StatusUWBRangingFDD1FBD_HM_Tim_3 "contains Time Stamp Responder 2";
CM_ SG_ 451 StatusUWBRangingFDD1FBD_HM_Tim_4 "contains Time Stamp Uncertainty Responder 2";
CM_ SG_ 451 StatusUWBRangingFDD1FBD_HM_Sta_2 "contains Status Responder 2";
CM_ SG_ 451 StatusUWBRangingFDD1FBD_HM_Ind_3 "contains Index Responder 3";
CM_ SG_ 451 StatusUWBRangingFDD1FBD_HM_Tim_5 "contains Time Stamp Responder 3";
CM_ SG_ 451 StatusUWBRangingFDD1FBD_HM_Tim_6 "contains Time Stamp Uncertainty Responder 3";
CM_ SG_ 451 StatusUWBRangingFDD1FBD_HM_Sta_3 "contains Status Responder 3";
CM_ SG_ 451 StatusUWBRangingFDD1FBD_HM_Ind_4 "contains Index Responder 4";
CM_ SG_ 451 StatusUWBRangingFDD1FBD_HM_Tim_7 "contains Time Stamp Responder 4";
CM_ SG_ 451 StatusUWBRangingFDD1FBD_HM_Tim_8 "contains Time Stamp Uncertainty Responder 4";
CM_ SG_ 451 StatusUWBRangingFDD1FBD_HM_Sta_4 "contains Status Responder 4";
CM_ SG_ 451 StatusUWBRangingFDD1FBD_HM_Ind_5 "contains Index Responder 5";
CM_ SG_ 451 StatusUWBRangingFDD1FBD_HM_Tim_9 "contians Time Stamp Responder 5";
CM_ SG_ 451 StatusUWBRangingFDD1FBD_HM_Ti_10 "contains Time Stamp Uncertainty Responder 5";
CM_ SG_ 451 StatusUWBRangingFDD1FBD_HM_Sta_5 "contains Status Responder 5";
CM_ SG_ 451 StatusUWBRangingFDD1FBD_HM_Ind_6 "contains Index Responder 6";
CM_ SG_ 451 StatusUWBRangingFDD1FBD_HM_Ti_11 "contains Time Stamp Responder 6";
CM_ SG_ 451 StatusUWBRangingFDD1FBD_HM_Ti_12 "contains Time Stamp Uncertainty Responder 6";
CM_ SG_ 451 StatusUWBRangingFDD1FBD_HM_Sta_6 "contains Status Responder 6";
CM_ SG_ 451 StatusUWBRangingFDD1FBD_HM_IV0 "contains initialisation vector byte0";
CM_ SG_ 451 StatusUWBRangingFDD1FBD_HM_IV1 "contains initialisation vector byte1";
CM_ SG_ 457 StatusUWBRangingFDD1FBD_HR_Sessi "contains Session-ID";
CM_ SG_ 457 StatusUWBRangingFDD1FBD_HR_UWBSe "contains UWB Session-ID";
CM_ SG_ 457 StatusUWBRangingFDD1FBD_HR_Rangi "contains Ranging Block";
CM_ SG_ 457 StatusUWBRangingFDD1FBD_HR_Hoppi "contians Hopping Flag";
CM_ SG_ 457 StatusUWBRangingFDD1FBD_HR_Round "contains Round Index";
CM_ SG_ 457 StatusUWBRangingFDD1FBD_HR_Final "contains Final STSIndex";
CM_ SG_ 457 StatusUWBRangingFDD1FBD_HR_Fin_2 "contains Final Time Stamp";
CM_ SG_ 457 StatusUWBRangingFDD1FBD_HR_Numbe "contains Number Responder";
CM_ SG_ 457 StatusUWBRangingFDD1FBD_HR_Index "contains Index Responder 1";
CM_ SG_ 457 StatusUWBRangingFDD1FBD_HR_TimeS "contains Time Stamp Responder 1";
CM_ SG_ 457 StatusUWBRangingFDD1FBD_HR_Tim_2 "contains Time Stamp Uncertainty Responder 1";
CM_ SG_ 457 StatusUWBRangingFDD1FBD_HR_Statu "contains Status Responder 1";
CM_ SG_ 457 StatusUWBRangingFDD1FBD_HR_Ind_2 "contains Index Responder 2";
CM_ SG_ 457 StatusUWBRangingFDD1FBD_HR_Tim_3 "contains Time Stamp Responder 2";
CM_ SG_ 457 StatusUWBRangingFDD1FBD_HR_Tim_4 "contains Time Stamp Uncertainty Responder 2";
CM_ SG_ 457 StatusUWBRangingFDD1FBD_HR_Sta_2 "contains Status Responder 2";
CM_ SG_ 457 StatusUWBRangingFDD1FBD_HR_Ind_3 "contains Index Responder 3";
CM_ SG_ 457 StatusUWBRangingFDD1FBD_HR_Tim_5 "contains Time Stamp Responder 3";
CM_ SG_ 457 StatusUWBRangingFDD1FBD_HR_Tim_6 "contains Time Stamp Uncertainty Responder 3";
CM_ SG_ 457 StatusUWBRangingFDD1FBD_HR_Sta_3 "contains Status Responder 3";
CM_ SG_ 457 StatusUWBRangingFDD1FBD_HR_Ind_4 "contains Index Responder 4";
CM_ SG_ 457 StatusUWBRangingFDD1FBD_HR_Tim_7 "contains Time Stamp Responder 4";
CM_ SG_ 457 StatusUWBRangingFDD1FBD_HR_Tim_8 "contains Time Stamp Uncertainty Responder 4";
CM_ SG_ 457 StatusUWBRangingFDD1FBD_HR_Sta_4 "contains Status Responder 4";
CM_ SG_ 457 StatusUWBRangingFDD1FBD_HR_Ind_5 "contains Index Responder 5";
CM_ SG_ 457 StatusUWBRangingFDD1FBD_HR_Tim_9 "contians Time Stamp Responder 5";
CM_ SG_ 457 StatusUWBRangingFDD1FBD_HR_Ti_10 "contains Time Stamp Uncertainty Responder 5";
CM_ SG_ 457 StatusUWBRangingFDD1FBD_HR_Sta_5 "contains Status Responder 5";
CM_ SG_ 457 StatusUWBRangingFDD1FBD_HR_Ind_6 "contains Index Responder 6";
CM_ SG_ 457 StatusUWBRangingFDD1FBD_HR_Ti_11 "contains Time Stamp Responder 6";
CM_ SG_ 457 StatusUWBRangingFDD1FBD_HR_Ti_12 "contains Time Stamp Uncertainty Responder 6";
CM_ SG_ 457 StatusUWBRangingFDD1FBD_HR_Sta_6 "contains Status Responder 6";
CM_ SG_ 457 StatusUWBRangingFDD1FBD_HR_IV0 "contains initialisation vector byte0";
CM_ SG_ 457 StatusUWBRangingFDD1FBD_HR_IV1 "contains initialisation vector byte1";
CM_ SG_ 452 StatusUWBRangingFDD1FBD_Miko_Ses "contains Session-ID";
CM_ SG_ 452 StatusUWBRangingFDD1FBD_Miko_UWB "contains UWB Session-ID";
CM_ SG_ 452 StatusUWBRangingFDD1FBD_Miko_Ran "contains Ranging Block";
CM_ SG_ 452 StatusUWBRangingFDD1FBD_Miko_Hop "contians Hopping Flag";
CM_ SG_ 452 StatusUWBRangingFDD1FBD_Miko_Rou "contains Round Index";
CM_ SG_ 452 StatusUWBRangingFDD1FBD_Miko_Fin "contains Final STSIndex";
CM_ SG_ 452 StatusUWBRangingFDD1FBD_Miko_F_2 "contains Final Time Stamp";
CM_ SG_ 452 StatusUWBRangingFDD1FBD_Miko_Num "contains Number Responder";
CM_ SG_ 452 StatusUWBRangingFDD1FBD_Miko_Ind "contains Index Responder 1";
CM_ SG_ 452 StatusUWBRangingFDD1FBD_Miko_Tim "contains Time Stamp Responder 1";
CM_ SG_ 452 StatusUWBRangingFDD1FBD_Miko_T_2 "contains Time Stamp Uncertainty Responder 1";
CM_ SG_ 452 StatusUWBRangingFDD1FBD_Miko_Sta "contains Status Responder 1";
CM_ SG_ 452 StatusUWBRangingFDD1FBD_Miko_I_2 "contains Index Responder 2";
CM_ SG_ 452 StatusUWBRangingFDD1FBD_Miko_T_3 "contains Time Stamp Responder 2";
CM_ SG_ 452 StatusUWBRangingFDD1FBD_Miko_T_4 "contains Time Stamp Uncertainty Responder 2";
CM_ SG_ 452 StatusUWBRangingFDD1FBD_Miko_S_2 "contains Status Responder 2";
CM_ SG_ 452 StatusUWBRangingFDD1FBD_Miko_I_3 "contains Index Responder 3";
CM_ SG_ 452 StatusUWBRangingFDD1FBD_Miko_T_5 "contains Time Stamp Responder 3";
CM_ SG_ 452 StatusUWBRangingFDD1FBD_Miko_T_6 "contains Time Stamp Uncertainty Responder 3";
CM_ SG_ 452 StatusUWBRangingFDD1FBD_Miko_S_3 "contains Status Responder 3";
CM_ SG_ 452 StatusUWBRangingFDD1FBD_Miko_I_4 "contains Index Responder 4";
CM_ SG_ 452 StatusUWBRangingFDD1FBD_Miko_T_7 "contains Time Stamp Responder 4";
CM_ SG_ 452 StatusUWBRangingFDD1FBD_Miko_T_8 "contains Time Stamp Uncertainty Responder 4";
CM_ SG_ 452 StatusUWBRangingFDD1FBD_Miko_S_4 "contains Status Responder 4";
CM_ SG_ 452 StatusUWBRangingFDD1FBD_Miko_I_5 "contains Index Responder 5";
CM_ SG_ 452 StatusUWBRangingFDD1FBD_Miko_T_9 "contians Time Stamp Responder 5";
CM_ SG_ 452 StatusUWBRangingFDD1FBD_Miko__10 "contains Time Stamp Uncertainty Responder 5";
CM_ SG_ 452 StatusUWBRangingFDD1FBD_Miko_S_5 "contains Status Responder 5";
CM_ SG_ 452 StatusUWBRangingFDD1FBD_Miko_I_6 "contains Index Responder 6";
CM_ SG_ 452 StatusUWBRangingFDD1FBD_Miko__11 "contains Time Stamp Responder 6";
CM_ SG_ 452 StatusUWBRangingFDD1FBD_Miko__12 "contains Time Stamp Uncertainty Responder 6";
CM_ SG_ 452 StatusUWBRangingFDD1FBD_Miko_S_6 "contains Status Responder 6";
CM_ SG_ 452 StatusUWBRangingFDD1FBD_Miko_IV0 "contains initialisation vector byte0";
CM_ SG_ 452 StatusUWBRangingFDD1FBD_Miko_IV1 "contains initialisation vector byte1";
CM_ SG_ 444 StatusUWBRangingFDD1FBD_MM_Sessi "contains Session-ID short";
CM_ SG_ 444 StatusUWBRangingFDD1FBD_MM_UWBSe "contains UWB Session-ID";
CM_ SG_ 444 StatusUWBRangingFDD1FBD_MM_Rangi "contains Raning Block";
CM_ SG_ 444 StatusUWBRangingFDD1FBD_MM_Hoppi "contians Hopping Flag";
CM_ SG_ 444 StatusUWBRangingFDD1FBD_MM_Round "contains Round Index";
CM_ SG_ 444 StatusUWBRangingFDD1FBD_MM_Final "contains Final STSIndex";
CM_ SG_ 444 StatusUWBRangingFDD1FBD_MM_Fin_2 "contains Final Time Stamp";
CM_ SG_ 444 StatusUWBRangingFDD1FBD_MM_Numbe "contains Number Responder";
CM_ SG_ 444 StatusUWBRangingFDD1FBD_MM_Index "contains Index Responder 1";
CM_ SG_ 444 StatusUWBRangingFDD1FBD_MM_TimeS "contains Time Stamp Responder 1";
CM_ SG_ 444 StatusUWBRangingFDD1FBD_MM_Tim_2 "contains Time Stamp Uncertainty Responder 1";
CM_ SG_ 444 StatusUWBRangingFDD1FBD_MM_Statu "contains Status Responder 1";
CM_ SG_ 444 StatusUWBRangingFDD1FBD_MM_Ind_2 "contains Index Responder 2";
CM_ SG_ 444 StatusUWBRangingFDD1FBD_MM_Tim_3 "contains Time Stamp Responder 2";
CM_ SG_ 444 StatusUWBRangingFDD1FBD_MM_Tim_4 "contains Time Stamp Uncertainty Responder 2";
CM_ SG_ 444 StatusUWBRangingFDD1FBD_MM_Sta_2 "contains Status Responder 2";
CM_ SG_ 444 StatusUWBRangingFDD1FBD_MM_Ind_3 "contains Index Responder 3";
CM_ SG_ 444 StatusUWBRangingFDD1FBD_MM_Tim_5 "contains Time Stamp Responder 3";
CM_ SG_ 444 StatusUWBRangingFDD1FBD_MM_Tim_6 "contains Time Stamp Uncertainty Responder 3";
CM_ SG_ 444 StatusUWBRangingFDD1FBD_MM_Sta_3 "contains Status Responder 3";
CM_ SG_ 444 StatusUWBRangingFDD1FBD_MM_Ind_4 "contains Index Responder 4";
CM_ SG_ 444 StatusUWBRangingFDD1FBD_MM_Tim_7 "contains Time Stamp Responder 4";
CM_ SG_ 444 StatusUWBRangingFDD1FBD_MM_Tim_8 "contains Time Stamp Uncertainty Responder 4";
CM_ SG_ 444 StatusUWBRangingFDD1FBD_MM_Sta_4 "contains Status Responder 4";
CM_ SG_ 444 StatusUWBRangingFDD1FBD_MM_Ind_5 "contains Index Responder 5";
CM_ SG_ 444 StatusUWBRangingFDD1FBD_MM_Tim_9 "contians Time Stamp Responder 5";
CM_ SG_ 444 StatusUWBRangingFDD1FBD_MM_Ti_10 "contains Time Stamp Uncertainty Responder 5";
CM_ SG_ 444 StatusUWBRangingFDD1FBD_MM_Sta_5 "contains Status Responder 5";
CM_ SG_ 444 StatusUWBRangingFDD1FBD_MM_Ind_6 "contains Index Responder 6";
CM_ SG_ 444 StatusUWBRangingFDD1FBD_MM_Ti_11 "contains Time Stamp Responder 6";
CM_ SG_ 444 StatusUWBRangingFDD1FBD_MM_Ti_12 "contains Time Stamp Uncertainty Responder 6";
CM_ SG_ 444 StatusUWBRangingFDD1FBD_MM_Sta_6 "contains Status Responder 6";
CM_ SG_ 444 StatusUWBRangingFDD1FBD_MM_IV0 "contains initialisation vector byte0";
CM_ SG_ 444 StatusUWBRangingFDD1FBD_MM_IV1 "contains initialisation vector byte1";
CM_ SG_ 458 StatusUWBRangingFDD1FBD_SML_Sess "contains Session-ID";
CM_ SG_ 458 StatusUWBRangingFDD1FBD_SML_UWBS "contains UWB Session-ID";
CM_ SG_ 458 StatusUWBRangingFDD1FBD_SML_Rang "contains Ranging Block";
CM_ SG_ 458 StatusUWBRangingFDD1FBD_SML_Hopp "contians Hopping Flag";
CM_ SG_ 458 StatusUWBRangingFDD1FBD_SML_Roun "contains Round Index";
CM_ SG_ 458 StatusUWBRangingFDD1FBD_SML_Fina "contains Final STSIndex";
CM_ SG_ 458 StatusUWBRangingFDD1FBD_SML_Fi_2 "contains Final Time Stamp";
CM_ SG_ 458 StatusUWBRangingFDD1FBD_SML_Numb "contains Number Responder";
CM_ SG_ 458 StatusUWBRangingFDD1FBD_SML_Inde "contains Index Responder 1";
CM_ SG_ 458 StatusUWBRangingFDD1FBD_SML_Time "contains Time Stamp Responder 1";
CM_ SG_ 458 StatusUWBRangingFDD1FBD_SML_Ti_2 "contains Time Stamp Uncertainty Responder 1";
CM_ SG_ 458 StatusUWBRangingFDD1FBD_SML_Stat "contains Status Responder 1";
CM_ SG_ 458 StatusUWBRangingFDD1FBD_SML_In_2 "contains Index Responder 2";
CM_ SG_ 458 StatusUWBRangingFDD1FBD_SML_Ti_3 "contains Time Stamp Responder 2";
CM_ SG_ 458 StatusUWBRangingFDD1FBD_SML_Ti_4 "contains Time Stamp Uncertainty Responder 2";
CM_ SG_ 458 StatusUWBRangingFDD1FBD_SML_St_2 "contains Status Responder 2";
CM_ SG_ 458 StatusUWBRangingFDD1FBD_SML_In_3 "contains Index Responder 3";
CM_ SG_ 458 StatusUWBRangingFDD1FBD_SML_Ti_5 "contains Time Stamp Responder 3";
CM_ SG_ 458 StatusUWBRangingFDD1FBD_SML_Ti_6 "contains Time Stamp Uncertainty Responder 3";
CM_ SG_ 458 StatusUWBRangingFDD1FBD_SML_St_3 "contains Status Responder 3";
CM_ SG_ 458 StatusUWBRangingFDD1FBD_SML_In_4 "contains Index Responder 4";
CM_ SG_ 458 StatusUWBRangingFDD1FBD_SML_Ti_7 "contains Time Stamp Responder 4";
CM_ SG_ 458 StatusUWBRangingFDD1FBD_SML_Ti_8 "contains Time Stamp Uncertainty Responder 4";
CM_ SG_ 458 StatusUWBRangingFDD1FBD_SML_St_4 "contains Status Responder 4";
CM_ SG_ 458 StatusUWBRangingFDD1FBD_SML_In_5 "contains Index Responder 5";
CM_ SG_ 458 StatusUWBRangingFDD1FBD_SML_Ti_9 "contians Time Stamp Responder 5";
CM_ SG_ 458 StatusUWBRangingFDD1FBD_SML_T_10 "contains Time Stamp Uncertainty Responder 5";
CM_ SG_ 458 StatusUWBRangingFDD1FBD_SML_St_5 "contains Status Responder 5";
CM_ SG_ 458 StatusUWBRangingFDD1FBD_SML_In_6 "contains Index Responder 6";
CM_ SG_ 458 StatusUWBRangingFDD1FBD_SML_T_11 "contains Time Stamp Responder 6";
CM_ SG_ 458 StatusUWBRangingFDD1FBD_SML_T_12 "contains Time Stamp Uncertainty Responder 6";
CM_ SG_ 458 StatusUWBRangingFDD1FBD_SML_St_6 "contains Status Responder 6";
CM_ SG_ 458 StatusUWBRangingFDD1FBD_SML_IV0 "contains initialisation vector byte0";
CM_ SG_ 458 StatusUWBRangingFDD1FBD_SML_IV1 "contains initialisation vector byte1";
CM_ SG_ 459 StatusUWBRangingFDD1FBD_SMR_Sess "contains Session-ID";
CM_ SG_ 459 StatusUWBRangingFDD1FBD_SMR_UWBS "contains UWB Session-ID";
CM_ SG_ 459 StatusUWBRangingFDD1FBD_SMR_Rang "contains Ranging Block";
CM_ SG_ 459 StatusUWBRangingFDD1FBD_SMR_Hopp "contians Hopping Flag";
CM_ SG_ 459 StatusUWBRangingFDD1FBD_SMR_Roun "contains Round Index";
CM_ SG_ 459 StatusUWBRangingFDD1FBD_SMR_Fina "contains Final STSIndex";
CM_ SG_ 459 StatusUWBRangingFDD1FBD_SMR_Fi_2 "contains Final Time Stamp";
CM_ SG_ 459 StatusUWBRangingFDD1FBD_SMR_Numb "contains Number Responder";
CM_ SG_ 459 StatusUWBRangingFDD1FBD_SMR_Inde "contains Index Responder 1";
CM_ SG_ 459 StatusUWBRangingFDD1FBD_SMR_Time "contains Time Stamp Responder 1";
CM_ SG_ 459 StatusUWBRangingFDD1FBD_SMR_Ti_2 "contains Time Stamp Uncertainty Responder 1";
CM_ SG_ 459 StatusUWBRangingFDD1FBD_SMR_Stat "contains Status Responder 1";
CM_ SG_ 459 StatusUWBRangingFDD1FBD_SMR_In_2 "contains Index Responder 2";
CM_ SG_ 459 StatusUWBRangingFDD1FBD_SMR_Ti_3 "contains Time Stamp Responder 2";
CM_ SG_ 459 StatusUWBRangingFDD1FBD_SMR_Ti_4 "contains Time Stamp Uncertainty Responder 2";
CM_ SG_ 459 StatusUWBRangingFDD1FBD_SMR_St_2 "contains Status Responder 2";
CM_ SG_ 459 StatusUWBRangingFDD1FBD_SMR_In_3 "contains Index Responder 3";
CM_ SG_ 459 StatusUWBRangingFDD1FBD_SMR_Ti_5 "contains Time Stamp Responder 3";
CM_ SG_ 459 StatusUWBRangingFDD1FBD_SMR_Ti_6 "contains Time Stamp Uncertainty Responder 3";
CM_ SG_ 459 StatusUWBRangingFDD1FBD_SMR_St_3 "contains Status Responder 3";
CM_ SG_ 459 StatusUWBRangingFDD1FBD_SMR_In_4 "contains Index Responder 4";
CM_ SG_ 459 StatusUWBRangingFDD1FBD_SMR_Ti_7 "contains Time Stamp Responder 4";
CM_ SG_ 459 StatusUWBRangingFDD1FBD_SMR_Ti_8 "contains Time Stamp Uncertainty Responder 4";
CM_ SG_ 459 StatusUWBRangingFDD1FBD_SMR_St_4 "contains Status Responder 4";
CM_ SG_ 459 StatusUWBRangingFDD1FBD_SMR_In_5 "contains Index Responder 5";
CM_ SG_ 459 StatusUWBRangingFDD1FBD_SMR_Ti_9 "contians Time Stamp Responder 5";
CM_ SG_ 459 StatusUWBRangingFDD1FBD_SMR_T_10 "contains Time Stamp Uncertainty Responder 5";
CM_ SG_ 459 StatusUWBRangingFDD1FBD_SMR_St_5 "contains Status Responder 5";
CM_ SG_ 459 StatusUWBRangingFDD1FBD_SMR_In_6 "contains Index Responder 6";
CM_ SG_ 459 StatusUWBRangingFDD1FBD_SMR_T_11 "contains Time Stamp Responder 6";
CM_ SG_ 459 StatusUWBRangingFDD1FBD_SMR_T_12 "contains Time Stamp Uncertainty Responder 6";
CM_ SG_ 459 StatusUWBRangingFDD1FBD_SMR_St_6 "contains Status Responder 6";
CM_ SG_ 459 StatusUWBRangingFDD1FBD_SMR_IV0 "contains initialisation vector byte0";
CM_ SG_ 459 StatusUWBRangingFDD1FBD_SMR_IV1 "contains initialisation vector byte1";
CM_ SG_ 453 StatusUWBRangingFDD1FBD_Trunk_Se "contains Session-ID";
CM_ SG_ 453 StatusUWBRangingFDD1FBD_Trunk_UW "contains UWB Session-ID";
CM_ SG_ 453 StatusUWBRangingFDD1FBD_Trunk_Ra "contains Ranging Block";
CM_ SG_ 453 StatusUWBRangingFDD1FBD_Trunk_Ho "contians Hopping Flag";
CM_ SG_ 453 StatusUWBRangingFDD1FBD_Trunk_Ro "contains Round Index";
CM_ SG_ 453 StatusUWBRangingFDD1FBD_Trunk_Fi "contains Final STSIndex";
CM_ SG_ 453 StatusUWBRangingFDD1FBD_Trunk__2 "contains Final Time Stamp";
CM_ SG_ 453 StatusUWBRangingFDD1FBD_Trunk_Nu "contains Number Responder";
CM_ SG_ 453 StatusUWBRangingFDD1FBD_Trunk_In "contains Index Responder 1";
CM_ SG_ 453 StatusUWBRangingFDD1FBD_Trunk_Ti "contains Time Stamp Responder 1";
CM_ SG_ 453 StatusUWBRangingFDD1FBD_Trunk__3 "contains Time Stamp Uncertainty Responder 1";
CM_ SG_ 453 StatusUWBRangingFDD1FBD_Trunk_St "contains Status Responder 1";
CM_ SG_ 453 StatusUWBRangingFDD1FBD_Trunk__4 "contains Index Responder 2";
CM_ SG_ 453 StatusUWBRangingFDD1FBD_Trunk__5 "contains Time Stamp Responder 2";
CM_ SG_ 453 StatusUWBRangingFDD1FBD_Trunk__6 "contains Time Stamp Uncertainty Responder 2";
CM_ SG_ 453 StatusUWBRangingFDD1FBD_Trunk__7 "contains Status Responder 2";
CM_ SG_ 453 StatusUWBRangingFDD1FBD_Trunk__8 "contains Index Responder 3";
CM_ SG_ 453 StatusUWBRangingFDD1FBD_Trunk__9 "contains Time Stamp Responder 3";
CM_ SG_ 453 StatusUWBRangingFDD1FBD_Trunk_10 "contains Time Stamp Uncertainty Responder 3";
CM_ SG_ 453 StatusUWBRangingFDD1FBD_Trunk_11 "contains Status Responder 3";
CM_ SG_ 453 StatusUWBRangingFDD1FBD_Trunk_12 "contains Index Responder 4";
CM_ SG_ 453 StatusUWBRangingFDD1FBD_Trunk_13 "contains Time Stamp Responder 4";
CM_ SG_ 453 StatusUWBRangingFDD1FBD_Trunk_14 "contains Time Stamp Uncertainty Responder 4";
CM_ SG_ 453 StatusUWBRangingFDD1FBD_Trunk_15 "contains Status Responder 4";
CM_ SG_ 453 StatusUWBRangingFDD1FBD_Trunk_16 "contains Index Responder 5";
CM_ SG_ 453 StatusUWBRangingFDD1FBD_Trunk_17 "contians Time Stamp Responder 5";
CM_ SG_ 453 StatusUWBRangingFDD1FBD_Trunk_18 "contains Time Stamp Uncertainty Responder 5";
CM_ SG_ 453 StatusUWBRangingFDD1FBD_Trunk_19 "contains Status Responder 5";
CM_ SG_ 453 StatusUWBRangingFDD1FBD_Trunk_20 "contains Index Responder 6";
CM_ SG_ 453 StatusUWBRangingFDD1FBD_Trunk_21 "contains Time Stamp Responder 6";
CM_ SG_ 453 StatusUWBRangingFDD1FBD_Trunk_22 "contains Time Stamp Uncertainty Responder 6";
CM_ SG_ 453 StatusUWBRangingFDD1FBD_Trunk_23 "contains Status Responder 6";
CM_ SG_ 453 StatusUWBRangingFDD1FBD_Trunk_IV "contains initialisation vector byte0";
CM_ SG_ 453 StatusUWBRangingFDD1FBD_Trunk_24 "contains initialisation vector byte1";
CM_ SG_ 454 StatusUWBRangingFDD1FBD_VL_Sessi "contains Session-ID";
CM_ SG_ 454 StatusUWBRangingFDD1FBD_VL_UWBSe "contains UWB Session-ID";
CM_ SG_ 454 StatusUWBRangingFDD1FBD_VL_Rangi "contains Ranging Block";
CM_ SG_ 454 StatusUWBRangingFDD1FBD_VL_Hoppi "contians Hopping Flag";
CM_ SG_ 454 StatusUWBRangingFDD1FBD_VL_Round "contains Round Index";
CM_ SG_ 454 StatusUWBRangingFDD1FBD_VL_Final "contains Final STSIndex";
CM_ SG_ 454 StatusUWBRangingFDD1FBD_VL_Fin_2 "contains Final Time Stamp";
CM_ SG_ 454 StatusUWBRangingFDD1FBD_VL_Numbe "contains Number Responder";
CM_ SG_ 454 StatusUWBRangingFDD1FBD_VL_Index "contains Index Responder 1";
CM_ SG_ 454 StatusUWBRangingFDD1FBD_VL_TimeS "contains Time Stamp Responder 1";
CM_ SG_ 454 StatusUWBRangingFDD1FBD_VL_Tim_2 "contains Time Stamp Uncertainty Responder 1";
CM_ SG_ 454 StatusUWBRangingFDD1FBD_VL_Statu "contains Status Responder 1";
CM_ SG_ 454 StatusUWBRangingFDD1FBD_VL_Ind_2 "contains Index Responder 2";
CM_ SG_ 454 StatusUWBRangingFDD1FBD_VL_Tim_3 "contains Time Stamp Responder 2";
CM_ SG_ 454 StatusUWBRangingFDD1FBD_VL_Tim_4 "contains Time Stamp Uncertainty Responder 2";
CM_ SG_ 454 StatusUWBRangingFDD1FBD_VL_Sta_2 "contains Status Responder 2";
CM_ SG_ 454 StatusUWBRangingFDD1FBD_VL_Ind_3 "contains Index Responder 3";
CM_ SG_ 454 StatusUWBRangingFDD1FBD_VL_Tim_5 "contains Time Stamp Responder 3";
CM_ SG_ 454 StatusUWBRangingFDD1FBD_VL_Tim_6 "contains Time Stamp Uncertainty Responder 3";
CM_ SG_ 454 StatusUWBRangingFDD1FBD_VL_Sta_3 "contains Status Responder 3";
CM_ SG_ 454 StatusUWBRangingFDD1FBD_VL_Ind_4 "contains Index Responder 4";
CM_ SG_ 454 StatusUWBRangingFDD1FBD_VL_Tim_7 "contains Time Stamp Responder 4";
CM_ SG_ 454 StatusUWBRangingFDD1FBD_VL_Tim_8 "contains Time Stamp Uncertainty Responder 4";
CM_ SG_ 454 StatusUWBRangingFDD1FBD_VL_Sta_4 "contains Status Responder 4";
CM_ SG_ 454 StatusUWBRangingFDD1FBD_VL_Ind_5 "contains Index Responder 5";
CM_ SG_ 454 StatusUWBRangingFDD1FBD_VL_Tim_9 "contians Time Stamp Responder 5";
CM_ SG_ 454 StatusUWBRangingFDD1FBD_VL_Ti_10 "contains Time Stamp Uncertainty Responder 5";
CM_ SG_ 454 StatusUWBRangingFDD1FBD_VL_Sta_5 "contains Status Responder 5";
CM_ SG_ 454 StatusUWBRangingFDD1FBD_VL_Ind_6 "contains Index Responder 6";
CM_ SG_ 454 StatusUWBRangingFDD1FBD_VL_Ti_11 "contains Time Stamp Responder 6";
CM_ SG_ 454 StatusUWBRangingFDD1FBD_VL_Ti_12 "contains Time Stamp Uncertainty Responder 6";
CM_ SG_ 454 StatusUWBRangingFDD1FBD_VL_Sta_6 "contains Status Responder 6";
CM_ SG_ 454 StatusUWBRangingFDD1FBD_VL_IV0 "contains initialisation vector byte0";
CM_ SG_ 454 StatusUWBRangingFDD1FBD_VL_IV1 "contains initialisation vector byte1";
CM_ SG_ 450 StatusUWBRangingFDD1FBD_VM_Sessi "contains Session-ID";
CM_ SG_ 450 StatusUWBRangingFDD1FBD_VM_UWBSe "contains UWB Session-ID";
CM_ SG_ 450 StatusUWBRangingFDD1FBD_VM_Rangi "contains Ranging Block";
CM_ SG_ 450 StatusUWBRangingFDD1FBD_VM_Hoppi "contians Hopping Flag";
CM_ SG_ 450 StatusUWBRangingFDD1FBD_VM_Round "contains Round Index";
CM_ SG_ 450 StatusUWBRangingFDD1FBD_VM_Final "contains Final STSIndex";
CM_ SG_ 450 StatusUWBRangingFDD1FBD_VM_Fin_2 "contains Final Time Stamp";
CM_ SG_ 450 StatusUWBRangingFDD1FBD_VM_Numbe "contains Number Responder";
CM_ SG_ 450 StatusUWBRangingFDD1FBD_VM_Index "contains Index Responder 1";
CM_ SG_ 450 StatusUWBRangingFDD1FBD_VM_TimeS "contains Time Stamp Responder 1";
CM_ SG_ 450 StatusUWBRangingFDD1FBD_VM_Tim_2 "contains Time Stamp Uncertainty Responder 1";
CM_ SG_ 450 StatusUWBRangingFDD1FBD_VM_Statu "contains Status Responder 1";
CM_ SG_ 450 StatusUWBRangingFDD1FBD_VM_Ind_2 "contains Index Responder 2";
CM_ SG_ 450 StatusUWBRangingFDD1FBD_VM_Tim_3 "contains Time Stamp Responder 2";
CM_ SG_ 450 StatusUWBRangingFDD1FBD_VM_Tim_4 "contains Time Stamp Uncertainty Responder 2";
CM_ SG_ 450 StatusUWBRangingFDD1FBD_VM_Sta_2 "contains Status Responder 2";
CM_ SG_ 450 StatusUWBRangingFDD1FBD_VM_Ind_3 "contains Index Responder 3";
CM_ SG_ 450 StatusUWBRangingFDD1FBD_VM_Tim_5 "contains Time Stamp Responder 3";
CM_ SG_ 450 StatusUWBRangingFDD1FBD_VM_Tim_6 "contains Time Stamp Uncertainty Responder 3";
CM_ SG_ 450 StatusUWBRangingFDD1FBD_VM_Sta_3 "contains Status Responder 3";
CM_ SG_ 450 StatusUWBRangingFDD1FBD_VM_Ind_4 "contains Index Responder 4";
CM_ SG_ 450 StatusUWBRangingFDD1FBD_VM_Tim_7 "contains Time Stamp Responder 4";
CM_ SG_ 450 StatusUWBRangingFDD1FBD_VM_Tim_8 "contains Time Stamp Uncertainty Responder 4";
CM_ SG_ 450 StatusUWBRangingFDD1FBD_VM_Sta_4 "contains Status Responder 4";
CM_ SG_ 450 StatusUWBRangingFDD1FBD_VM_Ind_5 "contains Index Responder 5";
CM_ SG_ 450 StatusUWBRangingFDD1FBD_VM_Tim_9 "contians Time Stamp Responder 5";
CM_ SG_ 450 StatusUWBRangingFDD1FBD_VM_Ti_10 "contains Time Stamp Uncertainty Responder 5";
CM_ SG_ 450 StatusUWBRangingFDD1FBD_VM_Sta_5 "contains Status Responder 5";
CM_ SG_ 450 StatusUWBRangingFDD1FBD_VM_Ind_6 "contains Index Responder 6";
CM_ SG_ 450 StatusUWBRangingFDD1FBD_VM_Ti_11 "contains Time Stamp Responder 6";
CM_ SG_ 450 StatusUWBRangingFDD1FBD_VM_Ti_12 "contains Time Stamp Uncertainty Responder 6";
CM_ SG_ 450 StatusUWBRangingFDD1FBD_VM_Sta_6 "contains Status Responder 6";
CM_ SG_ 450 StatusUWBRangingFDD1FBD_VM_IV0 "contains initialisation vector byte0";
CM_ SG_ 450 StatusUWBRangingFDD1FBD_VM_IV1 "contains initialisation vector byte1";
CM_ SG_ 455 StatusUWBRangingFDD1FBD_VR_Sessi "contains Session-ID";
CM_ SG_ 455 StatusUWBRangingFDD1FBD_VR_UWBSe "contains UWB Session-ID";
CM_ SG_ 455 StatusUWBRangingFDD1FBD_VR_Rangi "contains Ranging Block";
CM_ SG_ 455 StatusUWBRangingFDD1FBD_VR_Hoppi "contians Hopping Flag";
CM_ SG_ 455 StatusUWBRangingFDD1FBD_VR_Round "contains Round Index";
CM_ SG_ 455 StatusUWBRangingFDD1FBD_VR_Final "contains Final STSIndex";
CM_ SG_ 455 StatusUWBRangingFDD1FBD_VR_Fin_2 "contains Final Time Stamp";
CM_ SG_ 455 StatusUWBRangingFDD1FBD_VR_Numbe "contains Number Responder";
CM_ SG_ 455 StatusUWBRangingFDD1FBD_VR_Index "contains Index Responder 1";
CM_ SG_ 455 StatusUWBRangingFDD1FBD_VR_TimeS "contains Time Stamp Responder 1";
CM_ SG_ 455 StatusUWBRangingFDD1FBD_VR_Tim_2 "contains Time Stamp Uncertainty Responder 1";
CM_ SG_ 455 StatusUWBRangingFDD1FBD_VR_Statu "contains Status Responder 1";
CM_ SG_ 455 StatusUWBRangingFDD1FBD_VR_Ind_2 "contains Index Responder 2";
CM_ SG_ 455 StatusUWBRangingFDD1FBD_VR_Tim_3 "contains Time Stamp Responder 2";
CM_ SG_ 455 StatusUWBRangingFDD1FBD_VR_Tim_4 "contains Time Stamp Uncertainty Responder 2";
CM_ SG_ 455 StatusUWBRangingFDD1FBD_VR_Sta_2 "contains Status Responder 2";
CM_ SG_ 455 StatusUWBRangingFDD1FBD_VR_Ind_3 "contains Index Responder 3";
CM_ SG_ 455 StatusUWBRangingFDD1FBD_VR_Tim_5 "contains Time Stamp Responder 3";
CM_ SG_ 455 StatusUWBRangingFDD1FBD_VR_Tim_6 "contains Time Stamp Uncertainty Responder 3";
CM_ SG_ 455 StatusUWBRangingFDD1FBD_VR_Sta_3 "contains Status Responder 3";
CM_ SG_ 455 StatusUWBRangingFDD1FBD_VR_Ind_4 "contains Index Responder 4";
CM_ SG_ 455 StatusUWBRangingFDD1FBD_VR_Tim_7 "contains Time Stamp Responder 4";
CM_ SG_ 455 StatusUWBRangingFDD1FBD_VR_Tim_8 "contains Time Stamp Uncertainty Responder 4";
CM_ SG_ 455 StatusUWBRangingFDD1FBD_VR_Sta_4 "contains Status Responder 4";
CM_ SG_ 455 StatusUWBRangingFDD1FBD_VR_Ind_5 "contains Index Responder 5";
CM_ SG_ 455 StatusUWBRangingFDD1FBD_VR_Tim_9 "contians Time Stamp Responder 5";
CM_ SG_ 455 StatusUWBRangingFDD1FBD_VR_Ti_10 "contains Time Stamp Uncertainty Responder 5";
CM_ SG_ 455 StatusUWBRangingFDD1FBD_VR_Sta_5 "contains Status Responder 5";
CM_ SG_ 455 StatusUWBRangingFDD1FBD_VR_Ind_6 "contains Index Responder 6";
CM_ SG_ 455 StatusUWBRangingFDD1FBD_VR_Ti_11 "contains Time Stamp Responder 6";
CM_ SG_ 455 StatusUWBRangingFDD1FBD_VR_Ti_12 "contains Time Stamp Uncertainty Responder 6";
CM_ SG_ 455 StatusUWBRangingFDD1FBD_VR_Sta_6 "contains Status Responder 6";
CM_ SG_ 455 StatusUWBRangingFDD1FBD_VR_IV0 "contains initialisation vector byte0";
CM_ SG_ 455 StatusUWBRangingFDD1FBD_VR_IV1 "contains initialisation vector byte1";
CM_ SG_ 466 StatusUWBRangingFDD2FBD_HL_Sessi "contains Session-ID";
CM_ SG_ 466 StatusUWBRangingFDD2FBD_HL_Index "contains Index Responder 7";
CM_ SG_ 466 StatusUWBRangingFDD2FBD_HL_TimeS "contains Time Stamp Responder 7";
CM_ SG_ 466 StatusUWBRangingFDD2FBD_HL_Tim_2 "contains Time Stamp Uncertainty Responder 7";
CM_ SG_ 466 StatusUWBRangingFDD2FBD_HL_Statu "contains Status Responder 7";
CM_ SG_ 466 StatusUWBRangingFDD2FBD_HL_Ind_2 "contains Index Responder 8";
CM_ SG_ 466 StatusUWBRangingFDD2FBD_HL_Tim_3 "contains Time Stamp Responder 8";
CM_ SG_ 466 StatusUWBRangingFDD2FBD_HL_Tim_4 "contains Time Stamp Uncertainty Responder 8";
CM_ SG_ 466 StatusUWBRangingFDD2FBD_HL_Sta_2 "contains Status Responder 8";
CM_ SG_ 466 StatusUWBRangingFDD2FBD_HL_Ind_3 "contains Index Responder 9";
CM_ SG_ 466 StatusUWBRangingFDD2FBD_HL_Tim_5 "contains Time Stamp Responder 9";
CM_ SG_ 466 StatusUWBRangingFDD2FBD_HL_Tim_6 "contains Time Stamp Uncertainty Responder 9";
CM_ SG_ 466 StatusUWBRangingFDD2FBD_HL_Sta_3 "contains Status Responder 9";
CM_ SG_ 466 StatusUWBRangingFDD2FBD_HL_Ind_4 "contains Index Responder 10";
CM_ SG_ 466 StatusUWBRangingFDD2FBD_HL_Tim_7 "contains Time Stamp Responder 10";
CM_ SG_ 466 StatusUWBRangingFDD2FBD_HL_Tim_8 "contains Time Stamp Uncertainty Responder 10";
CM_ SG_ 466 StatusUWBRangingFDD2FBD_HL_Sta_4 "contains Status Responder 10";
CM_ SG_ 466 StatusUWBRangingFDD2FBD_HL_Tim_9 "UWB TimeStamp of Poll";
CM_ SG_ 466 StatusUWBRangingFDD2FBD_HL_Signa "contains signature, only signal TAG 0xFF possible";
CM_ SG_ 466 StatusUWBRangingFDD2FBD_HL_IV2 "contains initialisation vector byte2";
CM_ SG_ 466 StatusUWBRangingFDD2FBD_HL_IV3 "contains initialisation vector byte3";
CM_ SG_ 461 StatusUWBRangingFDD2FBD_HM_Sessi "contains Session-ID";
CM_ SG_ 461 StatusUWBRangingFDD2FBD_HM_Index "contains Index Responder 7";
CM_ SG_ 461 StatusUWBRangingFDD2FBD_HM_TimeS "contains Time Stamp Responder 7";
CM_ SG_ 461 StatusUWBRangingFDD2FBD_HM_Tim_2 "contains Time Stamp Uncertainty Responder 7";
CM_ SG_ 461 StatusUWBRangingFDD2FBD_HM_Statu "contains Status Responder 7";
CM_ SG_ 461 StatusUWBRangingFDD2FBD_HM_Ind_2 "contains Index Responder 8";
CM_ SG_ 461 StatusUWBRangingFDD2FBD_HM_Tim_3 "contains Time Stamp Responder 8";
CM_ SG_ 461 StatusUWBRangingFDD2FBD_HM_Tim_4 "contains Time Stamp Uncertainty Responder 8";
CM_ SG_ 461 StatusUWBRangingFDD2FBD_HM_Sta_2 "contains Status Responder 8";
CM_ SG_ 461 StatusUWBRangingFDD2FBD_HM_Ind_3 "contains Index Responder 9";
CM_ SG_ 461 StatusUWBRangingFDD2FBD_HM_Tim_5 "contains Time Stamp Responder 9";
CM_ SG_ 461 StatusUWBRangingFDD2FBD_HM_Tim_6 "contains Time Stamp Uncertainty Responder 9";
CM_ SG_ 461 StatusUWBRangingFDD2FBD_HM_Sta_3 "contains Status Responder 9";
CM_ SG_ 461 StatusUWBRangingFDD2FBD_HM_Ind_4 "contains Index Responder 10";
CM_ SG_ 461 StatusUWBRangingFDD2FBD_HM_Tim_7 "contains Time Stamp Responder 10";
CM_ SG_ 461 StatusUWBRangingFDD2FBD_HM_Tim_8 "contains Time Stamp Uncertainty Responder 10";
CM_ SG_ 461 StatusUWBRangingFDD2FBD_HM_Sta_4 "contains Status Responder 10";
CM_ SG_ 461 StatusUWBRangingFDD2FBD_HM_Tim_9 "UWB TimeStamp of Poll";
CM_ SG_ 461 StatusUWBRangingFDD2FBD_HM_Signa "contains signature, only signal TAG 0xFF possible";
CM_ SG_ 461 StatusUWBRangingFDD2FBD_HM_IV2 "contains initialisation vector byte2";
CM_ SG_ 461 StatusUWBRangingFDD2FBD_HM_IV3 "contains initialisation vector byte3";
CM_ SG_ 467 StatusUWBRangingFDD2FBD_HR_Sessi "contains Session-ID";
CM_ SG_ 467 StatusUWBRangingFDD2FBD_HR_Index "contains Index Responder 7";
CM_ SG_ 467 StatusUWBRangingFDD2FBD_HR_TimeS "contains Time Stamp Responder 7";
CM_ SG_ 467 StatusUWBRangingFDD2FBD_HR_Tim_2 "contains Time Stamp Uncertainty Responder 7";
CM_ SG_ 467 StatusUWBRangingFDD2FBD_HR_Statu "contains Status Responder 7";
CM_ SG_ 467 StatusUWBRangingFDD2FBD_HR_Ind_2 "contains Index Responder 8";
CM_ SG_ 467 StatusUWBRangingFDD2FBD_HR_Tim_3 "contains Time Stamp Responder 8";
CM_ SG_ 467 StatusUWBRangingFDD2FBD_HR_Tim_4 "contains Time Stamp Uncertainty Responder 8";
CM_ SG_ 467 StatusUWBRangingFDD2FBD_HR_Sta_2 "contains Status Responder 8";
CM_ SG_ 467 StatusUWBRangingFDD2FBD_HR_Ind_3 "contains Index Responder 9";
CM_ SG_ 467 StatusUWBRangingFDD2FBD_HR_Tim_5 "contains Time Stamp Responder 9";
CM_ SG_ 467 StatusUWBRangingFDD2FBD_HR_Tim_6 "contains Time Stamp Uncertainty Responder 9";
CM_ SG_ 467 StatusUWBRangingFDD2FBD_HR_Sta_3 "contains Status Responder 9";
CM_ SG_ 467 StatusUWBRangingFDD2FBD_HR_Ind_4 "contains Index Responder 10";
CM_ SG_ 467 StatusUWBRangingFDD2FBD_HR_Tim_7 "contains Time Stamp Responder 10";
CM_ SG_ 467 StatusUWBRangingFDD2FBD_HR_Tim_8 "contains Time Stamp Uncertainty Responder 10";
CM_ SG_ 467 StatusUWBRangingFDD2FBD_HR_Sta_4 "contains Status Responder 10";
CM_ SG_ 467 StatusUWBRangingFDD2FBD_HR_Tim_9 "UWB TimeStamp of Poll";
CM_ SG_ 467 StatusUWBRangingFDD2FBD_HR_Signa "contains signature, only signal TAG 0xFF possible";
CM_ SG_ 467 StatusUWBRangingFDD2FBD_HR_IV2 "contains initialisation vector byte2";
CM_ SG_ 467 StatusUWBRangingFDD2FBD_HR_IV3 "contains initialisation vector byte3";
CM_ SG_ 462 StatusUWBRangingFDD2FBD_Miko_Ses "contains Session-ID";
CM_ SG_ 462 StatusUWBRangingFDD2FBD_Miko_Ind "contains Index Responder 7";
CM_ SG_ 462 StatusUWBRangingFDD2FBD_Miko_Tim "contains Time Stamp Responder 7";
CM_ SG_ 462 StatusUWBRangingFDD2FBD_Miko_T_2 "contains Time Stamp Uncertainty Responder 7";
CM_ SG_ 462 StatusUWBRangingFDD2FBD_Miko_Sta "contains Status Responder 7";
CM_ SG_ 462 StatusUWBRangingFDD2FBD_Miko_I_2 "contains Index Responder 8";
CM_ SG_ 462 StatusUWBRangingFDD2FBD_Miko_T_3 "contains Time Stamp Responder 8";
CM_ SG_ 462 StatusUWBRangingFDD2FBD_Miko_T_4 "contains Time Stamp Uncertainty Responder 8";
CM_ SG_ 462 StatusUWBRangingFDD2FBD_Miko_S_2 "contains Status Responder 8";
CM_ SG_ 462 StatusUWBRangingFDD2FBD_Miko_I_3 "contains Index Responder 9";
CM_ SG_ 462 StatusUWBRangingFDD2FBD_Miko_T_5 "contains Time Stamp Responder 9";
CM_ SG_ 462 StatusUWBRangingFDD2FBD_Miko_T_6 "contains Time Stamp Uncertainty Responder 9";
CM_ SG_ 462 StatusUWBRangingFDD2FBD_Miko_S_3 "contains Status Responder 9";
CM_ SG_ 462 StatusUWBRangingFDD2FBD_Miko_I_4 "contains Index Responder 10";
CM_ SG_ 462 StatusUWBRangingFDD2FBD_Miko_T_7 "contains Time Stamp Responder 10";
CM_ SG_ 462 StatusUWBRangingFDD2FBD_Miko_T_8 "contains Time Stamp Uncertainty Responder 10";
CM_ SG_ 462 StatusUWBRangingFDD2FBD_Miko_S_4 "contains Status Responder 10";
CM_ SG_ 462 StatusUWBRangingFDD2FBD_Miko_T_9 "UWB TimeStamp of Poll";
CM_ SG_ 462 StatusUWBRangingFDD2FBD_Miko_Sig "contains signature, only signal TAG 0xFF possible";
CM_ SG_ 462 StatusUWBRangingFDD2FBD_Miko_IV2 "contains initialisation vector byte2";
CM_ SG_ 462 StatusUWBRangingFDD2FBD_Miko_IV3 "contains initialisation vector byte3";
CM_ SG_ 445 StatusUWBRangingFDD2FBD_MM_Sessi "contains Session-ID short";
CM_ SG_ 445 StatusUWBRangingFDD2FBD_MM_Index "contains Index Responder 7";
CM_ SG_ 445 StatusUWBRangingFDD2FBD_MM_TimeS "contains Time Stamp Responder 7";
CM_ SG_ 445 StatusUWBRangingFDD2FBD_MM_Tim_2 "contains Time Stamp Uncertainty Responder 7";
CM_ SG_ 445 StatusUWBRangingFDD2FBD_MM_Statu "contains Status Responder 7";
CM_ SG_ 445 StatusUWBRangingFDD2FBD_MM_Ind_2 "contains Index Responder 8";
CM_ SG_ 445 StatusUWBRangingFDD2FBD_MM_Tim_3 "contains Time Stamp Responder 8";
CM_ SG_ 445 StatusUWBRangingFDD2FBD_MM_Tim_4 "contains Time Stamp Uncertainty Responder 8";
CM_ SG_ 445 StatusUWBRangingFDD2FBD_MM_Sta_2 "contains Status Responder 8";
CM_ SG_ 445 StatusUWBRangingFDD2FBD_MM_Ind_3 "contains Index Responder 9";
CM_ SG_ 445 StatusUWBRangingFDD2FBD_MM_Tim_5 "contains Time Stamp Responder 9";
CM_ SG_ 445 StatusUWBRangingFDD2FBD_MM_Tim_6 "contains Time Stamp Uncertainty Responder 9";
CM_ SG_ 445 StatusUWBRangingFDD2FBD_MM_Sta_3 "contains Status Responder 9";
CM_ SG_ 445 StatusUWBRangingFDD2FBD_MM_Ind_4 "contains Index Responder 10";
CM_ SG_ 445 StatusUWBRangingFDD2FBD_MM_Tim_7 "contains Time Stamp Responder 10";
CM_ SG_ 445 StatusUWBRangingFDD2FBD_MM_Tim_8 "contains Time Stamp Uncertainty Responder 10";
CM_ SG_ 445 StatusUWBRangingFDD2FBD_MM_Sta_4 "contains Status Responder 10";
CM_ SG_ 445 StatusUWBRangingFDD2FBD_MM_Tim_9 "UWB TimeStamp of Poll";
CM_ SG_ 445 StatusUWBRangingFDD2FBD_MM_Signa "contains signature, only signal TAG 0xFF possible";
CM_ SG_ 445 StatusUWBRangingFDD2FBD_MM_IV2 "contains initialisation vector byte2";
CM_ SG_ 445 StatusUWBRangingFDD2FBD_MM_IV3 "contains initialisation vector byte3";
CM_ SG_ 468 StatusUWBRangingFDD2FBD_SML_Sess "contains Session-ID";
CM_ SG_ 468 StatusUWBRangingFDD2FBD_SML_Inde "contains Index Responder 7";
CM_ SG_ 468 StatusUWBRangingFDD2FBD_SML_Time "contains Time Stamp Responder 7";
CM_ SG_ 468 StatusUWBRangingFDD2FBD_SML_Ti_2 "contains Time Stamp Uncertainty Responder 7";
CM_ SG_ 468 StatusUWBRangingFDD2FBD_SML_Stat "contains Status Responder 7";
CM_ SG_ 468 StatusUWBRangingFDD2FBD_SML_In_2 "contains Index Responder 8";
CM_ SG_ 468 StatusUWBRangingFDD2FBD_SML_Ti_3 "contains Time Stamp Responder 8";
CM_ SG_ 468 StatusUWBRangingFDD2FBD_SML_Ti_4 "contains Time Stamp Uncertainty Responder 8";
CM_ SG_ 468 StatusUWBRangingFDD2FBD_SML_St_2 "contains Status Responder 8";
CM_ SG_ 468 StatusUWBRangingFDD2FBD_SML_In_3 "contains Index Responder 9";
CM_ SG_ 468 StatusUWBRangingFDD2FBD_SML_Ti_5 "contains Time Stamp Responder 9";
CM_ SG_ 468 StatusUWBRangingFDD2FBD_SML_Ti_6 "contains Time Stamp Uncertainty Responder 9";
CM_ SG_ 468 StatusUWBRangingFDD2FBD_SML_St_3 "contains Status Responder 9";
CM_ SG_ 468 StatusUWBRangingFDD2FBD_SML_In_4 "contains Index Responder 10";
CM_ SG_ 468 StatusUWBRangingFDD2FBD_SML_Ti_7 "contains Time Stamp Responder 10";
CM_ SG_ 468 StatusUWBRangingFDD2FBD_SML_Ti_8 "contains Time Stamp Uncertainty Responder 10";
CM_ SG_ 468 StatusUWBRangingFDD2FBD_SML_St_4 "contains Status Responder 10";
CM_ SG_ 468 StatusUWBRangingFDD2FBD_SML_Ti_9 "UWB TimeStamp of Poll";
CM_ SG_ 468 StatusUWBRangingFDD2FBD_SML_Sign "contains signature, only signal TAG 0xFF possible";
CM_ SG_ 468 StatusUWBRangingFDD2FBD_SML_IV2 "contains initialisation vector byte2";
CM_ SG_ 468 StatusUWBRangingFDD2FBD_SML_IV3 "contains initialisation vector byte3";
CM_ SG_ 469 StatusUWBRangingFDD2FBD_SMR_Sess "contains Session-ID";
CM_ SG_ 469 StatusUWBRangingFDD2FBD_SMR_Inde "contains Index Responder 7";
CM_ SG_ 469 StatusUWBRangingFDD2FBD_SMR_Time "contains Time Stamp Responder 7";
CM_ SG_ 469 StatusUWBRangingFDD2FBD_SMR_Ti_2 "contains Time Stamp Uncertainty Responder 7";
CM_ SG_ 469 StatusUWBRangingFDD2FBD_SMR_Stat "contains Status Responder 7";
CM_ SG_ 469 StatusUWBRangingFDD2FBD_SMR_In_2 "contains Index Responder 8";
CM_ SG_ 469 StatusUWBRangingFDD2FBD_SMR_Ti_3 "contains Time Stamp Responder 8";
CM_ SG_ 469 StatusUWBRangingFDD2FBD_SMR_Ti_4 "contains Time Stamp Uncertainty Responder 8";
CM_ SG_ 469 StatusUWBRangingFDD2FBD_SMR_St_2 "contains Status Responder 8";
CM_ SG_ 469 StatusUWBRangingFDD2FBD_SMR_In_3 "contains Index Responder 9";
CM_ SG_ 469 StatusUWBRangingFDD2FBD_SMR_Ti_5 "contains Time Stamp Responder 9";
CM_ SG_ 469 StatusUWBRangingFDD2FBD_SMR_Ti_6 "contains Time Stamp Uncertainty Responder 9";
CM_ SG_ 469 StatusUWBRangingFDD2FBD_SMR_St_3 "contains Status Responder 9";
CM_ SG_ 469 StatusUWBRangingFDD2FBD_SMR_In_4 "contains Index Responder 10";
CM_ SG_ 469 StatusUWBRangingFDD2FBD_SMR_Ti_7 "contains Time Stamp Responder 10";
CM_ SG_ 469 StatusUWBRangingFDD2FBD_SMR_Ti_8 "contains Time Stamp Uncertainty Responder 10";
CM_ SG_ 469 StatusUWBRangingFDD2FBD_SMR_St_4 "contains Status Responder 10";
CM_ SG_ 469 StatusUWBRangingFDD2FBD_SMR_Ti_9 "UWB TimeStamp of Poll";
CM_ SG_ 469 StatusUWBRangingFDD2FBD_SMR_Sign "contains signature, only signal TAG 0xFF possible";
CM_ SG_ 469 StatusUWBRangingFDD2FBD_SMR_IV2 "contains initialisation vector byte2";
CM_ SG_ 469 StatusUWBRangingFDD2FBD_SMR_IV3 "contains initialisation vector byte3";
CM_ SG_ 463 StatusUWBRangingFDD2FBD_Trunk_Se "contains Session-ID";
CM_ SG_ 463 StatusUWBRangingFDD2FBD_Trunk_In "contains Index Responder 7";
CM_ SG_ 463 StatusUWBRangingFDD2FBD_Trunk_Ti "contains Time Stamp Responder 7";
CM_ SG_ 463 StatusUWBRangingFDD2FBD_Trunk__2 "contains Time Stamp Uncertainty Responder 7";
CM_ SG_ 463 StatusUWBRangingFDD2FBD_Trunk_St "contains Status Responder 7";
CM_ SG_ 463 StatusUWBRangingFDD2FBD_Trunk__3 "contains Index Responder 8";
CM_ SG_ 463 StatusUWBRangingFDD2FBD_Trunk__4 "contains Time Stamp Responder 8";
CM_ SG_ 463 StatusUWBRangingFDD2FBD_Trunk__5 "contains Time Stamp Uncertainty Responder 8";
CM_ SG_ 463 StatusUWBRangingFDD2FBD_Trunk__6 "contains Status Responder 8";
CM_ SG_ 463 StatusUWBRangingFDD2FBD_Trunk__7 "contains Index Responder 9";
CM_ SG_ 463 StatusUWBRangingFDD2FBD_Trunk__8 "contains Time Stamp Responder 9";
CM_ SG_ 463 StatusUWBRangingFDD2FBD_Trunk__9 "contains Time Stamp Uncertainty Responder 9";
CM_ SG_ 463 StatusUWBRangingFDD2FBD_Trunk_10 "contains Status Responder 9";
CM_ SG_ 463 StatusUWBRangingFDD2FBD_Trunk_11 "contains Index Responder 10";
CM_ SG_ 463 StatusUWBRangingFDD2FBD_Trunk_12 "contains Time Stamp Responder 10";
CM_ SG_ 463 StatusUWBRangingFDD2FBD_Trunk_13 "contains Time Stamp Uncertainty Responder 10";
CM_ SG_ 463 StatusUWBRangingFDD2FBD_Trunk_14 "contains Status Responder 10";
CM_ SG_ 463 StatusUWBRangingFDD2FBD_Trunk_15 "UWB TimeStamp of Poll";
CM_ SG_ 463 StatusUWBRangingFDD2FBD_Trunk_Si "contains signature, only signal TAG 0xFF possible";
CM_ SG_ 463 StatusUWBRangingFDD2FBD_Trunk_IV "contains initialisation vector byte2";
CM_ SG_ 463 StatusUWBRangingFDD2FBD_Trunk_16 "contains initialisation vector byte3";
CM_ SG_ 464 StatusUWBRangingFDD2FBD_VL_Sessi "contains Session-ID";
CM_ SG_ 464 StatusUWBRangingFDD2FBD_VL_Index "contains Index Responder 7";
CM_ SG_ 464 StatusUWBRangingFDD2FBD_VL_TimeS "contains Time Stamp Responder 7";
CM_ SG_ 464 StatusUWBRangingFDD2FBD_VL_Tim_2 "contains Time Stamp Uncertainty Responder 7";
CM_ SG_ 464 StatusUWBRangingFDD2FBD_VL_Statu "contains Status Responder 7";
CM_ SG_ 464 StatusUWBRangingFDD2FBD_VL_Ind_2 "contains Index Responder 8";
CM_ SG_ 464 StatusUWBRangingFDD2FBD_VL_Tim_3 "contains Time Stamp Responder 8";
CM_ SG_ 464 StatusUWBRangingFDD2FBD_VL_Tim_4 "contains Time Stamp Uncertainty Responder 8";
CM_ SG_ 464 StatusUWBRangingFDD2FBD_VL_Sta_2 "contains Status Responder 8";
CM_ SG_ 464 StatusUWBRangingFDD2FBD_VL_Ind_3 "contains Index Responder 9";
CM_ SG_ 464 StatusUWBRangingFDD2FBD_VL_Tim_5 "contains Time Stamp Responder 9";
CM_ SG_ 464 StatusUWBRangingFDD2FBD_VL_Tim_6 "contains Time Stamp Uncertainty Responder 9";
CM_ SG_ 464 StatusUWBRangingFDD2FBD_VL_Sta_3 "contains Status Responder 9";
CM_ SG_ 464 StatusUWBRangingFDD2FBD_VL_Ind_4 "contains Index Responder 10";
CM_ SG_ 464 StatusUWBRangingFDD2FBD_VL_Tim_7 "contains Time Stamp Responder 10";
CM_ SG_ 464 StatusUWBRangingFDD2FBD_VL_Tim_8 "contains Time Stamp Uncertainty Responder 10";
CM_ SG_ 464 StatusUWBRangingFDD2FBD_VL_Sta_4 "contains Status Responder 10";
CM_ SG_ 464 StatusUWBRangingFDD2FBD_VL_Tim_9 "UWB TimeStamp of Poll";
CM_ SG_ 464 StatusUWBRangingFDD2FBD_VL_Signa "contains signature, only signal TAG 0xFF possible";
CM_ SG_ 464 StatusUWBRangingFDD2FBD_VL_IV2 "contains initialisation vector byte2";
CM_ SG_ 464 StatusUWBRangingFDD2FBD_VL_IV3 "contains initialisation vector byte3";
CM_ SG_ 460 StatusUWBRangingFDD2FBD_VM_Sessi "contains Session-ID";
CM_ SG_ 460 StatusUWBRangingFDD2FBD_VM_Index "contains Index Responder 7";
CM_ SG_ 460 StatusUWBRangingFDD2FBD_VM_TimeS "contains Time Stamp Responder 7";
CM_ SG_ 460 StatusUWBRangingFDD2FBD_VM_Tim_2 "contains Time Stamp Uncertainty Responder 7";
CM_ SG_ 460 StatusUWBRangingFDD2FBD_VM_Statu "contains Status Responder 7";
CM_ SG_ 460 StatusUWBRangingFDD2FBD_VM_Ind_2 "contains Index Responder 8";
CM_ SG_ 460 StatusUWBRangingFDD2FBD_VM_Tim_3 "contains Time Stamp Responder 8";
CM_ SG_ 460 StatusUWBRangingFDD2FBD_VM_Tim_4 "contains Time Stamp Uncertainty Responder 8";
CM_ SG_ 460 StatusUWBRangingFDD2FBD_VM_Sta_2 "contains Status Responder 8";
CM_ SG_ 460 StatusUWBRangingFDD2FBD_VM_Ind_3 "contains Index Responder 9";
CM_ SG_ 460 StatusUWBRangingFDD2FBD_VM_Tim_5 "contains Time Stamp Responder 9";
CM_ SG_ 460 StatusUWBRangingFDD2FBD_VM_Tim_6 "contains Time Stamp Uncertainty Responder 9";
CM_ SG_ 460 StatusUWBRangingFDD2FBD_VM_Sta_3 "contains Status Responder 9";
CM_ SG_ 460 StatusUWBRangingFDD2FBD_VM_Ind_4 "contains Index Responder 10";
CM_ SG_ 460 StatusUWBRangingFDD2FBD_VM_Tim_7 "contains Time Stamp Responder 10";
CM_ SG_ 460 StatusUWBRangingFDD2FBD_VM_Tim_8 "contains Time Stamp Uncertainty Responder 10";
CM_ SG_ 460 StatusUWBRangingFDD2FBD_VM_Sta_4 "contains Status Responder 10";
CM_ SG_ 460 StatusUWBRangingFDD2FBD_VM_Tim_9 "UWB TimeStamp of Poll";
CM_ SG_ 460 StatusUWBRangingFDD2FBD_VM_Signa "contains signature, only signal TAG 0xFF possible";
CM_ SG_ 460 StatusUWBRangingFDD2FBD_VM_IV2 "contains initialisation vector byte2";
CM_ SG_ 460 StatusUWBRangingFDD2FBD_VM_IV3 "contains initialisation vector byte3";
CM_ SG_ 465 StatusUWBRangingFDD2FBD_VR_Sessi "contains Session-ID";
CM_ SG_ 465 StatusUWBRangingFDD2FBD_VR_Index "contains Index Responder 7";
CM_ SG_ 465 StatusUWBRangingFDD2FBD_VR_TimeS "contains Time Stamp Responder 7";
CM_ SG_ 465 StatusUWBRangingFDD2FBD_VR_Tim_2 "contains Time Stamp Uncertainty Responder 7";
CM_ SG_ 465 StatusUWBRangingFDD2FBD_VR_Statu "contains Status Responder 7";
CM_ SG_ 465 StatusUWBRangingFDD2FBD_VR_Ind_2 "contains Index Responder 8";
CM_ SG_ 465 StatusUWBRangingFDD2FBD_VR_Tim_3 "contains Time Stamp Responder 8";
CM_ SG_ 465 StatusUWBRangingFDD2FBD_VR_Tim_4 "contains Time Stamp Uncertainty Responder 8";
CM_ SG_ 465 StatusUWBRangingFDD2FBD_VR_Sta_2 "contains Status Responder 8";
CM_ SG_ 465 StatusUWBRangingFDD2FBD_VR_Ind_3 "contains Index Responder 9";
CM_ SG_ 465 StatusUWBRangingFDD2FBD_VR_Tim_5 "contains Time Stamp Responder 9";
CM_ SG_ 465 StatusUWBRangingFDD2FBD_VR_Tim_6 "contains Time Stamp Uncertainty Responder 9";
CM_ SG_ 465 StatusUWBRangingFDD2FBD_VR_Sta_3 "contains Status Responder 9";
CM_ SG_ 465 StatusUWBRangingFDD2FBD_VR_Ind_4 "contains Index Responder 10";
CM_ SG_ 465 StatusUWBRangingFDD2FBD_VR_Tim_7 "contains Time Stamp Responder 10";
CM_ SG_ 465 StatusUWBRangingFDD2FBD_VR_Tim_8 "contains Time Stamp Uncertainty Responder 10";
CM_ SG_ 465 StatusUWBRangingFDD2FBD_VR_Sta_4 "contains Status Responder 10";
CM_ SG_ 465 StatusUWBRangingFDD2FBD_VR_Tim_9 "UWB TimeStamp of Poll";
CM_ SG_ 465 StatusUWBRangingFDD2FBD_VR_Signa "contains signature, only signal TAG 0xFF possible";
CM_ SG_ 465 StatusUWBRangingFDD2FBD_VR_IV2 "contains initialisation vector byte2";
CM_ SG_ 465 StatusUWBRangingFDD2FBD_VR_IV3 "contains initialisation vector byte3";
CM_ SG_ 176 StatusWakeUpFBDOnlyMode_HL_Power "contains actual power mode of FBD";
CM_ SG_ 171 StatusWakeUpFBDOnlyMode_HM_Power "contains actual power mode of FBD";
CM_ SG_ 177 StatusWakeUpFBDOnlyMode_HR_Power "contains actual power mode of FBD";
CM_ SG_ 172 StatusWakeUpFBDOnlyMode_Miko_Pow "contains actual power mode of FBD";
CM_ SG_ 181 StatusWakeUpFBDOnlyMode_MM_Power "contains actual power mode of FBD";
CM_ SG_ 178 StatusWakeUpFBDOnlyMode_SML_Powe "contains actual power mode of FBD";
CM_ SG_ 179 StatusWakeUpFBDOnlyMode_SMR_Powe "contains actual power mode of FBD";
CM_ SG_ 173 StatusWakeUpFBDOnlyMode_Trunk_Po "contains actual power mode of FBD";
CM_ SG_ 174 StatusWakeUpFBDOnlyMode_VL_Power "contains actual power mode of FBD";
CM_ SG_ 170 StatusWakeUpFBDOnlyMode_VM_Power "contains actual power mode of FBD";
CM_ SG_ 175 StatusWakeUpFBDOnlyMode_VR_Power "contains actual power mode of FBD";
CM_ SG_ 385 StopBLECSSession_Address "addressing of the BLE nodes";
CM_ SG_ 385 StopBLECSSession_ID "defines the channel sounding session ID within the active connection";
CM_ SG_ 385 StopBLECSSession_IRKListID "defines the connected BLE device";
CM_ SG_ 385 StopBLECSSession_DeviceGroup "defines the device group";
CM_ SG_ 116 TimeSyncDeviceOffsetFBD_HL_Sessi "contains Session-ID";
CM_ SG_ 116 TimeSyncDeviceOffsetFBD_HL_IRKLi "contains IRK List-ID";
CM_ SG_ 116 TimeSyncDeviceOffsetFBD_HL_TimeO "contains device offset to TimeSyncData";
CM_ SG_ 116 TimeSyncDeviceOffsetFBD_HL_Tim_2 "contains TimeSync Uncertainty";
CM_ SG_ 116 TimeSyncDeviceOffsetFBD_HL_UWBDe "Time uncertainty between the anchor point of connection event and UWB Clock domain mapping. Value [µsec] = 2^(UWBDeviceTimeUncertainty/8); Range is 1µsec to 1.094 hour.";
CM_ SG_ 116 TimeSyncDeviceOffsetFBD_HL_UWB_2 "Worst case clock skew of device UWB clock (with respect to nominal time), unit is PPM.";
CM_ SG_ 116 TimeSyncDeviceOffsetFBD_HL_UWBCl "Signal to show that device has a clock system which allows the vehicle to estimate and correct for the UWB clock skew, based on DeviceEventCount and UWBDeviceTime. Value = 0: UWB clock skew measurement is NOT available. Value = 1: UWB clock skew measurement is available.";
CM_ SG_ 111 TimeSyncDeviceOffsetFBD_HM_Sessi "contains Session-ID";
CM_ SG_ 111 TimeSyncDeviceOffsetFBD_HM_IRKLi "contains IRK List-ID";
CM_ SG_ 111 TimeSyncDeviceOffsetFBD_HM_TimeO "contains device offset to TimeSyncData";
CM_ SG_ 111 TimeSyncDeviceOffsetFBD_HM_Tim_2 "contains TimeSync Uncertainty";
CM_ SG_ 111 TimeSyncDeviceOffsetFBD_HM_UWBDe "Time uncertainty between the anchor point of connection event and UWB Clock domain mapping. Value [µsec] = 2^(UWBDeviceTimeUncertainty/8); Range is 1µsec to 1.094 hour.";
CM_ SG_ 111 TimeSyncDeviceOffsetFBD_HM_UWB_2 "Worst case clock skew of device UWB clock (with respect to nominal time), unit is PPM.";
CM_ SG_ 111 TimeSyncDeviceOffsetFBD_HM_UWBCl "Signal to show that device has a clock system which allows the vehicle to estimate and correct for the UWB clock skew, based on DeviceEventCount and UWBDeviceTime. Value = 0: UWB clock skew measurement is NOT available. Value = 1: UWB clock skew measurement is available.";
CM_ SG_ 117 TimeSyncDeviceOffsetFBD_HR_Sessi "contains Session-ID";
CM_ SG_ 117 TimeSyncDeviceOffsetFBD_HR_IRKLi "contains IRK List-ID";
CM_ SG_ 117 TimeSyncDeviceOffsetFBD_HR_TimeO "contains device offset to TimeSyncData";
CM_ SG_ 117 TimeSyncDeviceOffsetFBD_HR_Tim_2 "contains TimeSync Uncertainty";
CM_ SG_ 117 TimeSyncDeviceOffsetFBD_HR_UWBDe "Time uncertainty between the anchor point of connection event and UWB Clock domain mapping. Value [µsec] = 2^(UWBDeviceTimeUncertainty/8); Range is 1µsec to 1.094 hour.";
CM_ SG_ 117 TimeSyncDeviceOffsetFBD_HR_UWB_2 "Worst case clock skew of device UWB clock (with respect to nominal time), unit is PPM.";
CM_ SG_ 117 TimeSyncDeviceOffsetFBD_HR_UWBCl "Signal to show that device has a clock system which allows the vehicle to estimate and correct for the UWB clock skew, based on DeviceEventCount and UWBDeviceTime. Value = 0: UWB clock skew measurement is NOT available. Value = 1: UWB clock skew measurement is available.";
CM_ SG_ 112 TimeSyncDeviceOffsetFBD_Miko_Ses "contains Session-ID";
CM_ SG_ 112 TimeSyncDeviceOffsetFBD_Miko_IRK "contains IRK List-ID";
CM_ SG_ 112 TimeSyncDeviceOffsetFBD_Miko_Tim "contains device offset to TimeSyncData";
CM_ SG_ 112 TimeSyncDeviceOffsetFBD_Miko_T_2 "contains TimeSync Uncertainty";
CM_ SG_ 112 TimeSyncDeviceOffsetFBD_Miko_UWB "Time uncertainty between the anchor point of connection event and UWB Clock domain mapping. Value [µsec] = 2^(UWBDeviceTimeUncertainty/8); Range is 1µsec to 1.094 hour.";
CM_ SG_ 112 TimeSyncDeviceOffsetFBD_Miko_U_2 "Worst case clock skew of device UWB clock (with respect to nominal time), unit is PPM.";
CM_ SG_ 112 TimeSyncDeviceOffsetFBD_Miko_U_3 "Signal to show that device has a clock system which allows the vehicle to estimate and correct for the UWB clock skew, based on DeviceEventCount and UWBDeviceTime. Value = 0: UWB clock skew measurement is NOT available. Value = 1: UWB clock skew measurement is available.";
CM_ SG_ 811 TimeSyncDeviceOffsetFBD_MM_Sessi "contains Session-ID";
CM_ SG_ 811 TimeSyncDeviceOffsetFBD_MM_IRKLi "contains IRK List-ID";
CM_ SG_ 811 TimeSyncDeviceOffsetFBD_MM_TimeO "contains device offset to TimeSyncData";
CM_ SG_ 811 TimeSyncDeviceOffsetFBD_MM_Tim_2 "contains TimeSync Uncertainty";
CM_ SG_ 811 TimeSyncDeviceOffsetFBD_MM_UWBDe "Time uncertainty between the anchor point of connection event and UWB Clock domain mapping. Value [µsec] = 2^(UWBDeviceTimeUncertainty/8); Range is 1µsec to 1.094 hour.";
CM_ SG_ 811 TimeSyncDeviceOffsetFBD_MM_UWB_2 "Worst case clock skew of device UWB clock (with respect to nominal time), unit is PPM.";
CM_ SG_ 811 TimeSyncDeviceOffsetFBD_MM_UWBCl "Signal to show that device has a clock system which allows the vehicle to estimate and correct for the UWB clock skew, based on DeviceEventCount and UWBDeviceTime. Value = 0: UWB clock skew measurement is NOT available. Value = 1: UWB clock skew measurement is available.";
CM_ SG_ 118 TimeSyncDeviceOffsetFBD_SML_Sess "contains Session-ID";
CM_ SG_ 118 TimeSyncDeviceOffsetFBD_SML_IRKL "contains IRK List-ID";
CM_ SG_ 118 TimeSyncDeviceOffsetFBD_SML_Time "contains device offset to TimeSyncData";
CM_ SG_ 118 TimeSyncDeviceOffsetFBD_SML_Ti_2 "contains TimeSync Uncertainty";
CM_ SG_ 118 TimeSyncDeviceOffsetFBD_SML_UWBD "Time uncertainty between the anchor point of connection event and UWB Clock domain mapping. Value [µsec] = 2^(UWBDeviceTimeUncertainty/8); Range is 1µsec to 1.094 hour.";
CM_ SG_ 118 TimeSyncDeviceOffsetFBD_SML_UW_2 "Worst case clock skew of device UWB clock (with respect to nominal time), unit is PPM.";
CM_ SG_ 118 TimeSyncDeviceOffsetFBD_SML_UWBC "Signal to show that device has a clock system which allows the vehicle to estimate and correct for the UWB clock skew, based on DeviceEventCount and UWBDeviceTime. Value = 0: UWB clock skew measurement is NOT available. Value = 1: UWB clock skew measurement is available.";
CM_ SG_ 119 TimeSyncDeviceOffsetFBD_SMR_Sess "contains Session-ID";
CM_ SG_ 119 TimeSyncDeviceOffsetFBD_SMR_IRKL "contains IRK List-ID";
CM_ SG_ 119 TimeSyncDeviceOffsetFBD_SMR_Time "contains device offset to TimeSyncData";
CM_ SG_ 119 TimeSyncDeviceOffsetFBD_SMR_Ti_2 "contains TimeSync Uncertainty";
CM_ SG_ 119 TimeSyncDeviceOffsetFBD_SMR_UWBD "Time uncertainty between the anchor point of connection event and UWB Clock domain mapping. Value [µsec] = 2^(UWBDeviceTimeUncertainty/8); Range is 1µsec to 1.094 hour.";
CM_ SG_ 119 TimeSyncDeviceOffsetFBD_SMR_UW_2 "Worst case clock skew of device UWB clock (with respect to nominal time), unit is PPM.";
CM_ SG_ 119 TimeSyncDeviceOffsetFBD_SMR_UWBC "Signal to show that device has a clock system which allows the vehicle to estimate and correct for the UWB clock skew, based on DeviceEventCount and UWBDeviceTime. Value = 0: UWB clock skew measurement is NOT available. Value = 1: UWB clock skew measurement is available.";
CM_ SG_ 113 TimeSyncDeviceOffsetFBD_Trunk_Se "contains Session-ID";
CM_ SG_ 113 TimeSyncDeviceOffsetFBD_Trunk_IR "contains IRK List-ID";
CM_ SG_ 113 TimeSyncDeviceOffsetFBD_Trunk_Ti "contains device offset to TimeSyncData";
CM_ SG_ 113 TimeSyncDeviceOffsetFBD_Trunk__2 "contains TimeSync Uncertainty";
CM_ SG_ 113 TimeSyncDeviceOffsetFBD_Trunk_UW "Time uncertainty between the anchor point of connection event and UWB Clock domain mapping. Value [µsec] = 2^(UWBDeviceTimeUncertainty/8); Range is 1µsec to 1.094 hour.";
CM_ SG_ 113 TimeSyncDeviceOffsetFBD_Trunk__3 "Worst case clock skew of device UWB clock (with respect to nominal time), unit is PPM.";
CM_ SG_ 113 TimeSyncDeviceOffsetFBD_Trunk__4 "Signal to show that device has a clock system which allows the vehicle to estimate and correct for the UWB clock skew, based on DeviceEventCount and UWBDeviceTime. Value = 0: UWB clock skew measurement is NOT available. Value = 1: UWB clock skew measurement is available.";
CM_ SG_ 114 TimeSyncDeviceOffsetFBD_VL_Sessi "contains Session-ID";
CM_ SG_ 114 TimeSyncDeviceOffsetFBD_VL_IRKLi "contains IRK List-ID";
CM_ SG_ 114 TimeSyncDeviceOffsetFBD_VL_TimeO "contains device offset to TimeSyncData";
CM_ SG_ 114 TimeSyncDeviceOffsetFBD_VL_Tim_2 "contains TimeSync Uncertainty";
CM_ SG_ 114 TimeSyncDeviceOffsetFBD_VL_UWBDe "Time uncertainty between the anchor point of connection event and UWB Clock domain mapping. Value [µsec] = 2^(UWBDeviceTimeUncertainty/8); Range is 1µsec to 1.094 hour.";
CM_ SG_ 114 TimeSyncDeviceOffsetFBD_VL_UWB_2 "Worst case clock skew of device UWB clock (with respect to nominal time), unit is PPM.";
CM_ SG_ 114 TimeSyncDeviceOffsetFBD_VL_UWBCl "Signal to show that device has a clock system which allows the vehicle to estimate and correct for the UWB clock skew, based on DeviceEventCount and UWBDeviceTime. Value = 0: UWB clock skew measurement is NOT available. Value = 1: UWB clock skew measurement is available.";
CM_ SG_ 110 TimeSyncDeviceOffsetFBD_VM_Sessi "contains Session-ID";
CM_ SG_ 110 TimeSyncDeviceOffsetFBD_VM_IRKLi "contains IRK List-ID";
CM_ SG_ 110 TimeSyncDeviceOffsetFBD_VM_TimeO "contains device offset to TimeSyncData";
CM_ SG_ 110 TimeSyncDeviceOffsetFBD_VM_Tim_2 "contains TimeSync Uncertainty";
CM_ SG_ 110 TimeSyncDeviceOffsetFBD_VM_UWBDe "Time uncertainty between the anchor point of connection event and UWB Clock domain mapping. Value [µsec] = 2^(UWBDeviceTimeUncertainty/8); Range is 1µsec to 1.094 hour.";
CM_ SG_ 110 TimeSyncDeviceOffsetFBD_VM_UWB_2 "Worst case clock skew of device UWB clock (with respect to nominal time), unit is PPM.";
CM_ SG_ 110 TimeSyncDeviceOffsetFBD_VM_UWBCl "Signal to show that device has a clock system which allows the vehicle to estimate and correct for the UWB clock skew, based on DeviceEventCount and UWBDeviceTime. Value = 0: UWB clock skew measurement is NOT available. Value = 1: UWB clock skew measurement is available.";
CM_ SG_ 115 TimeSyncDeviceOffsetFBD_VR_Sessi "contains Session-ID";
CM_ SG_ 115 TimeSyncDeviceOffsetFBD_VR_IRKLi "contains IRK List-ID";
CM_ SG_ 115 TimeSyncDeviceOffsetFBD_VR_TimeO "contains device offset to TimeSyncData";
CM_ SG_ 115 TimeSyncDeviceOffsetFBD_VR_Tim_2 "contains TimeSync Uncertainty";
CM_ SG_ 115 TimeSyncDeviceOffsetFBD_VR_UWBDe "Time uncertainty between the anchor point of connection event and UWB Clock domain mapping. Value [µsec] = 2^(UWBDeviceTimeUncertainty/8); Range is 1µsec to 1.094 hour.";
CM_ SG_ 115 TimeSyncDeviceOffsetFBD_VR_UWB_2 "Worst case clock skew of device UWB clock (with respect to nominal time), unit is PPM.";
CM_ SG_ 115 TimeSyncDeviceOffsetFBD_VR_UWBCl "Signal to show that device has a clock system which allows the vehicle to estimate and correct for the UWB clock skew, based on DeviceEventCount and UWBDeviceTime. Value = 0: UWB clock skew measurement is NOT available. Value = 1: UWB clock skew measurement is available.";
CM_ SG_ 106 TimeSyncFBD_HL_SyncTime "contains TimeSyncData";
CM_ SG_ 101 TimeSyncFBD_HM_SyncTime "contains TimeSyncData";
CM_ SG_ 107 TimeSyncFBD_HR_SyncTime "contains TimeSyncData";
CM_ SG_ 102 TimeSyncFBD_Miko_SyncTime "contains TimeSyncData";
CM_ SG_ 810 TimeSyncFBD_MM_SyncTime "contains TimeSyncData";
CM_ SG_ 108 TimeSyncFBD_SML_SyncTime "contains TimeSyncData";
CM_ SG_ 109 TimeSyncFBD_SMR_SyncTime "contains TimeSyncData";
CM_ SG_ 103 TimeSyncFBD_Trunk_SyncTime "contains TimeSyncData";
CM_ SG_ 104 TimeSyncFBD_VL_SyncTime "contains TimeSyncData";
CM_ SG_ 100 TimeSyncFBD_VM_SyncTime "contains TimeSyncData";
CM_ SG_ 105 TimeSyncFBD_VR_SyncTime "contains TimeSyncData";

BA_DEF_ BO_ "VFrameFormat" ENUM "StandardCAN","ExtendedCAN","reserved","J1939PG","reserved","reserved","reserved","reserved","reserved","reserved","reserved","reserved","reserved","reserved","StandardCAN_FD","ExtendedCAN_FD";
BA_DEF_DEF_ "VFrameFormat" "StandardCAN";
BA_ "VFrameFormat" BO_ 435 14;
BA_ "VFrameFormat" BO_ 456 14;
BA_ "VFrameFormat" BO_ 451 14;
BA_ "VFrameFormat" BO_ 457 14;
BA_ "VFrameFormat" BO_ 452 14;
BA_ "VFrameFormat" BO_ 444 14;
BA_ "VFrameFormat" BO_ 458 14;
BA_ "VFrameFormat" BO_ 459 14;
BA_ "VFrameFormat" BO_ 453 14;
BA_ "VFrameFormat" BO_ 454 14;
BA_ "VFrameFormat" BO_ 450 14;
BA_ "VFrameFormat" BO_ 455 14;
BA_ "VFrameFormat" BO_ 466 14;
BA_ "VFrameFormat" BO_ 461 14;
BA_ "VFrameFormat" BO_ 467 14;
BA_ "VFrameFormat" BO_ 462 14;
BA_ "VFrameFormat" BO_ 445 14;
BA_ "VFrameFormat" BO_ 468 14;
BA_ "VFrameFormat" BO_ 469 14;
BA_ "VFrameFormat" BO_ 463 14;
BA_ "VFrameFormat" BO_ 464 14;
BA_ "VFrameFormat" BO_ 460 14;
BA_ "VFrameFormat" BO_ 465 14;
BA_ "VFrameFormat" BO_ 116 14;
BA_ "VFrameFormat" BO_ 111 14;
BA_ "VFrameFormat" BO_ 117 14;
BA_ "VFrameFormat" BO_ 112 14;
BA_ "VFrameFormat" BO_ 811 14;
BA_ "VFrameFormat" BO_ 118 14;
BA_ "VFrameFormat" BO_ 119 14;
BA_ "VFrameFormat" BO_ 113 14;
BA_ "VFrameFormat" BO_ 114 14;
BA_ "VFrameFormat" BO_ 110 14;
BA_ "VFrameFormat" BO_ 115 14;
BA_ "VFrameFormat" BO_ 516 14;
BA_ "VFrameFormat" BO_ 511 14;
BA_ "VFrameFormat" BO_ 517 14;
BA_ "VFrameFormat" BO_ 512 14;
BA_ "VFrameFormat" BO_ 521 14;
